VERSION "dbc-export 1 2026.26.6.5"

NS_ :

BS_:

BU_: APP BMS CC CMP CMPD CP DAS DI DIF DIR EPBL EPBR EVSE FC GTW HCML HCMR HVP ICR PCS PCS2 PM PMF PMR PTC SCCM SDCR TAS UMC V2G VC VCBATT VCBATT1 VCBATT2 VCFRONT VCFRONT1 VCLEFT VCRIGHT VCSEC

BO_ 530 BMS_status: 8 BMS
 SG_ BMS_hvacPowerRequest : 0|1@1+ (1,0) [0|1] "" Vector__XXX
 SG_ BMS_notEnoughPowerForDrive : 1|1@1+ (1,0) [0|1] "" Vector__XXX
 SG_ BMS_notEnoughPowerForSupport : 2|1@1+ (1,0) [0|1] "" Vector__XXX
 SG_ BMS_preconditionAllowed : 3|1@1+ (1,0) [0|1] "" Vector__XXX
 SG_ BMS_updateAllowed : 4|1@1+ (1,0) [0|1] "" Vector__XXX
 SG_ BMS_cpMiaOnHvs : 5|1@1+ (1,0) [0|1] "" Vector__XXX
 SG_ BMS_pcsPwmEnabled : 6|1@1+ (1,0) [0|1] "" Vector__XXX
 SG_ BMS_contactorState : 8|3@1+ (1,0) [1|7] "" Vector__XXX
 SG_ BMS_userChargeStatus : 11|3@1+ (1,0) [0|7] "" Vector__XXX
 SG_ BMS_batteryInputPower : 14|16@1+ (0.05,0) [0|3276.7] "kW" Vector__XXX
 SG_ BMS_chargeRequest : 30|1@1+ (1,0) [0|1] "" Vector__XXX
 SG_ BMS_state : 32|4@1+ (1,0) [0|15] "" Vector__XXX
 SG_ BMS_diLimpRequest : 36|1@1+ (1,0) [0|1] "" Vector__XXX
 SG_ BMS_okToShipByAir : 37|1@1+ (1,0) [0|1] "" Vector__XXX
 SG_ BMS_okToShipByLand : 38|1@1+ (1,0) [0|1] "" Vector__XXX
 SG_ BMS_chgPowerAvailable : 39|12@1+ (0.125,0) [0|511.75] "kW" Vector__XXX
 SG_ BMS_acManagerState : 52|4@1+ (1,0) [0|15] "" Vector__XXX
 SG_ BMS_conditioningRequest : 56|1@1+ (1,0) [0|1] "" Vector__XXX
 SG_ BMS_smStateRequest : 57|4@1+ (1,0) [0|15] "" Vector__XXX
 SG_ BMS_hvState : 61|3@1+ (1,0) [0|7] "" Vector__XXX

BO_ 786 BMS_thermalStatus: 8 BMS
 SG_ BMS_thermalStatusMultiplexer M : 0|2@1+ (1,0) [0|3] "" Vector__XXX
 SG_ BMS_inletActiveCoolTargetT m0 : 2|9@1+ (0.25,-25) [-25|100] "DegC" Vector__XXX
 SG_ BMS_inletPassiveTargetT m0 : 11|9@1+ (0.25,-25) [-25|100] "DegC" Vector__XXX
 SG_ BMS_inletActiveHeatTargetT m0 : 20|9@1+ (0.25,-25) [-25|100] "DegC" Vector__XXX
 SG_ BMS_requestDischarge m0 : 29|1@1+ (1,0) [0|1] "" Vector__XXX
 SG_ BMS_activeHeatingWorthwhile m0 : 30|1@1+ (1,0) [0|1] "" Vector__XXX
 SG_ BMS_pcsNoFlowRequest m0 : 31|1@1+ (1,0) [0|1] "" Vector__XXX
 SG_ BMS_minPackTemperature m0 : 32|10@1+ (0.2,-40) [-40|164.6] "DegC" Vector__XXX
 SG_ BMS_noFlowRequest m0 : 42|1@1+ (1,0) [0|1] "" Vector__XXX
 SG_ BMS_maxPackTemperature m0 : 43|11@1+ (0.1,-40) [-40|164.7] "DegC" Vector__XXX
 SG_ BMS_flowRequest m0 : 56|8@1+ (0.25,0) [0|60] "LPM" Vector__XXX
 SG_ BMS_coldStagnationLimit m1 : 2|9@1+ (0.25,-25) [-25|100] "DegC" Vector__XXX
 SG_ BMS_hotStagnationLimit m1 : 11|9@1+ (0.25,-25) [-25|100] "DegC" Vector__XXX
 SG_ BMS_hotCellTempLimit m1 : 20|9@1+ (0.25,-25) [-25|100] "DegC" Vector__XXX
 SG_ BMS_i2tDeratingEnabled m1 : 29|1@1+ (1,0) [0|1] "" Vector__XXX
 SG_ BMS_activeCoolCellReferenceT m1 : 32|9@1+ (0.25,-25) [-25|100] "DegC" Vector__XXX
 SG_ BMS_activeHeatCellTargetT m1 : 41|9@1+ (0.25,-25) [-25|100] "DegC" Vector__XXX
 SG_ BMS_powerDissipation m1 : 50|10@1+ (0.02,0) [0|20] "kW" Vector__XXX

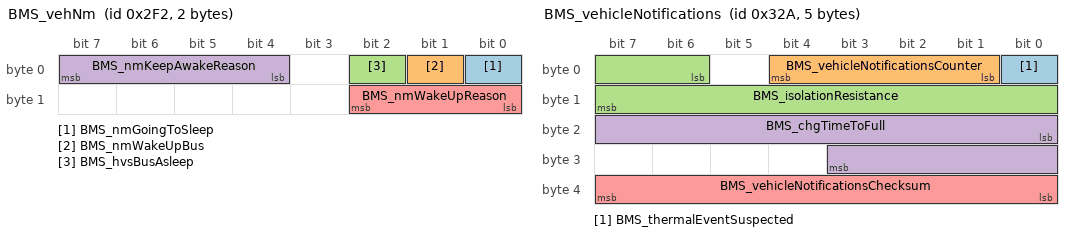
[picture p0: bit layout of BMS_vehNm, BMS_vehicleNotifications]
BO_ 754 BMS_vehNm: 2 BMS
 SG_ BMS_nmGoingToSleep : 0|1@1+ (1,0) [0|1] "" Vector__XXX
 SG_ BMS_nmWakeUpBus : 1|1@1+ (1,0) [0|1] "" Vector__XXX
 SG_ BMS_hvsBusAsleep : 2|1@1+ (1,0) [0|1] "" Vector__XXX
 SG_ BMS_nmKeepAwakeReason : 4|4@1+ (1,0) [1|15] "" Vector__XXX
 SG_ BMS_nmWakeUpReason : 8|3@1+ (1,0) [0|7] "" Vector__XXX

BO_ 810 BMS_vehicleNotifications: 5 BMS
 SG_ BMS_thermalEventSuspected : 0|1@1+ (1,0) [0|1] "" Vector__XXX
 SG_ BMS_vehicleNotificationsCounter : 1|4@1+ (1,0) [0|15] "" Vector__XXX
 SG_ BMS_isolationResistance : 6|10@1+ (10,0) [0|10000] "kOhm" Vector__XXX
 SG_ BMS_chgTimeToFull : 16|12@1+ (0.01666667,0) [0|68.23334698] "Hours" Vector__XXX
 SG_ BMS_vehicleNotificationsChecksum : 32|8@1+ (1,0) [0|255] "" Vector__XXX

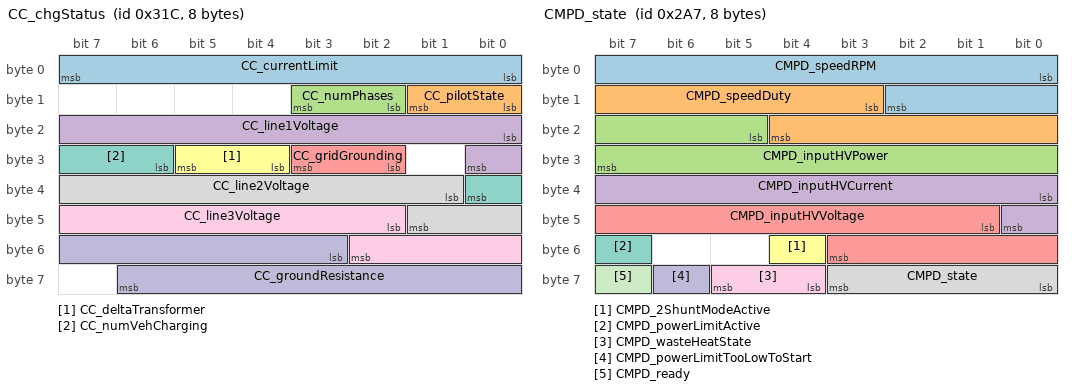
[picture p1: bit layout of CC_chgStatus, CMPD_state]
BO_ 796 CC_chgStatus: 8 CC
 SG_ CC_currentLimit : 0|8@1+ (0.5,0) [0|127] "A" Vector__XXX
 SG_ CC_pilotState : 8|2@1+ (1,0) [0|2] "" Vector__XXX
 SG_ CC_numPhases : 10|2@1+ (1,0) [1|3] "" Vector__XXX
 SG_ CC_line1Voltage : 16|9@1+ (1,0) [0|510] "V" Vector__XXX
 SG_ CC_gridGrounding : 26|2@1+ (1,0) [0|3] "" Vector__XXX
 SG_ CC_deltaTransformer : 28|2@1+ (1,0) [0|3] "" Vector__XXX
 SG_ CC_numVehCharging : 30|3@1+ (1,0) [0|7] "" Vector__XXX
 SG_ CC_line2Voltage : 33|9@1+ (1,0) [0|510] "V" Vector__XXX
 SG_ CC_line3Voltage : 42|9@1+ (1,0) [0|510] "V" Vector__XXX
 SG_ CC_groundResistance : 51|12@1+ (1,0) [0|4094] "kOhm" Vector__XXX

BO_ 797 CC_chgStatus2: 8 CC
 SG_ CC_chgStatus2Index M : 0|8@1+ (1,0) [0|255] "" Vector__XXX
 SG_ CC_buttonState m0 : 8|1@1+ (1,0) [0|1] "" Vector__XXX
 SG_ EVSE_v2xSupport m0 : 9|2@1+ (1,0) [0|3] "" Vector__XXX
 SG_ EVSE_v2xHandshakeStart m0 : 12|1@1+ (1,0) [0|1] "" Vector__XXX
 SG_ EVSE_v2xSessionType m0 : 13|2@1+ (1,0) [1|3] "" Vector__XXX

BO_ 812 CC_logData: 8 CC
 SG_ CC_logIndex M : 0|8@1+ (1,0) [0|255] "" Vector__XXX
 SG_ CC_activeConnectorID m0 : 8|8@1+ (1,0) [0|255] "" Vector__XXX
 SG_ CC_temperature1 m0 : 16|8@1- (1,88) [-40|215] "DegC" Vector__XXX
 SG_ CC_temperature2 m0 : 24|8@1- (1,88) [-40|215] "DegC" Vector__XXX
 SG_ CC_temperature3 m0 : 32|8@1- (1,88) [-40|215] "DegC" Vector__XXX
 SG_ CC_contactor1Closed m0 : 40|2@1+ (1,0) [0|3] "" Vector__XXX
 SG_ CC_contactor2Closed m0 : 42|2@1+ (1,0) [0|3] "" Vector__XXX
 SG_ CC_temperature4 m0 : 44|8@1- (1,88) [-40|215] "DegC" Vector__XXX
 SG_ CC_conn1Current m1 : 8|8@1+ (0.5,0) [0|127] "A" Vector__XXX
 SG_ CC_conn2Current m2 : 8|8@1+ (0.5,0) [0|127] "A" Vector__XXX
 SG_ CC_conn3Current m3 : 8|8@1+ (0.5,0) [0|127] "A" Vector__XXX
 SG_ CC_conn4Current m4 : 8|8@1+ (0.5,0) [0|127] "A" Vector__XXX
 SG_ CC_lifetimei2t m10 : 32|32@1+ (0.1,0) [0|429496729.5] "A2h" Vector__XXX
 SG_ CC_lifetimeCtrCycles m11 : 8|28@1+ (1,0) [0|268435455] "" Vector__XXX
 SG_ CC_lifetimeCtrCyclesLoaded m11 : 36|28@1+ (1,0) [0|268435455] "" Vector__XXX
 SG_ CC_lifetimeAlertCount m12 : 8|28@1+ (1,0) [0|268435455] "" Vector__XXX
 SG_ CC_lifetimeThermalFoldbacks m12 : 36|28@1+ (1,0) [0|268435455] "" Vector__XXX
 SG_ CC_lifetimeAvgStartupTemp m13 : 36|28@1- (0.1,0) [-13421772.8|13421772.7] "degC" Vector__XXX

BO_ 870 CMPD_info: 8 CMPD
 SG_ CMPD_infoIndex M : 0|8@1+ (1,0) [0|255] "" Vector__XXX
 SG_ CMPD_infoBuildType m10 : 8|8@1+ (1,0) [0|255] "" Vector__XXX
 SG_ CMPD_infoBuildConfigId m10 : 16|16@1+ (1,0) [0|65535] "" Vector__XXX
 SG_ CMPD_infoHardwareId m10 : 32|16@1+ (1,0) [0|65535] "" Vector__XXX
 SG_ CMPD_infoComponentId m10 : 48|16@1+ (1,0) [0|65535] "" Vector__XXX
 SG_ CMPD_infoPcbaId m11 : 16|8@1+ (1,0) [0|255] "" Vector__XXX
 SG_ CMPD_infoAssemblyId m11 : 24|8@1+ (1,0) [0|254] "" Vector__XXX
 SG_ CMPD_infoUsageId m11 : 32|16@1+ (1,0) [0|65535] "" Vector__XXX
 SG_ CMPD_infoSubUsageId m11 : 48|16@1+ (1,0) [0|65535] "" Vector__XXX

BO_ 679 CMPD_state: 8 CMPD
 SG_ CMPD_speedRPM : 0|11@1+ (10,0) [0|20000] "RPM" Vector__XXX
 SG_ CMPD_speedDuty : 11|10@1+ (0.1,0) [0|100] "%" Vector__XXX
 SG_ CMPD_inputHVPower : 21|11@1+ (10,0) [0|20000] "W" Vector__XXX
 SG_ CMPD_inputHVCurrent : 32|9@1+ (0.1,0) [0|50] "A" Vector__XXX
 SG_ CMPD_inputHVVoltage : 41|11@1+ (0.5,0) [0|1000] "V" Vector__XXX
 SG_ CMPD_2ShuntModeActive : 52|1@1+ (1,0) [0|1] "" Vector__XXX
 SG_ CMPD_powerLimitActive : 55|1@1+ (1,0) [0|1] "" Vector__XXX
 SG_ CMPD_state : 56|4@1+ (1,0) [0|14] "" Vector__XXX
 SG_ CMPD_wasteHeatState : 60|2@1+ (1,0) [0|3] "" Vector__XXX
 SG_ CMPD_powerLimitTooLowToStart : 62|1@1+ (1,0) [0|1] "" Vector__XXX
 SG_ CMPD_ready : 63|1@1+ (1,0) [0|1] "" Vector__XXX

BO_ 867 CMP_info: 8 CMP
 SG_ CMP_infoIndex M : 0|8@1+ (1,0) [0|255] "" Vector__XXX
 SG_ CMP_infoBuildType m10 : 8|8@1+ (1,0) [0|255] "" Vector__XXX
 SG_ CMP_infoBuildConfigId m10 : 16|16@1+ (1,0) [0|65535] "" Vector__XXX
 SG_ CMP_infoHardwareId m10 : 32|16@1+ (1,0) [0|65535] "" Vector__XXX
 SG_ CMP_infoComponentId m10 : 48|16@1+ (1,0) [0|65535] "" Vector__XXX
 SG_ CMP_infoPcbaId m11 : 16|8@1+ (1,0) [0|255] "" Vector__XXX
 SG_ CMP_infoAssemblyId m11 : 24|8@1+ (1,0) [0|254] "" Vector__XXX
 SG_ CMP_infoUsageId m11 : 32|16@1+ (1,0) [0|65535] "" Vector__XXX
 SG_ CMP_infoSubUsageId m11 : 48|16@1+ (1,0) [0|65535] "" Vector__XXX
 SG_ CMP_infoPlatformType m13 : 8|8@1+ (1,0) [0|255] "" Vector__XXX
 SG_ CMP_infoAppCrc m13 : 32|32@1+ (1,0) [0|4294967295] "" Vector__XXX
 SG_ CMP_infoBootUdsProtoVersion m20 : 8|8@1+ (1,0) [0|255] "" Vector__XXX
 SG_ CMP_infoBootCrc m20 : 32|32@1+ (1,0) [0|4294967295] "" Vector__XXX

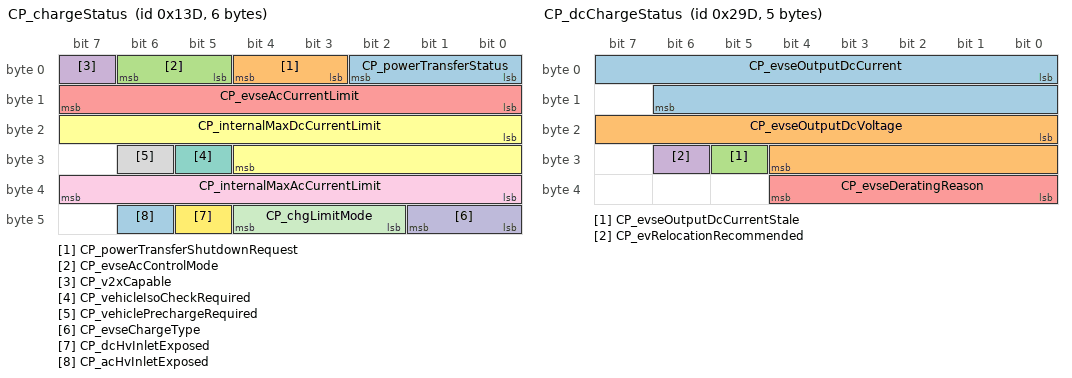
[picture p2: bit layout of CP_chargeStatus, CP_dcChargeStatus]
BO_ 317 CP_chargeStatus: 6 CP
 SG_ CP_powerTransferStatus : 0|3@1+ (1,0) [0|7] "" Vector__XXX
 SG_ CP_powerTransferShutdownRequest : 3|2@1+ (1,0) [0|3] "" Vector__XXX
 SG_ CP_evseAcControlMode : 5|2@1+ (1,0) [0|3] "" Vector__XXX
 SG_ CP_v2xCapable : 7|1@1+ (1,0) [0|1] "" Vector__XXX
 SG_ CP_evseAcCurrentLimit : 8|8@1+ (0.5,0) [0|127.5] "A" Vector__XXX
 SG_ CP_internalMaxDcCurrentLimit : 16|13@1+ (0.25,0) [0|2047.75] "A" Vector__XXX
 SG_ CP_vehicleIsoCheckRequired : 29|1@1+ (1,0) [0|1] "" Vector__XXX
 SG_ CP_vehiclePrechargeRequired : 30|1@1+ (1,0) [0|1] "" Vector__XXX
 SG_ CP_internalMaxAcCurrentLimit : 32|8@1+ (0.5,0) [0|127.5] "A" Vector__XXX
 SG_ CP_evseChargeType : 40|2@1+ (1,0) [0|3] "" Vector__XXX
 SG_ CP_chgLimitMode : 42|3@1+ (1,0) [0|7] "" Vector__XXX
 SG_ CP_dcHvInletExposed : 45|1@1+ (1,0) [0|1] "" Vector__XXX
 SG_ CP_acHvInletExposed : 46|1@1+ (1,0) [0|1] "" Vector__XXX

BO_ 669 CP_dcChargeStatus: 5 CP
 SG_ CP_evseOutputDcCurrent : 0|15@1- (0.125,0) [-2048|2047.875] "A" Vector__XXX
 SG_ CP_evseOutputDcVoltage : 16|13@1+ (0.07324219,0) [0|599.92675822] "V" Vector__XXX
 SG_ CP_evseOutputDcCurrentStale : 29|1@1+ (1,0) [0|1] "" Vector__XXX
 SG_ CP_evRelocationRecommended : 30|1@1+ (1,0) [0|1] "" Vector__XXX
 SG_ CP_evseDeratingReason : 32|5@1+ (1,0) [0|31] "" Vector__XXX

BO_ 541 CP_evseStatus: 8 CP
 SG_ CP_evseAccept : 0|1@1+ (1,0) [0|1] "" Vector__XXX
 SG_ CP_evseRequest : 1|1@1+ (1,0) [0|1] "" Vector__XXX
 SG_ CP_proximity : 2|2@1+ (1,0) [1|3] "" Vector__XXX
 SG_ CP_pilot : 4|3@1+ (1,0) [0|6] "" Vector__XXX
 SG_ CP_digitalCommsEstablished : 7|1@1+ (1,0) [0|1] "" Vector__XXX
 SG_ CP_pilotCurrent : 8|8@1+ (0.5,0) [0|127.5] "A" Vector__XXX
 SG_ CP_cableType : 16|3@1+ (1,0) [0|7] "" Vector__XXX
 SG_ CP_iecPilotState : 19|4@1+ (1,0) [0|15] "" Vector__XXX
 SG_ CP_plcSupported : 23|1@1+ (1,0) [0|1] "" Vector__XXX
 SG_ CP_cableCurrentLimit : 24|7@1+ (1,0) [0|127] "A" Vector__XXX
 SG_ CP_teslaSwcanState : 34|4@1+ (1,0) [0|15] "" Vector__XXX
 SG_ CP_evseChargeType_UI : 38|2@1+ (1,0) [0|3] "" Vector__XXX
 SG_ CP_gbState : 40|4@1+ (1,0) [0|15] "" Vector__XXX
 SG_ CP_gbdcStopChargeReason : 44|4@1+ (1,0) [0|15] "" Vector__XXX
 SG_ CP_gbdcFailureReason : 48|2@1+ (1,0) [0|3] "" Vector__XXX
 SG_ CP_gbdcChargeAttempts : 50|2@1+ (1,0) [0|3] "" Vector__XXX
 SG_ CP_acChargeState : 52|3@1+ (1,0) [0|7] "" Vector__XXX
 SG_ CP_acChargeType : 56|2@1+ (1,0) [0|3] "" Vector__XXX
 SG_ CP_teslaDcState : 58|4@1+ (1,0) [0|15] "" Vector__XXX

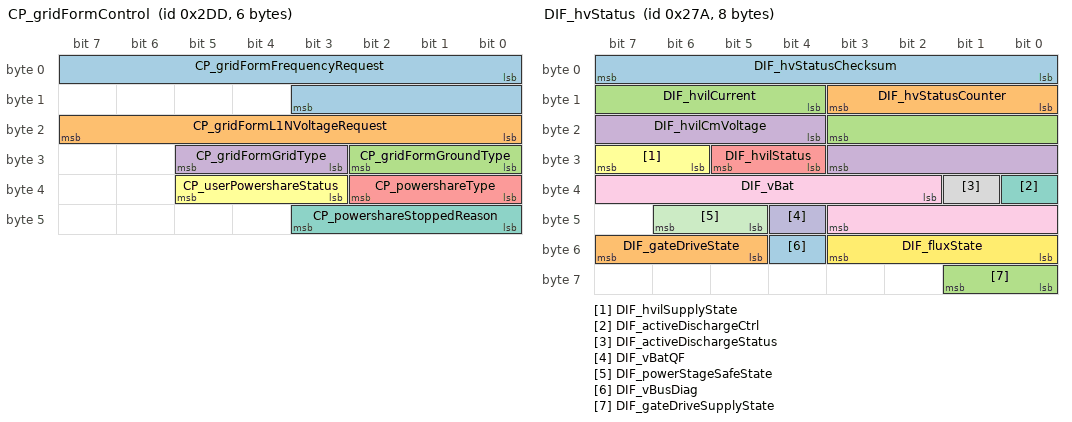
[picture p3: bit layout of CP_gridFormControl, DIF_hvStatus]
BO_ 733 CP_gridFormControl: 6 CP
 SG_ CP_gridFormFrequencyRequest : 0|12@1+ (0.01,40) [40|80.94] "Hz" Vector__XXX
 SG_ CP_gridFormL1NVoltageRequest : 16|8@1+ (1,40) [40|294] "V" Vector__XXX
 SG_ CP_gridFormGroundType : 24|3@1+ (1,0) [1|7] "" Vector__XXX
 SG_ CP_gridFormGridType : 27|3@1+ (1,0) [1|7] "" Vector__XXX
 SG_ CP_powershareType : 32|3@1+ (1,0) [0|7] "" Vector__XXX
 SG_ CP_userPowershareStatus : 35|3@1+ (1,0) [0|7] "" Vector__XXX
 SG_ CP_powershareStoppedReason : 40|4@1+ (1,0) [0|15] "" Vector__XXX

BO_ 1342 CP_info: 8 CP
 SG_ CP_infoIndex M : 0|8@1+ (1,0) [0|255] "" Vector__XXX
 SG_ CP_buildType m10 : 8|3@1+ (1,0) [0|7] "" Vector__XXX
 SG_ CP_buildConfigId m10 : 16|16@1+ (1,0) [0|65535] "" Vector__XXX
 SG_ CP_hardwareId m10 : 32|16@1+ (1,0) [0|65535] "" Vector__XXX
 SG_ CP_componentId m10 : 48|16@1+ (1,0) [0|65535] "" Vector__XXX
 SG_ CP_pcbaId m11 : 16|8@1+ (1,0) [0|255] "" Vector__XXX
 SG_ CP_assemblyId m11 : 24|8@1+ (1,0) [0|255] "" Vector__XXX
 SG_ CP_usageId m11 : 32|16@1+ (1,0) [0|65535] "" Vector__XXX
 SG_ CP_subUsageId m11 : 48|16@1+ (1,0) [0|65535] "" Vector__XXX
 SG_ CP_platformType m13 : 8|8@1+ (1,0) [0|255] "" Vector__XXX
 SG_ CP_appCrc m13 : 32|32@1+ (1,0) [0|4294967295] "" Vector__XXX
 SG_ CP_appGitHash m17 : 8|56@1+ (1,0) [0|7.20575940379e+16] "" Vector__XXX
 SG_ CP_bootGitHash m18 : 8|56@1+ (1,0) [0|7.20575940379e+16] "" Vector__XXX
 SG_ CP_bootUdsProtoVersion m20 : 8|8@1+ (1,0) [0|255] "" Vector__XXX
 SG_ CP_bootCrc m20 : 32|32@1+ (1,0) [0|4294967295] "" Vector__XXX

BO_ 1885 CP_loggingFast: 8 CP
 SG_ CP_loggingFastSelect M : 0|4@1+ (1,0) [0|15] "" Vector__XXX
 SG_ CP_inductiveSensor_raw m0 : 4|28@1+ (1,0) [0|268435455] "" Vector__XXX
 SG_ CP_doorOpenActuationTime m0 : 32|14@1+ (1,0) [0|16383] "ms" Vector__XXX
 SG_ CP_doorCloseActuationTime m0 : 46|14@1+ (1,0) [0|16383] "ms" Vector__XXX
 SG_ CP_chargeCableSecured m0 : 60|1@1+ (1,0) [0|1] "" Vector__XXX
 SG_ CP_chargeCablePresent m0 : 61|1@1+ (1,0) [0|1] "" Vector__XXX
 SG_ CP_latchCheckAvailable m0 : 62|1@1+ (1,0) [0|1] "" Vector__XXX
 SG_ CP_UHF_controlState m2 : 4|4@1+ (1,0) [0|15] "" Vector__XXX
 SG_ CP_proximityV m2 : 8|16@1+ (0.0001,0) [0|6.5535] "V" Vector__XXX
 SG_ CP_proximityV_GBCC1 m2 : 24|14@1+ (0.001,0) [0|13.3] "V" Vector__XXX
 SG_ CP_proximityV_GBCC2 m2 : 38|14@1+ (0.001,0) [0|13.3] "V" Vector__XXX
 SG_ CP_doorPot m2 : 52|12@1+ (0.025,0) [0|100] "%" Vector__XXX
 SG_ CP_doorPresenceSensorV m3 : 4|12@1+ (0.001221,0) [0|4.999995] "V" Vector__XXX
 SG_ CP_doorOpenRequest m3 : 16|4@1+ (1,0) [0|15] "" Vector__XXX
 SG_ CP_doorOpenEndOfDriveReason m3 : 20|3@1+ (1,0) [0|7] "" Vector__XXX
 SG_ CP_coverClosed m3 : 23|1@1+ (1,0) [0|1] "" Vector__XXX
 SG_ CP_doorCloseEndOfDriveReason m3 : 24|3@1+ (1,0) [0|7] "" Vector__XXX
 SG_ CP_doorCloseRequest m3 : 27|5@1+ (1,0) [0|31] "" Vector__XXX
 SG_ CP_latchDisengagingTime m3 : 32|10@1+ (1,0) [0|1023] "ms" Vector__XXX
 SG_ CP_latchEngagingTime m3 : 42|10@1+ (1,0) [0|1023] "ms" Vector__XXX
 SG_ CP_latchDisengagingStopReason m3 : 52|3@1+ (1,0) [0|7] "" Vector__XXX
 SG_ CP_latchEngagingStopReason m3 : 55|3@1+ (1,0) [0|7] "" Vector__XXX
 SG_ CP_pilotUnlatchRequestActive m3 : 58|1@1+ (1,0) [0|1] "" Vector__XXX
 SG_ CP_doorIdDetectionState m3 : 59|2@1+ (1,0) [1|3] "" Vector__XXX
 SG_ CP_doorIdDetectedBin m3 : 61|2@1+ (1,0) [0|3] "" Vector__XXX
 SG_ CP_semiV2LatchNonLinear m3 : 63|1@1+ (1,0) [0|1] "" Vector__XXX

BO_ 989 CP_loggingSlow: 8 CP
 SG_ CP_loggingSlowSelect M : 0|4@1+ (1,0) [0|15] "" Vector__XXX
 SG_ CP_UHF_chipState m3 : 4|3@1+ (1,0) [0|7] "" Vector__XXX
 SG_ CP_UHF_rssi m3 : 8|8@1+ (1,0) [0|255] "" Vector__XXX
 SG_ CP_UHF_rxOverflow m3 : 16|1@1+ (1,0) [0|1] "" Vector__XXX
 SG_ CP_UHF_rxNumBytes m3 : 17|8@1+ (1,0) [0|255] "" Vector__XXX
 SG_ CP_UHF_selfTestRssi m3 : 25|8@1+ (1,0) [0|255] "" Vector__XXX
 SG_ CP_latchI m3 : 33|12@1+ (0.0025,0) [0|10.2375] "A" Vector__XXX
 SG_ CP_inlet1HarnessIdState m3 : 45|2@1+ (1,0) [1|3] "" Vector__XXX
 SG_ CP_inlet1HarnessIdValue m3 : 47|3@1+ (1,0) [0|7] "" Vector__XXX
 SG_ CP_inlet2HarnessIdState m3 : 50|2@1+ (1,0) [1|3] "" Vector__XXX
 SG_ CP_inlet2HarnessIdValue m3 : 52|3@1+ (1,0) [0|7] "" Vector__XXX
 SG_ CP_inletHeaterState m3 : 55|2@1+ (1,0) [0|3] "" Vector__XXX
 SG_ CP_inletHeaterDuty m3 : 57|7@1+ (1,0) [0|100] "%" Vector__XXX
 SG_ CP_5vSwV m4 : 4|8@1+ (0.02745098,0) [0|6.9999999] "V" Vector__XXX
 SG_ CP_boardTemperature m4 : 12|8@1+ (1.29411768913,-50) [-50|280] "C" Vector__XXX
 SG_ CP_refVoltage m4 : 20|8@1+ (0.0070588234812,0) [0|1.79999998771] "V" Vector__XXX
 SG_ CP_doorId_intervalMin10s m4 : 28|8@1+ (0.0196078438312,0) [0|5] "V" Vector__XXX
 SG_ CP_doorId_intervalMax10s m4 : 36|8@1+ (0.0196078438312,0) [0|5] "V" Vector__XXX
 SG_ CP_wakeOnPushCounter m4 : 60|3@1+ (1,0) [0|7] "" Vector__XXX
 SG_ CP_doorPushLockoutActive m4 : 63|1@1+ (1,0) [0|1] "" Vector__XXX
 SG_ CP_nvm_dataValid m5 : 4|1@1+ (1,0) [0|1] "" Vector__XXX
 SG_ CP_nvm_doorOpenCycles m5 : 5|16@1+ (1,0) [0|65535] "" Vector__XXX
 SG_ CP_nvm_doorCloseCycles m5 : 21|16@1+ (1,0) [0|65535] "" Vector__XXX
 SG_ CP_nvm_doorOpen m5 : 37|1@1+ (1,0) [0|1] "" Vector__XXX
 SG_ CP_nvm_doorPresent m5 : 38|1@1+ (1,0) [0|1] "" Vector__XXX
 SG_ CP_nvm_doorPresentValid m5 : 39|1@1+ (1,0) [0|1] "" Vector__XXX
 SG_ CP_nvm_badPilotDiodeDetected m5 : 40|1@1+ (1,0) [0|1] "" Vector__XXX
 SG_ CP_nvm_pilotDiodeFaultCount m5 : 41|3@1+ (1,0) [0|7] "" Vector__XXX
 SG_ CP_doorOpenLimiterMaxCount m5 : 44|4@1+ (1,0) [0|15] "counts" Vector__XXX
 SG_ CP_doorOpenLimiterMaxRequestType m5 : 48|4@1+ (1,0) [0|15] "" Vector__XXX
 SG_ CP_doorCloseLimiterMaxCount m5 : 52|4@1+ (1,0) [0|15] "counts" Vector__XXX
 SG_ CP_doorCloseLimiterMaxRequestTyp m5 : 56|5@1+ (1,0) [0|31] "" Vector__XXX
 SG_ CP_proximityWakeCounter m5 : 61|3@1+ (1,0) [0|7] "" Vector__XXX

BO_ 605 CP_status: 8 CP
 SG_ CP_type : 0|2@1+ (1,0) [0|3] "" Vector__XXX
 SG_ CP_insertEnableLine : 2|1@1+ (1,0) [0|1] "" Vector__XXX
 SG_ CP_latchState : 3|2@1+ (1,0) [1|3] "" Vector__XXX
 SG_ CP_permanentPowerRequest : 5|1@1+ (1,0) [0|1] "" Vector__XXX
 SG_ CP_chargeDoorOpen : 6|1@1+ (1,0) [0|1] "" Vector__XXX
 SG_ CP_doorControlState : 8|3@1+ (1,0) [0|7] "" Vector__XXX
 SG_ CP_doorButtonPressed : 11|1@1+ (1,0) [0|1] "" Vector__XXX
 SG_ CP_swcanRelayClosed : 12|1@1+ (1,0) [0|1] "" Vector__XXX
 SG_ CP_inhibitOta : 13|1@1+ (1,0) [0|1] "" Vector__XXX
 SG_ CP_chargeCableState : 14|2@1+ (1,0) [1|3] "" Vector__XXX
 SG_ CP_latchControlState : 16|3@1+ (1,0) [0|7] "" Vector__XXX
 SG_ CP_ledColor : 19|4@1+ (1,0) [0|15] "" Vector__XXX
 SG_ CP_UHF_handleFound : 23|1@1+ (1,0) [0|1] "" Vector__XXX
 SG_ CP_faultLineSensed : 24|1@1+ (1,0) [0|1] "" Vector__XXX
 SG_ CP_doorPresenceState : 25|3@1+ (1,0) [0|7] "" Vector__XXX
 SG_ CP_inductiveSensorState : 28|3@1+ (1,0) [0|7] "" Vector__XXX
 SG_ CP_chargeDoorOpenUI : 31|1@1+ (1,0) [0|1] "" Vector__XXX
 SG_ CP_vehicleUnlockRequest : 32|1@1+ (1,0) [0|1] "" Vector__XXX
 SG_ CP_coldWeatherMode : 33|1@1+ (1,0) [0|1] "" Vector__XXX
 SG_ CP_latchEngaged : 34|1@1+ (1,0) [0|1] "" Vector__XXX
 SG_ CP_inletHeaterUiState : 37|3@1+ (1,0) [0|7] "" Vector__XXX
 SG_ CP_userEvseModelType : 40|4@1+ (1,0) [0|15] "" Vector__XXX
 SG_ CP_evseGridFormHardwareType : 44|4@1+ (1,0) [0|14] "" Vector__XXX
 SG_ CP_faultLineV : 48|10@1+ (0.00455057667568,0) [0|4.65523993922] "V" Vector__XXX
 SG_ CP_faultLineSetByCP : 58|1@1+ (1,0) [0|1] "" Vector__XXX
 SG_ CP_AuthManagerState : 59|4@1+ (1,0) [0|15] "" Vector__XXX

BO_ 893 CP_thermalStatus: 8 CP
 SG_ CP_thermalStatusSelect M : 0|1@1+ (1,0) [0|1] "" Vector__XXX
 SG_ CP_pinTemperature1 m1 : 8|8@1+ (0.8039216,-55) [-55|149.99] "C" Vector__XXX
 SG_ CP_pinTemperature2 m1 : 16|8@1+ (0.8039216,-55) [-55|149.99] "C" Vector__XXX
 SG_ CP_pinTemperature3 m1 : 24|8@1+ (0.8039216,-55) [-55|149.99] "C" Vector__XXX
 SG_ CP_pinTemperature4 m1 : 32|8@1+ (0.8039216,-55) [-55|149.99] "C" Vector__XXX
 SG_ CP_pinTemp4Velocity m1 : 40|10@1- (0.15748,0) [-80.47228|80.3148] "C/min" Vector__XXX

BO_ 1001 DAS_bodyControls: 8 DAS
 SG_ DAS_headlightRequest : 0|2@1+ (1,0) [0|3] "" Vector__XXX
 SG_ DAS_hazardLightRequest : 2|2@1+ (1,0) [0|2] "" Vector__XXX
 SG_ DAS_wiperSpeed : 4|4@1+ (1,0) [0|15] "" Vector__XXX
 SG_ DAS_turnIndicatorRequest : 8|3@1+ (1,0) [0|7] "" Vector__XXX
 SG_ DAS_highLowBeamDecision : 11|2@1+ (1,0) [0|2] "" Vector__XXX
 SG_ DAS_heaterRequest : 13|2@1+ (1,0) [1|3] "" Vector__XXX
 SG_ DAS_highLowBeamOffReason : 15|3@1+ (1,0) [0|7] "" Vector__XXX
 SG_ DAS_forwardCamHeaterDutyCycle : 18|4@1+ (0.06666667,0) [0|1] "-" Vector__XXX
 SG_ DAS_dynamicBrakeLightRequest : 22|1@1+ (1,0) [0|1] "" Vector__XXX
 SG_ DAS_radarHeaterRequest : 23|1@1+ (1,0) [0|1] "" Vector__XXX
 SG_ DAS_ahlbOverride : 24|1@1+ (1,0) [0|1] "" Vector__XXX
 SG_ DAS_mirrorFoldRequest : 25|2@1+ (1,0) [0|2] "" Vector__XXX
 SG_ DAS_wiperWashRequest : 27|1@1+ (1,0) [0|1] "" Vector__XXX
 SG_ DAS_ulcConfirmationRequestActive : 28|1@1+ (1,0) [0|1] "" Vector__XXX
 SG_ DAS_overrideWiperSetting : 29|1@1+ (1,0) [0|1] "" Vector__XXX
 SG_ DAS_autoWiperState : 30|3@1+ (1,0) [0|7] "" Vector__XXX
 SG_ DAS_turnIndicatorRequestReason : 33|5@1+ (1,0) [0|31] "" Vector__XXX
 SG_ DAS_forwardRadarPowerRequest : 38|1@1+ (1,0) [0|1] "" Vector__XXX
 SG_ DAS_driverDomeLightRequest : 39|1@1+ (1,0) [0|1] "" Vector__XXX
 SG_ DAS_drivePowerStateRequest : 43|1@1+ (1,0) [0|1] "" Vector__XXX
 SG_ DAS_enableIcrDataCollection : 44|1@1+ (1,0) [0|1] "" Vector__XXX
 SG_ DAS_rPillarCamHeaterDutyCycle : 45|4@1+ (0.06666667,0) [0|1] "-" Vector__XXX
 SG_ DAS_adaptiveHighBeamIsFaulted : 49|1@1+ (1,0) [0|1] "" Vector__XXX
 SG_ DAS_restrictDoorReleaseLeft : 50|1@1+ (1,0) [0|1] "" Vector__XXX
 SG_ DAS_restrictDoorReleaseRight : 51|1@1+ (1,0) [0|1] "" Vector__XXX
 SG_ DAS_bodyControlsCounter : 52|4@1+ (1,0) [0|15] "" Vector__XXX
 SG_ DAS_bodyControlsChecksum : 56|8@1+ (1,0) [0|255] "" Vector__XXX

BO_ 634 DIF_hvStatus: 8 DIF
 SG_ DIF_hvStatusChecksum : 0|8@1+ (1,0) [0|255] "" Vector__XXX
 SG_ DIF_hvStatusCounter : 8|4@1+ (1,0) [0|15] "" Vector__XXX
 SG_ DIF_hvilCurrent : 12|8@1+ (0.1,0) [0|25.5] "mA" Vector__XXX
 SG_ DIF_hvilCmVoltage : 20|8@1+ (0.08,0) [0|20.4] "V" Vector__XXX
 SG_ DIF_hvilStatus : 28|2@1+ (1,0) [0|2] "" Vector__XXX
 SG_ DIF_hvilSupplyState : 30|2@1+ (1,0) [0|3] "" Vector__XXX
 SG_ DIF_activeDischargeCtrl : 32|1@1+ (1,0) [0|1] "" Vector__XXX
 SG_ DIF_activeDischargeStatus : 33|1@1+ (1,0) [0|1] "" Vector__XXX
 SG_ DIF_vBat : 34|10@1+ (1,0) [0|1023] "V" Vector__XXX
 SG_ DIF_vBatQF : 44|1@1+ (1,0) [0|1] "" Vector__XXX
 SG_ DIF_powerStageSafeState : 45|2@1+ (1,0) [0|3] "" Vector__XXX
 SG_ DIF_fluxState : 48|4@1+ (1,0) [0|15] "" Vector__XXX
 SG_ DIF_vBusDiag : 52|1@1+ (1,0) [0|1] "" Vector__XXX
 SG_ DIF_gateDriveState : 53|3@1+ (1,0) [0|7] "" Vector__XXX
 SG_ DIF_gateDriveSupplyState : 56|2@1+ (1,0) [0|3] "" Vector__XXX

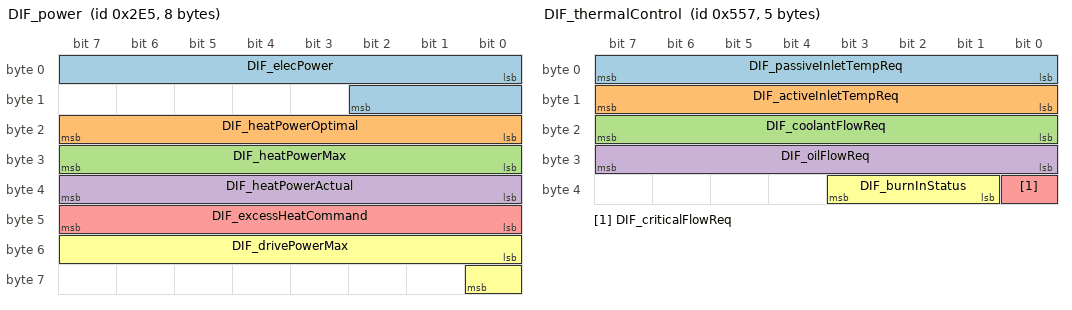
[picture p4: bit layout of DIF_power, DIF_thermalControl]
BO_ 741 DIF_power: 8 DIF
 SG_ DIF_elecPower : 0|11@1- (0.5,0) [-500|500] "kW" Vector__XXX
 SG_ DIF_heatPowerOptimal : 16|8@1+ (0.08,0) [0|20] "kW" Vector__XXX
 SG_ DIF_heatPowerMax : 24|8@1+ (0.08,0) [0|20] "kW" Vector__XXX
 SG_ DIF_heatPowerActual : 32|8@1+ (0.08,0) [0|20] "kW" Vector__XXX
 SG_ DIF_excessHeatCommand : 40|8@1+ (0.08,0) [0|20] "kW" Vector__XXX
 SG_ DIF_drivePowerMax : 48|9@1+ (1,0) [0|400] "kW" Vector__XXX

BO_ 886 DIF_temperature: 8 DIF
 SG_ DIF_tempIndex M : 0|3@1+ (1,0) [0|7] "" Vector__XXX
 SG_ DIF_inverterTQF m0 : 3|2@1+ (1,0) [0|3] "" Vector__XXX
 SG_ DIF_pcbT m0 : 8|8@1+ (1,-40) [-39|215] "DegC" Vector__XXX
 SG_ DIF_inverterT m0 : 16|8@1+ (1,-40) [-40|215] "DegC" Vector__XXX
 SG_ DIF_statorT m0 : 24|8@1+ (1,-40) [-39|215] "DegC" Vector__XXX
 SG_ DIF_dcCapT m0 : 32|8@1+ (1,-40) [-39|215] "DegC" Vector__XXX
 SG_ DIF_heatsinkT m0 : 40|8@1+ (1,-40) [-39|215] "DegC" Vector__XXX
 SG_ DIF_inverterTpct m0 : 48|8@1+ (0.4,0) [0|100] "%" Vector__XXX
 SG_ DIF_statorTpct m0 : 56|8@1+ (0.4,0) [0|100] "%" Vector__XXX
 SG_ DIF_fluidInTemp m2 : 8|8@1+ (1,-40) [-39|215] "DegC" Vector__XXX
 SG_ DIF_normalFetBurnIn m2 : 16|16@1+ (0.00763,0) [0|500] "Hours" Vector__XXX
 SG_ DIF_additionalFetBurnIn m2 : 32|16@1+ (0.00763,0) [0|500] "Hours" Vector__XXX
 SG_ DIF_currentWeibullMiles m3 : 3|16@1+ (8,0) [0|500000] "miles" Vector__XXX
 SG_ DIF_endOfServiceWeibullMiles m3 : 19|16@1+ (8,0) [0|500000] "miles" Vector__XXX
 SG_ DIF_burnInDamageRatio m3 : 35|9@1+ (0.01,0) [0|5] "1" Vector__XXX
 SG_ DIF_inverterSensorEst m3 : 44|8@1+ (1,-40) [-40|120] "C" Vector__XXX
 SG_ DIF_inverterHS1Est m3 : 52|8@1+ (1,-40) [-40|120] "C" Vector__XXX
 SG_ DIF_initialBurnInVehicleOdometer m4 : 8|32@1+ (0.001,0) [0|4294967.294] "km" Vector__XXX
 SG_ DIF_inverterHS2Est m4 : 40|8@1+ (1,-40) [-40|120] "C" Vector__XXX
 SG_ DIF_inverterInletEst m4 : 48|8@1+ (1,-40) [-40|120] "C" Vector__XXX
 SG_ DIF_statorHousingTemp m4 : 56|8@1+ (1,-40) [-39|215] "DegC" Vector__XXX

BO_ 1367 DIF_thermalControl: 5 DIF
 SG_ DIF_passiveInletTempReq : 0|8@1+ (1,-40) [-40|215] "DegC" Vector__XXX
 SG_ DIF_activeInletTempReq : 8|8@1+ (1,-40) [-40|215] "DegC" Vector__XXX
 SG_ DIF_coolantFlowReq : 16|8@1+ (0.2,0) [0|50] "LPM" Vector__XXX
 SG_ DIF_oilFlowReq : 24|8@1+ (0.1,0) [0|25.4] "LPM" Vector__XXX
 SG_ DIF_criticalFlowReq : 32|1@1+ (1,0) [0|1] "" Vector__XXX
 SG_ DIF_burnInStatus : 33|3@1+ (1,0) [0|7] "" Vector__XXX

BO_ 2005 DIR_debug: 8 DIR
 SG_ DIR_debugSelector M : 0|8@1+ (1,0) [0|255] "" Vector__XXX
 SG_ DIR_phaseOutBusbarTemp m70 : 8|8@1+ (1,-40) [-39|215] "DegC" Vector__XXX
 SG_ DIR_phaseOutBusbarWeldTemp m70 : 16|8@1+ (1,-40) [-39|215] "DegC" Vector__XXX
 SG_ DIR_phaseOutLugTemp m70 : 24|8@1+ (1,-40) [-39|215] "DegC" Vector__XXX
 SG_ DIR_dcLinkCapTemp m70 : 32|8@1+ (1,-40) [-39|215] "DegC" Vector__XXX
 SG_ DIR_hvDcCableTemp m70 : 40|8@1+ (1,-40) [-39|215] "DegC" Vector__XXX
 SG_ DIR_negDcBusbarTemp m70 : 48|8@1+ (1,-40) [-39|215] "DegC" Vector__XXX
 SG_ DIR_posDcBusbarTemp m70 : 56|8@1+ (1,-40) [-39|215] "DegC" Vector__XXX
 SG_ DIR_statorEndWindingTemp m72 : 8|8@1+ (1,-40) [-39|215] "DegC" Vector__XXX
 SG_ DIR_rotorMaxMagnetTemp m72 : 16|8@1+ (1,-40) [-39|215] "DegC" Vector__XXX
 SG_ DIR_lightSenseV m72 : 24|6@1+ (0.1,0) [0|3.3] "V" Vector__XXX
 SG_ DIR_pyroSenseV m72 : 30|8@1+ (0.02,0) [0|3.3] "V" Vector__XXX
 SG_ DIR_statorSlotWindingTemp m72 : 46|8@1+ (1,-40) [-39|215] "DegC" Vector__XXX
 SG_ DIR_intervalMaxHvBusV m72 : 54|10@1+ (1,0) [0|1023] "V" Vector__XXX

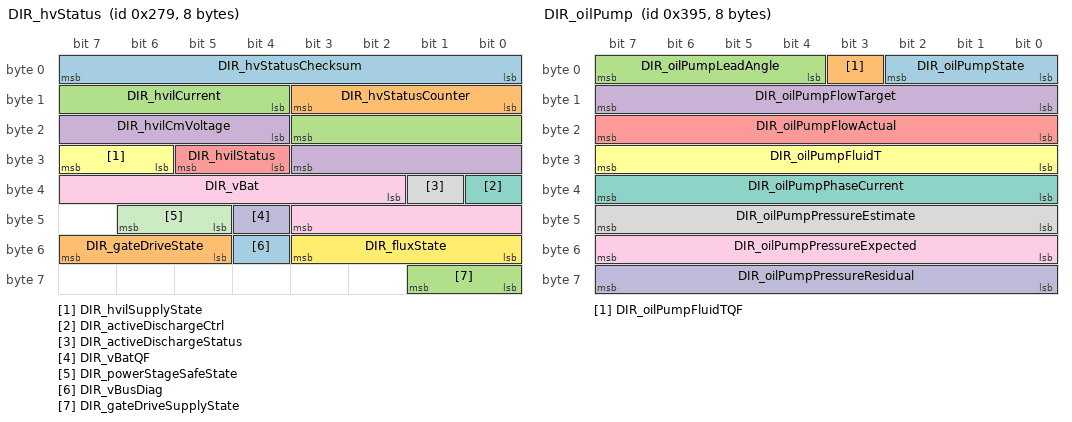
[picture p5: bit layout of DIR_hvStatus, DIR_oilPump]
BO_ 633 DIR_hvStatus: 8 DIR
 SG_ DIR_hvStatusChecksum : 0|8@1+ (1,0) [0|255] "" Vector__XXX
 SG_ DIR_hvStatusCounter : 8|4@1+ (1,0) [0|15] "" Vector__XXX
 SG_ DIR_hvilCurrent : 12|8@1+ (0.1,0) [0|25.5] "mA" Vector__XXX
 SG_ DIR_hvilCmVoltage : 20|8@1+ (0.08,0) [0|20.4] "V" Vector__XXX
 SG_ DIR_hvilStatus : 28|2@1+ (1,0) [0|2] "" Vector__XXX
 SG_ DIR_hvilSupplyState : 30|2@1+ (1,0) [0|3] "" Vector__XXX
 SG_ DIR_activeDischargeCtrl : 32|1@1+ (1,0) [0|1] "" Vector__XXX
 SG_ DIR_activeDischargeStatus : 33|1@1+ (1,0) [0|1] "" Vector__XXX
 SG_ DIR_vBat : 34|10@1+ (1,0) [0|1023] "V" Vector__XXX
 SG_ DIR_vBatQF : 44|1@1+ (1,0) [0|1] "" Vector__XXX
 SG_ DIR_powerStageSafeState : 45|2@1+ (1,0) [0|3] "" Vector__XXX
 SG_ DIR_fluxState : 48|4@1+ (1,0) [0|15] "" Vector__XXX
 SG_ DIR_vBusDiag : 52|1@1+ (1,0) [0|1] "" Vector__XXX
 SG_ DIR_gateDriveState : 53|3@1+ (1,0) [0|7] "" Vector__XXX
 SG_ DIR_gateDriveSupplyState : 56|2@1+ (1,0) [0|3] "" Vector__XXX

BO_ 821 DIR_info: 8 DIR
 SG_ DIR_infoIndex M : 0|8@1+ (1,0) [0|255] "" Vector__XXX
 SG_ DIR_buildType m10 : 8|3@1+ (1,0) [0|7] "" Vector__XXX
 SG_ DIR_buildConfigurationId m10 : 16|16@1+ (1,0) [0|65535] "" Vector__XXX
 SG_ DIR_hardwareId m10 : 32|8@1+ (1,0) [0|252] "" Vector__XXX
 SG_ DIR_componentId m10 : 48|16@1+ (1,0) [0|65535] "" Vector__XXX
 SG_ DIR_pcbaId m11 : 16|8@1+ (1,0) [0|255] "" Vector__XXX
 SG_ DIR_assemblyId m11 : 24|8@1+ (1,0) [0|255] "" Vector__XXX
 SG_ DIR_usageId m11 : 32|16@1+ (1,0) [0|65535] "" Vector__XXX
 SG_ DIR_subUsageId m11 : 48|16@1+ (1,0) [0|65535] "" Vector__XXX
 SG_ DIR_motorType m12 : 8|6@1+ (1,0) [1|63] "" Vector__XXX
 SG_ DIR_siliconType m12 : 16|1@1+ (1,0) [0|1] "" Vector__XXX
 SG_ DIR_mechSafeStateType m12 : 24|2@1+ (1,0) [1|3] "" Vector__XXX
 SG_ DIR_applicationCrc m13 : 32|32@1+ (1,0) [0|4294967295] "" Vector__XXX
 SG_ DIR_oilPumpBuildType m16 : 8|3@1+ (1,0) [0|7] "" Vector__XXX
 SG_ DIR_oilPumpAppCrc m16 : 16|32@1+ (1,0) [0|4294967295] "" Vector__XXX
 SG_ DIR_FPGA_version m16 : 48|8@1+ (1,0) [0|254] "" Vector__XXX
 SG_ DIR_appGitHash m17 : 8|56@1+ (1,0) [0|7.20575940379e+16] "" Vector__XXX
 SG_ DIR_bootGitHash m18 : 8|56@1+ (1,0) [0|7.20575940379e+16] "" Vector__XXX
 SG_ DIR_infoBootLdUdsProtocolVersion m20 : 8|8@1+ (1,0) [0|255] "" Vector__XXX
 SG_ DIR_bootloaderCrc m20 : 32|32@1+ (1,0) [0|4294967295] "" Vector__XXX
 SG_ DIR_oilPumpPcbaId m33 : 8|8@1+ (1,0) [0|255] "" Vector__XXX
 SG_ DIR_oilPumpAssemblyId m33 : 16|8@1+ (1,0) [0|255] "" Vector__XXX
 SG_ DIR_oilPumpUsageId m33 : 24|16@1+ (1,0) [0|65535] "" Vector__XXX
 SG_ DIR_refRotorFlux m35 : 8|16@1+ (0.0001,0) [0|6.5535] "Wb" Vector__XXX
 SG_ DIR_refRotorOffset m35 : 24|12@1- (0.1,0) [-180|180] "deg" Vector__XXX
 SG_ DIR_speedWearTotal m36 : 8|8@1+ (0.4,0) [0|100] "%" Vector__XXX
 SG_ DIR_torqueWearTotal m36 : 24|8@1+ (0.02,0) [0|5.08] "1" Vector__XXX

BO_ 917 DIR_oilPump: 8 DIR
 SG_ DIR_oilPumpState : 0|3@1+ (1,0) [0|6] "" Vector__XXX
 SG_ DIR_oilPumpFluidTQF : 3|1@1+ (1,0) [0|1] "" Vector__XXX
 SG_ DIR_oilPumpLeadAngle : 4|4@1+ (1.875,0) [0|28.125] "degrees" Vector__XXX
 SG_ DIR_oilPumpFlowTarget : 8|8@1+ (0.1,0) [0|25.4] "LPM" Vector__XXX
 SG_ DIR_oilPumpFlowActual : 16|8@1+ (0.1,0) [0|25.4] "LPM" Vector__XXX
 SG_ DIR_oilPumpFluidT : 24|8@1+ (1,-40) [-40|214] "DegC" Vector__XXX
 SG_ DIR_oilPumpPhaseCurrent : 32|8@1+ (0.1,0) [0|25.4] "A" Vector__XXX
 SG_ DIR_oilPumpPressureEstimate : 40|8@1+ (2,0) [0|500] "kPa" Vector__XXX
 SG_ DIR_oilPumpPressureExpected : 48|8@1+ (2,0) [0|500] "kPa" Vector__XXX
 SG_ DIR_oilPumpPressureResidual : 56|8@1+ (4,-500) [-500|500] "kPa" Vector__XXX

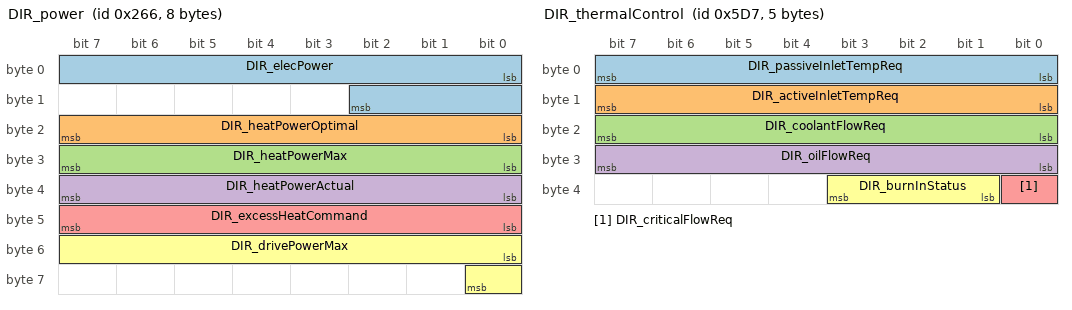
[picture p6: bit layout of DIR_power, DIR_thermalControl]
BO_ 614 DIR_power: 8 DIR
 SG_ DIR_elecPower : 0|11@1- (0.5,0) [-500|500] "kW" Vector__XXX
 SG_ DIR_heatPowerOptimal : 16|8@1+ (0.08,0) [0|20] "kW" Vector__XXX
 SG_ DIR_heatPowerMax : 24|8@1+ (0.08,0) [0|20] "kW" Vector__XXX
 SG_ DIR_heatPowerActual : 32|8@1+ (0.08,0) [0|20] "kW" Vector__XXX
 SG_ DIR_excessHeatCommand : 40|8@1+ (0.08,0) [0|20] "kW" Vector__XXX
 SG_ DIR_drivePowerMax : 48|9@1+ (1,0) [0|400] "kW" Vector__XXX

BO_ 789 DIR_temperature: 8 DIR
 SG_ DIR_tempIndex M : 0|3@1+ (1,0) [0|7] "" Vector__XXX
 SG_ DIR_inverterTQF m0 : 3|2@1+ (1,0) [0|3] "" Vector__XXX
 SG_ DIR_pcbT m0 : 8|8@1+ (1,-40) [-39|215] "DegC" Vector__XXX
 SG_ DIR_inverterT m0 : 16|8@1+ (1,-40) [-40|215] "DegC" Vector__XXX
 SG_ DIR_statorT m0 : 24|8@1+ (1,-40) [-39|215] "DegC" Vector__XXX
 SG_ DIR_dcCapT m0 : 32|8@1+ (1,-40) [-39|215] "DegC" Vector__XXX
 SG_ DIR_heatsinkT m0 : 40|8@1+ (1,-40) [-39|215] "DegC" Vector__XXX
 SG_ DIR_inverterTpct m0 : 48|8@1+ (0.4,0) [0|100] "%" Vector__XXX
 SG_ DIR_statorTpct m0 : 56|8@1+ (0.4,0) [0|100] "%" Vector__XXX
 SG_ DIR_fluidInTemp m2 : 8|8@1+ (1,-40) [-39|215] "DegC" Vector__XXX
 SG_ DIR_normalFetBurnIn m2 : 16|16@1+ (0.00763,0) [0|500] "Hours" Vector__XXX
 SG_ DIR_additionalFetBurnIn m2 : 32|16@1+ (0.00763,0) [0|500] "Hours" Vector__XXX
 SG_ DIR_currentWeibullMiles m3 : 3|16@1+ (8,0) [0|500000] "miles" Vector__XXX
 SG_ DIR_endOfServiceWeibullMiles m3 : 19|16@1+ (8,0) [0|500000] "miles" Vector__XXX
 SG_ DIR_burnInDamageRatio m3 : 35|9@1+ (0.01,0) [0|5] "1" Vector__XXX
 SG_ DIR_inverterSensorEst m3 : 44|8@1+ (1,-40) [-40|120] "C" Vector__XXX
 SG_ DIR_inverterHS1Est m3 : 52|8@1+ (1,-40) [-40|120] "C" Vector__XXX
 SG_ DIR_initialBurnInVehicleOdometer m4 : 8|32@1+ (0.001,0) [0|4294967.294] "km" Vector__XXX
 SG_ DIR_inverterHS2Est m4 : 40|8@1+ (1,-40) [-40|120] "C" Vector__XXX
 SG_ DIR_inverterInletEst m4 : 48|8@1+ (1,-40) [-40|120] "C" Vector__XXX
 SG_ DIR_statorHousingTemp m4 : 56|8@1+ (1,-40) [-39|215] "DegC" Vector__XXX

BO_ 1495 DIR_thermalControl: 5 DIR
 SG_ DIR_passiveInletTempReq : 0|8@1+ (1,-40) [-40|215] "DegC" Vector__XXX
 SG_ DIR_activeInletTempReq : 8|8@1+ (1,-40) [-40|215] "DegC" Vector__XXX
 SG_ DIR_coolantFlowReq : 16|8@1+ (0.2,0) [0|50] "LPM" Vector__XXX
 SG_ DIR_oilFlowReq : 24|8@1+ (0.1,0) [0|25.4] "LPM" Vector__XXX
 SG_ DIR_criticalFlowReq : 32|1@1+ (1,0) [0|1] "" Vector__XXX
 SG_ DIR_burnInStatus : 33|3@1+ (1,0) [0|7] "" Vector__XXX

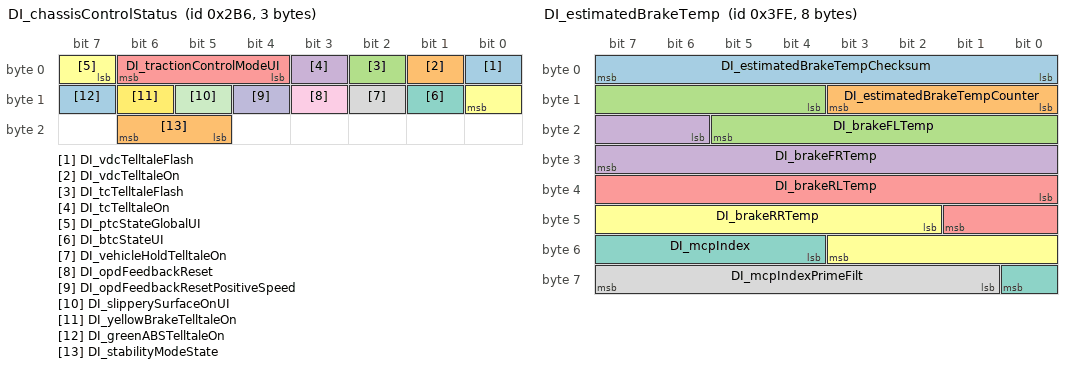
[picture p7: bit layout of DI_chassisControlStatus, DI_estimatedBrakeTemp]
BO_ 694 DI_chassisControlStatus: 3 DI
 SG_ DI_vdcTelltaleFlash : 0|1@1+ (1,0) [0|1] "" Vector__XXX
 SG_ DI_vdcTelltaleOn : 1|1@1+ (1,0) [0|1] "" Vector__XXX
 SG_ DI_tcTelltaleFlash : 2|1@1+ (1,0) [0|1] "" Vector__XXX
 SG_ DI_tcTelltaleOn : 3|1@1+ (1,0) [0|1] "" Vector__XXX
 SG_ DI_tractionControlModeUI : 4|3@1+ (1,0) [0|7] "" Vector__XXX
 SG_ DI_ptcStateGlobalUI : 7|2@1+ (1,0) [0|2] "" Vector__XXX
 SG_ DI_btcStateUI : 9|1@1+ (1,0) [0|1] "" Vector__XXX
 SG_ DI_vehicleHoldTelltaleOn : 10|1@1+ (1,0) [0|1] "" Vector__XXX
 SG_ DI_opdFeedbackReset : 11|1@1+ (1,0) [0|1] "" Vector__XXX
 SG_ DI_opdFeedbackResetPositiveSpeed : 12|1@1+ (1,0) [0|1] "" Vector__XXX
 SG_ DI_slipperySurfaceOnUI : 13|1@1+ (1,0) [0|1] "" Vector__XXX
 SG_ DI_yellowBrakeTelltaleOn : 14|1@1+ (1,0) [0|1] "" Vector__XXX
 SG_ DI_greenABSTelltaleOn : 15|1@1+ (1,0) [0|1] "" Vector__XXX
 SG_ DI_stabilityModeState : 21|2@1+ (1,0) [0|3] "" Vector__XXX

BO_ 2007 DI_debug: 8 DI
 SG_ DI_debugSelector M : 0|8@1+ (1,0) [0|255] "" Vector__XXX
 SG_ DI_regenBackfillCmd m39 : 8|13@1+ (2,0) [0|16382] "Nm" Vector__XXX
 SG_ DI_regenBackfillUnavailableReaso m39 : 21|5@1+ (1,0) [0|31] "" Vector__XXX
 SG_ DI_regenBackfillAbsSatState m39 : 26|2@1+ (1,0) [0|3] "" Vector__XXX
 SG_ DI_sysHeatPowerOptimal m50 : 8|8@1+ (0.08,0) [0|20] "kW" Vector__XXX
 SG_ DI_sysPostPedalMinTorque m53 : 8|15@1+ (0.5,-13000) [-13000|0] "Nm" Vector__XXX
 SG_ DI_sysPostPedalMaxTorque m53 : 24|15@1+ (0.5,0) [0|13000] "Nm" Vector__XXX
 SG_ DI_systemTorqueCommand m53 : 40|16@1- (0.5,0) [-13000|13000] "Nm" Vector__XXX

BO_ 1022 DI_estimatedBrakeTemp: 8 DI
 SG_ DI_estimatedBrakeTempChecksum : 0|8@1+ (1,0) [0|255] "" Vector__XXX
 SG_ DI_estimatedBrakeTempCounter : 8|4@1+ (1,0) [0|15] "" Vector__XXX
 SG_ DI_brakeFLTemp : 12|10@1+ (1,-40) [-40|982] "DegC" Vector__XXX
 SG_ DI_brakeFRTemp : 22|10@1+ (1,-40) [-40|982] "DegC" Vector__XXX
 SG_ DI_brakeRLTemp : 32|10@1+ (1,-40) [-40|982] "DegC" Vector__XXX
 SG_ DI_brakeRRTemp : 42|10@1+ (1,-40) [-40|982] "DegC" Vector__XXX
 SG_ DI_mcpIndex : 52|5@1- (0.05,0.75) [-0.05|1.5] "ratio" Vector__XXX
 SG_ DI_mcpIndexPrimeFilt : 57|7@1- (0.015,0.9) [-0.05|1.84] "ratio" Vector__XXX

BO_ 1623 DI_info: 8 DI
 SG_ DI_infoIndex M : 0|8@1+ (1,0) [0|255] "" Vector__XXX
 SG_ DI_buildType m10 : 8|3@1+ (1,0) [0|7] "" Vector__XXX
 SG_ DI_buildConfigurationId m10 : 16|16@1+ (1,0) [0|65535] "" Vector__XXX
 SG_ DI_hardwareId m10 : 32|8@1+ (1,0) [0|252] "" Vector__XXX
 SG_ DI_componentId m10 : 48|16@1+ (1,0) [0|65535] "" Vector__XXX
 SG_ DI_pcbaId m11 : 16|8@1+ (1,0) [0|255] "" Vector__XXX
 SG_ DI_assemblyId m11 : 24|8@1+ (1,0) [0|255] "" Vector__XXX
 SG_ DI_usageId m11 : 32|16@1+ (1,0) [0|65535] "" Vector__XXX
 SG_ DI_subUsageId m11 : 48|16@1+ (1,0) [0|65535] "" Vector__XXX
 SG_ DI_applicationCrc m13 : 32|32@1+ (1,0) [0|4294967295] "" Vector__XXX
 SG_ DI_appGitHash m17 : 8|56@1+ (1,0) [0|7.20575940379e+16] "" Vector__XXX
 SG_ DI_bootGitHash m18 : 8|56@1+ (1,0) [0|7.20575940379e+16] "" Vector__XXX

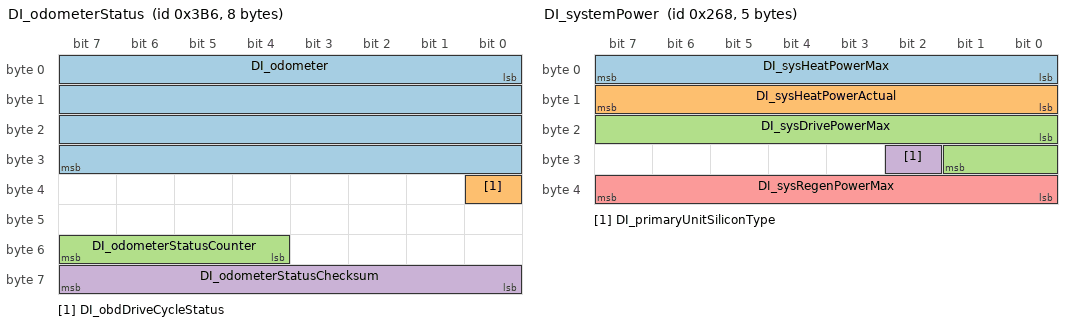
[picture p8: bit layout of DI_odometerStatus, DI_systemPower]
BO_ 950 DI_odometerStatus: 8 DI
 SG_ DI_odometer : 0|32@1+ (0.001,0) [0|4294967.294] "km" Vector__XXX
 SG_ DI_obdDriveCycleStatus : 32|1@1+ (1,0) [0|1] "" Vector__XXX
 SG_ DI_odometerStatusCounter : 52|4@1+ (1,0) [0|15] "" Vector__XXX
 SG_ DI_odometerStatusChecksum : 56|8@1+ (1,0) [0|255] "" Vector__XXX

BO_ 296 DI_systemLimits: 6 DI
 SG_ DI_limitRegenPower : 0|1@1+ (1,0) [0|1] "" Vector__XXX
 SG_ DI_limitIBat : 1|1@1+ (1,0) [0|1] "" Vector__XXX
 SG_ DI_limitVBatLow : 2|1@1+ (1,0) [0|1] "" Vector__XXX
 SG_ DI_limitVBatHigh : 3|1@1+ (1,0) [0|1] "" Vector__XXX
 SG_ DI_limitObstacleDetection : 4|1@1+ (1,0) [0|1] "" Vector__XXX
 SG_ DI_limitSystemLimp : 5|1@1+ (1,0) [0|1] "" Vector__XXX
 SG_ DI_limitSystemGPO : 6|1@1+ (1,0) [0|1] "" Vector__XXX
 SG_ DI_limitShift : 7|1@1+ (1,0) [0|1] "" Vector__XXX
 SG_ DI_limitDriveTorque : 8|1@1+ (1,0) [0|1] "" Vector__XXX
 SG_ DI_limitRegenTorque : 9|1@1+ (1,0) [0|1] "" Vector__XXX
 SG_ DI_limitVehicleSpeed : 10|1@1+ (1,0) [0|1] "" Vector__XXX
 SG_ DI_limitBmsMiaFreeze : 11|1@1+ (1,0) [0|1] "" Vector__XXX
 SG_ DI_limitSystemSpinDownLearning : 12|1@1+ (1,0) [0|1] "" Vector__XXX
 SG_ DI_limitCdp : 13|1@1+ (1,0) [0|1] "" Vector__XXX
 SG_ DI_vehicleSpeedLimitType : 14|2@1+ (1,0) [0|3] "" Vector__XXX
 SG_ DI_vehicleSpeedLimit : 16|9@1+ (1,0) [0|510] "kph" Vector__XXX
 SG_ DI_vehicleSpeedLimitReason : 25|5@1+ (1,0) [0|31] "" Vector__XXX
 SG_ DI_proximity : 30|1@1+ (1,0) [0|1] "" Vector__XXX
 SG_ DI_limitClosureNotClosed : 31|1@1+ (1,0) [0|1] "" Vector__XXX
 SG_ DI_undersideAbuse : 32|1@1+ (1,0) [0|1] "" Vector__XXX
 SG_ DI_immobilizerAuthLevel : 33|2@1+ (1,0) [0|3] "" Vector__XXX
 SG_ DI_manualRecoveryDistanceRemaini : 40|7@1+ (5,0) [0|500] "m" Vector__XXX
 SG_ DI_restrictedDrivingMode : 47|1@1+ (1,0) [0|1] "" Vector__XXX

BO_ 616 DI_systemPower: 5 DI
 SG_ DI_sysHeatPowerMax : 0|8@1+ (0.08,0) [0|20] "kW" Vector__XXX
 SG_ DI_sysHeatPowerActual : 8|8@1+ (0.08,0) [0|20] "kW" Vector__XXX
 SG_ DI_sysDrivePowerMax : 16|10@1+ (1,0) [0|1023] "kW" Vector__XXX
 SG_ DI_primaryUnitSiliconType : 26|1@1+ (1,0) [0|1] "" Vector__XXX
 SG_ DI_sysRegenPowerMax : 32|8@1+ (1,-100) [-100|0] "kW" Vector__XXX

BO_ 280 DI_systemStatus: 8 DI
 SG_ DI_systemStatusChecksum : 0|8@1+ (1,0) [0|255] "" Vector__XXX
 SG_ DI_systemStatusCounter : 8|4@1+ (1,0) [0|15] "" Vector__XXX
 SG_ DI_secondaryGearControlStatus : 12|1@1+ (1,0) [0|1] "" Vector__XXX
 SG_ DI_immobilizerState : 13|3@1+ (1,0) [1|7] "" Vector__XXX
 SG_ DI_systemState : 16|3@1+ (1,0) [0|7] "" Vector__XXX
 SG_ DI_brakePedalState : 19|2@1+ (1,0) [0|3] "" Vector__XXX
 SG_ DI_gear : 21|3@1+ (1,0) [0|6] "" Vector__XXX
 SG_ DI_driveBlocked : 24|3@1+ (1,0) [0|7] "" Vector__XXX
 SG_ DI_hvilSystemStatus : 27|2@1+ (1,0) [0|2] "" Vector__XXX
 SG_ DI_driveModeState : 29|1@1+ (1,0) [0|1] "" Vector__XXX
 SG_ DI_shiftRequestType : 30|2@1+ (1,0) [0|3] "" Vector__XXX
 SG_ DI_accelPedalPos : 32|8@1+ (0.4,0) [0|100] "%" Vector__XXX
 SG_ DI_tractionControlMode : 40|3@1+ (1,0) [0|7] "" Vector__XXX
 SG_ DI_dynoModeAvailable : 43|1@1+ (1,0) [0|1] "" Vector__XXX
 SG_ DI_epbRequest : 44|2@1+ (1,0) [0|3] "" Vector__XXX
 SG_ DI_brakeSource : 46|1@1+ (1,0) [0|1] "" Vector__XXX
 SG_ DI_keepDrivePowerStateRequest : 47|1@1+ (1,0) [0|1] "" Vector__XXX
 SG_ DI_trackModeState : 48|2@1+ (1,0) [0|3] "" Vector__XXX
 SG_ DI_autonomyControlActive : 50|1@1+ (1,0) [0|1] "" Vector__XXX
 SG_ DI_regenLight : 51|1@1+ (1,0) [0|1] "" Vector__XXX
 SG_ DI_vehicleAcceleration : 52|12@1- (0.01,0) [-20.47|20.47] "m/s^2" Vector__XXX

BO_ 1992 EPBL_info: 8 EPBL
 SG_ EPBL_infoIndex M : 0|8@1+ (1,0) [0|255] "" Vector__XXX
 SG_ EPBL_infoBuildType m10 : 8|3@1+ (1,0) [0|7] "" Vector__XXX
 SG_ EPBL_infoBuildConfigId m10 : 16|16@1+ (1,0) [0|65535] "" Vector__XXX
 SG_ EPBL_infoHardwareId m10 : 32|16@1+ (1,0) [0|65535] "" Vector__XXX
 SG_ EPBL_infoComponentId m10 : 48|16@1+ (1,0) [0|65535] "" Vector__XXX
 SG_ EPBL_infoPcbaId m11 : 8|8@1+ (1,0) [0|255] "" Vector__XXX
 SG_ EPBL_infoAssemblyId m11 : 16|8@1+ (1,0) [0|254] "" Vector__XXX
 SG_ EPBL_infoUsageId m11 : 24|16@1+ (1,0) [0|65535] "" Vector__XXX
 SG_ EPBL_infoSubUsageId m11 : 40|16@1+ (1,0) [0|65535] "" Vector__XXX
 SG_ EPBL_infoAppCrc m13 : 8|32@1+ (1,0) [0|4294967295] "" Vector__XXX
 SG_ EPBL_infoAppGitHash m17 : 8|56@1+ (1,0) [0|7.20575940379e+16] "" Vector__XXX
 SG_ EPBL_infoBootGitHash m18 : 8|56@1+ (1,0) [0|7.20575940379e+16] "" Vector__XXX
 SG_ EPBL_infoPlatformType m19 : 8|8@1+ (1,0) [0|255] "" Vector__XXX
 SG_ EPBL_infoBootUdsProtoVersion m20 : 8|16@1+ (1,0) [0|65535] "" Vector__XXX
 SG_ EPBL_infoBootCrc m20 : 24|32@1+ (1,0) [0|4294967295] "" Vector__XXX

BO_ 648 EPBL_internalStatus: 8 EPBL
 SG_ EPBL_unitStatus : 0|5@1+ (1,0) [0|31] "" Vector__XXX
 SG_ EPBL_unitFaultStatus : 5|2@1+ (1,0) [0|3] "" Vector__XXX
 SG_ EPBL_summonState : 8|3@1+ (1,0) [0|7] "" Vector__XXX
 SG_ EPBL_disconnected : 11|1@1+ (1,0) [0|1] "" Vector__XXX
 SG_ EPBL_pistonTouchingRotor : 12|1@1+ (1,0) [0|1] "" Vector__XXX
 SG_ EPBL_csmFaultReason : 13|5@1+ (1,0) [0|31] "" Vector__XXX
 SG_ EPBL_esmOperationTrigger : 18|6@1+ (1,0) [0|63] "" Vector__XXX
 SG_ EPBL_summonFaultReason : 24|5@1+ (1,0) [0|31] "" Vector__XXX
 SG_ EPBL_localServiceModeActive : 29|1@1+ (1,0) [0|1] "" Vector__XXX
 SG_ EPBL_localCdpState : 30|2@1+ (1,0) [0|3] "" Vector__XXX
 SG_ EPBL_chimeRequestLocal : 33|3@1+ (1,0) [0|7] "" Vector__XXX
 SG_ EPBL_telltaleLocal : 39|3@1+ (1,0) [0|6] "" Vector__XXX
 SG_ EPBL_driverIsLeavingLocal : 42|1@1+ (1,0) [0|1] "" Vector__XXX
 SG_ EPBL_driverIsLeavingAnySpeedLoca : 43|1@1+ (1,0) [0|1] "" Vector__XXX
 SG_ EPBL_internalCDPRequest : 44|1@1+ (1,0) [0|1] "" Vector__XXX
 SG_ EPBL_esmSpeedClass : 45|3@1+ (1,0) [0|7] "" Vector__XXX
 SG_ EPBL_learnedEpbConfig : 48|4@1+ (1,0) [0|15] "" Vector__XXX
 SG_ EPBL_internalStatusCounter : 52|4@1+ (1,0) [0|15] "" Vector__XXX
 SG_ EPBL_internalStatusChecksum : 56|8@1+ (1,0) [0|255] "" Vector__XXX

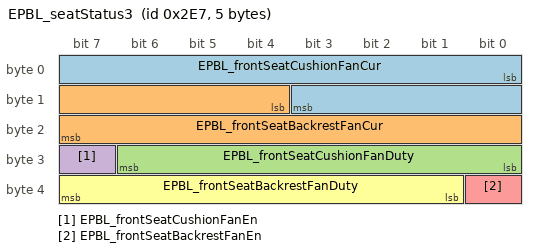
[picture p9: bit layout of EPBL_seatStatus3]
BO_ 743 EPBL_seatStatus3: 5 EPBL
 SG_ EPBL_frontSeatCushionFanCur : 0|12@1+ (0.01,0) [0|40.95] "A" Vector__XXX
 SG_ EPBL_frontSeatBackrestFanCur : 12|12@1+ (0.01,0) [0|40.95] "A" Vector__XXX
 SG_ EPBL_frontSeatCushionFanDuty : 24|7@1+ (1,0) [0|100] "%" Vector__XXX
 SG_ EPBL_frontSeatCushionFanEn : 31|1@1+ (1,0) [0|1] "" Vector__XXX
 SG_ EPBL_frontSeatBackrestFanEn : 32|1@1+ (1,0) [0|1] "" Vector__XXX
 SG_ EPBL_frontSeatBackrestFanDuty : 33|7@1+ (1,0) [0|100] "%" Vector__XXX

BO_TX_BU_ 530 : BMS;
BO_TX_BU_ 786 : BMS;
BO_TX_BU_ 754 : BMS;
BO_TX_BU_ 810 : BMS;
BO_TX_BU_ 796 : CC;
BO_TX_BU_ 797 : CC;
BO_TX_BU_ 812 : CC;
BO_TX_BU_ 870 : CMPD;
BO_TX_BU_ 679 : CMPD;
BO_TX_BU_ 867 : CMP;
BO_TX_BU_ 317 : CP;
BO_TX_BU_ 669 : CP;
BO_TX_BU_ 541 : CP;
BO_TX_BU_ 733 : CP;
BO_TX_BU_ 1342 : CP;
BO_TX_BU_ 1885 : CP;
BO_TX_BU_ 989 : CP;
BO_TX_BU_ 605 : CP;
BO_TX_BU_ 893 : CP;
BO_TX_BU_ 1001 : DAS;
BO_TX_BU_ 634 : DIF;
BO_TX_BU_ 741 : DIF;
BO_TX_BU_ 886 : DIF;
BO_TX_BU_ 1367 : DIF;
BO_TX_BU_ 2005 : DIR;
BO_TX_BU_ 633 : DIR;
BO_TX_BU_ 821 : DIR;
BO_TX_BU_ 917 : DIR;
BO_TX_BU_ 614 : DIR;
BO_TX_BU_ 789 : DIR;
BO_TX_BU_ 1495 : DIR;
BO_TX_BU_ 694 : DI;
BO_TX_BU_ 2007 : DI;
BO_TX_BU_ 1022 : DI;
BO_TX_BU_ 1623 : DI;
BO_TX_BU_ 950 : DI;
BO_TX_BU_ 296 : DI;
BO_TX_BU_ 616 : DI;
BO_TX_BU_ 280 : DI;
BO_TX_BU_ 1992 : EPBL;
BO_TX_BU_ 648 : EPBL;
BO_TX_BU_ 743 : EPBL;
CM_ BO_ 530 "High-voltage battery management system message: status";
CM_ SG_ 530 BMS_hvacPowerRequest "High-voltage battery management system: hvac power request";
CM_ SG_ 530 BMS_notEnoughPowerForDrive "Flag indicating the min pack power is lower than specified threshold to support drive";
CM_ SG_ 530 BMS_notEnoughPowerForSupport "Flag indicating if the system can support a new request for 12V battery support";
CM_ SG_ 530 BMS_preconditionAllowed "High-voltage battery management system: precondition allowed";
CM_ SG_ 530 BMS_updateAllowed "High-voltage battery management system: update allowed";
CM_ SG_ 530 BMS_cpMiaOnHvs "Flag indicating that BMS is no longer receiving comms from CP on HVS bus";
CM_ SG_ 530 BMS_pcsPwmEnabled "Reports the state of the PCS_PWM_ENABLE input on the HVBMS, which is derived from the P1-12-DCDC-ENABLE input, which comes from VCFRONT";
CM_ SG_ 530 BMS_contactorState "BMS Contactor Status; raw 0 = signal not available (SNA)";
CM_ SG_ 530 BMS_userChargeStatus "BMS charge status for UI display. Renamed from BMS_uiChargeStatus";
CM_ SG_ 530 BMS_batteryInputPower "High-voltage battery management system: battery input power; raw 65535 = signal not available (SNA)";
CM_ SG_ 530 BMS_chargeRequest "Indicates charge is available and charge is desired";
CM_ SG_ 530 BMS_state "BMS operating state.; raw 9 = signal not available (SNA)";
CM_ SG_ 530 BMS_diLimpRequest "BMS request to DI to enter limp mode";
CM_ SG_ 530 BMS_okToShipByAir "High-voltage battery management system: ok to ship by air";
CM_ SG_ 530 BMS_okToShipByLand "High-voltage battery management system: ok to ship by land";
CM_ SG_ 530 BMS_chgPowerAvailable "BMS available charge power; raw 4095 = signal not available (SNA)";
CM_ SG_ 530 BMS_acManagerState "High-voltage battery management system: ac manager state";
CM_ SG_ 530 BMS_conditioningRequest "BMS request to enable conditioning so it can attempt FEIM recovery";
CM_ SG_ 530 BMS_smStateRequest "BMS high level state request; raw 9 = signal not available (SNA)";
CM_ SG_ 530 BMS_hvState "BMS high voltage state";
CM_ BO_ 786 "High-voltage battery management system message: thermal status";
CM_ SG_ 786 BMS_thermalStatusMultiplexer "High-voltage battery management system: thermal status multiplexer";
CM_ SG_ 786 BMS_inletActiveCoolTargetT "Calculated active cooling temperature target at the inlet";
CM_ SG_ 786 BMS_inletPassiveTargetT "Calculated passive temperature target at the inlet";
CM_ SG_ 786 BMS_inletActiveHeatTargetT "Calculated active heating temperature target at the inlet";
CM_ SG_ 786 BMS_requestDischarge "Flag identifying when the Battery Management System (BMS) is requesting the battery pack to be discharged";
CM_ SG_ 786 BMS_activeHeatingWorthwhile "Determination by the Battery Management System (BMS) if active heating is worthwhile";
CM_ SG_ 786 BMS_pcsNoFlowRequest "High-voltage battery management system: pcs no flow request";
CM_ SG_ 786 BMS_minPackTemperature "Minimum pack temperature for consumption by external entities";
CM_ SG_ 786 BMS_noFlowRequest "High-voltage battery management system: no flow request";
CM_ SG_ 786 BMS_maxPackTemperature "Maximum pack temperature for consumption by external entities";
CM_ SG_ 786 BMS_flowRequest "Requested coolant flow rate in liters per minute (LPM) from the Battery Management System (BMS) to the thermal module";
CM_ SG_ 786 BMS_coldStagnationLimit "Minimum temperature at which the pack is allowed to be used as a heat-energy source";
CM_ SG_ 786 BMS_hotStagnationLimit "Maximum temperature at which we allow the pack to be used for heat-energy storage";
CM_ SG_ 786 BMS_hotCellTempLimit "Maximum temperature at which the pack will allow limp mode levels of current";
CM_ SG_ 786 BMS_i2tDeratingEnabled "High-voltage battery management system: i2t derating enabled";
CM_ SG_ 786 BMS_activeCoolCellReferenceT "Desired cell temperature reference which composes the temperature trajectory portion of the active cooling target temperature controls";
CM_ SG_ 786 BMS_activeHeatCellTargetT "Desired cell temperature which feeds as an input to the active heating target temperature, before any additional controls calculations";
CM_ SG_ 786 BMS_powerDissipation "High-voltage battery management system: power dissipation";
CM_ BO_ 754 "High-voltage battery management system message: veh nm";
CM_ SG_ 754 BMS_nmGoingToSleep "High-voltage battery management system: nm going to sleep";
CM_ SG_ 754 BMS_nmWakeUpBus "High-voltage battery management system: nm wake up bus";
CM_ SG_ 754 BMS_hvsBusAsleep "HVS bus reported as off";
CM_ SG_ 754 BMS_nmKeepAwakeReason "BMS' determined reason to keep CAN awake; raw 0 = signal not available (SNA)";
CM_ SG_ 754 BMS_nmWakeUpReason "BMS' determined reason to wake up CAN";
CM_ BO_ 810 "High-voltage battery management system message: vehicle notifications";
CM_ SG_ 810 BMS_thermalEventSuspected "Indicates the Battery Management System (BMS) has detected conditions that reflect a possible battery thermal event";
CM_ SG_ 810 BMS_vehicleNotificationsCounter "High-voltage battery management system: vehicle notifications counter";
CM_ SG_ 810 BMS_isolationResistance "Resistance between HV bus and chassis.; raw 1023 = signal not available (SNA)";
CM_ SG_ 810 BMS_chgTimeToFull "Estimated time remaining until charge termination percent will be reached; raw 4095 = signal not available (SNA)";
CM_ SG_ 810 BMS_vehicleNotificationsChecksum "High-voltage battery management system: vehicle notifications checksum";
CM_ BO_ 796 "Charge cable controller message: chg status";
CM_ SG_ 796 CC_currentLimit "Maximum allowable AC current the wall connector is willing to provide; raw 255 = signal not available (SNA)";
CM_ SG_ 796 CC_pilotState "State of pilot signal reported by the wall connector; raw 3 = signal not available (SNA)";
CM_ SG_ 796 CC_numPhases "Number of AC phases expected by wall connector; raw 0 = signal not available (SNA)";
CM_ SG_ 796 CC_line1Voltage "RMS voltage on L1 terminal of wall connector; raw 511 = signal not available (SNA)";
CM_ SG_ 796 CC_gridGrounding "Grouding scheme expected by the wall connector; raw 2 = signal not available (SNA)";
CM_ SG_ 796 CC_deltaTransformer "Grid configuration expected by the wall connector";
CM_ SG_ 796 CC_numVehCharging "Number of vehicles charging in wall connector load sharing group";
CM_ SG_ 796 CC_line2Voltage "RMS voltage on L2 terminal of wall connector; raw 511 = signal not available (SNA)";
CM_ SG_ 796 CC_line3Voltage "RMS voltage on L3 terminal of wall connector; raw 511 = signal not available (SNA)";
CM_ SG_ 796 CC_groundResistance "Charge cable controller: ground resistance; raw 4095 = signal not available (SNA)";
CM_ BO_ 797 "Charge cable controller message: chg status2";
CM_ SG_ 797 CC_chgStatus2Index "Charge cable controller: chg status2 index";
CM_ SG_ 797 CC_buttonState "Charge cable controller: button state";
CM_ SG_ 797 EVSE_v2xSupport "Charge cable controller: v2x support";
CM_ SG_ 797 EVSE_v2xHandshakeStart "Charge cable controller: v2x handshake start";
CM_ SG_ 797 EVSE_v2xSessionType "Charge cable controller: v2x session type; raw 0 = signal not available (SNA)";
CM_ BO_ 812 "Charge cable controller message: log data";
CM_ SG_ 812 CC_logIndex "Charge cable controller: log index";
CM_ SG_ 812 CC_activeConnectorID "Site identifier of active charge connector";
CM_ SG_ 812 CC_temperature1 "Charge cable vehicle connector temperature";
CM_ SG_ 812 CC_temperature2 "Charge cable vehicle connector temperature";
CM_ SG_ 812 CC_temperature3 "Charge cable vehicle connector temperature";
CM_ SG_ 812 CC_contactor1Closed "State of contactor 1 in wall connector";
CM_ SG_ 812 CC_contactor2Closed "State of contactor 1 in wall connector";
CM_ SG_ 812 CC_temperature4 "Charge cable vehicle connector temperature";
CM_ SG_ 812 CC_conn1Current "AC current on connector 1 in wall charger load sharing group; raw 255 = signal not available (SNA)";
CM_ SG_ 812 CC_conn2Current "AC current on connector 2 in wall charger load sharing group; raw 255 = signal not available (SNA)";
CM_ SG_ 812 CC_conn3Current "AC current on connector 3 in wall charger load sharing group; raw 255 = signal not available (SNA)";
CM_ SG_ 812 CC_conn4Current "AC current on connector 4 in wall charger load sharing group; raw 255 = signal not available (SNA)";
CM_ SG_ 812 CC_lifetimei2t "Charge cable controller: lifetimei2t";
CM_ SG_ 812 CC_lifetimeCtrCycles "Charge cable controller: lifetime ctr cycles";
CM_ SG_ 812 CC_lifetimeCtrCyclesLoaded "Charge cable controller: lifetime ctr cycles loaded";
CM_ SG_ 812 CC_lifetimeAlertCount "Charge cable controller: lifetime alert count";
CM_ SG_ 812 CC_lifetimeThermalFoldbacks "Charge cable controller: lifetime thermal foldbacks";
CM_ SG_ 812 CC_lifetimeAvgStartupTemp "Charge cable controller: lifetime avg startup temp";
CM_ BO_ 870 "CMPD ECU message: info";
CM_ SG_ 870 CMPD_infoIndex "CMPD ECU: info index";
CM_ SG_ 870 CMPD_infoBuildType "CMPD ECU: info build type";
CM_ SG_ 870 CMPD_infoBuildConfigId "CMPD ECU: info build config id";
CM_ SG_ 870 CMPD_infoHardwareId "CMPD ECU: info hardware id";
CM_ SG_ 870 CMPD_infoComponentId "CMPD ECU: info component id";
CM_ SG_ 870 CMPD_infoPcbaId "CMPD ECU: info pcba id";
CM_ SG_ 870 CMPD_infoAssemblyId "CMPD ECU: info assembly id; raw 255 = signal not available (SNA)";
CM_ SG_ 870 CMPD_infoUsageId "CMPD ECU: info usage id";
CM_ SG_ 870 CMPD_infoSubUsageId "CMPD ECU: info sub usage id";
CM_ BO_ 679 "CMPD ECU message: state";
CM_ SG_ 679 CMPD_speedRPM "Reports compressor speed.";
CM_ SG_ 679 CMPD_speedDuty "Reports compressor speed duty cycle percentage.";
CM_ SG_ 679 CMPD_inputHVPower "Measures compressor input high voltage (HV) power consumption.";
CM_ SG_ 679 CMPD_inputHVCurrent "Measures compressor input high voltage (HV) current draw.";
CM_ SG_ 679 CMPD_inputHVVoltage "Measures compressor input high voltage (HV) level.";
CM_ SG_ 679 CMPD_2ShuntModeActive "Indicates the compressor motor control is running using only two current shunt resistors instead of three.";
CM_ SG_ 679 CMPD_powerLimitActive "Indicates the compressor power limit is active.";
CM_ SG_ 679 CMPD_state "Reports compressor operational state.; raw 15 = signal not available (SNA)";
CM_ SG_ 679 CMPD_wasteHeatState "Reports compressor waste heat recovery state.";
CM_ SG_ 679 CMPD_powerLimitTooLowToStart "Indicates the compressor power limit is too low to start the compressor.";
CM_ SG_ 679 CMPD_ready "Indicates the compressor is ready to start.";
CM_ BO_ 867 "A/C compressor message: info";
CM_ SG_ 867 CMP_infoIndex "A/C compressor: info index";
CM_ SG_ 867 CMP_infoBuildType "A/C compressor: info build type";
CM_ SG_ 867 CMP_infoBuildConfigId "A/C compressor: info build config id";
CM_ SG_ 867 CMP_infoHardwareId "A/C compressor: info hardware id";
CM_ SG_ 867 CMP_infoComponentId "A/C compressor: info component id";
CM_ SG_ 867 CMP_infoPcbaId "A/C compressor: info pcba id";
CM_ SG_ 867 CMP_infoAssemblyId "A/C compressor: info assembly id; raw 255 = signal not available (SNA)";
CM_ SG_ 867 CMP_infoUsageId "A/C compressor: info usage id";
CM_ SG_ 867 CMP_infoSubUsageId "A/C compressor: info sub usage id";
CM_ SG_ 867 CMP_infoPlatformType "A/C compressor: info platform type";
CM_ SG_ 867 CMP_infoAppCrc "A/C compressor: info app crc";
CM_ SG_ 867 CMP_infoBootUdsProtoVersion "A/C compressor: info boot uds proto version";
CM_ SG_ 867 CMP_infoBootCrc "A/C compressor: info boot crc";
CM_ BO_ 317 "Charge port controller message: charge status";
CM_ SG_ 317 CP_powerTransferStatus "Indicates the state of the charge port power transfer interface.";
CM_ SG_ 317 CP_powerTransferShutdownRequest "Reports the request from the charge port to end a charge session.";
CM_ SG_ 317 CP_evseAcControlMode "Charge port controller: evse ac control mode";
CM_ SG_ 317 CP_v2xCapable "Indicates whether the charge port ECU supports Powershare (V2X) features.";
CM_ SG_ 317 CP_evseAcCurrentLimit "Measures the maximum current the AC EVSE can allow per conductor.";
CM_ SG_ 317 CP_internalMaxDcCurrentLimit "Measures the maximum current the charge port can allow while DC charging.";
CM_ SG_ 317 CP_vehicleIsoCheckRequired "Indicates whether the vehicle is expected to perform isolation monitoring while charging is active.";
CM_ SG_ 317 CP_vehiclePrechargeRequired "Indicates whether the vehicle is expected to perform precharge for the DC charge session.";
CM_ SG_ 317 CP_internalMaxAcCurrentLimit "Measures the maximum current the charge port can allow while AC charging.";
CM_ SG_ 317 CP_evseChargeType "Reports the type of EVSE connected.";
CM_ SG_ 317 CP_chgLimitMode "Reports the reason the charge port is attempting to limit the charge current.";
CM_ SG_ 317 CP_dcHvInletExposed "Indicates whether the direct current (DC) charge port inlet pins are exposed to human touch.";
CM_ SG_ 317 CP_acHvInletExposed "Indicates whether the alternating current (AC) charge port inlet pins are exposed to human touch.";
CM_ BO_ 669 "Charge port controller message: dc charge status";
CM_ SG_ 669 CP_evseOutputDcCurrent "The DC EVSE's measured output current";
CM_ SG_ 669 CP_evseOutputDcVoltage "The DC EVSE's measured output voltage";
CM_ SG_ 669 CP_evseOutputDcCurrentStale "Indicates whether the data in CP_evseOutputDcCurrent has not been updated with new info from the DC EVSE recently";
CM_ SG_ 669 CP_evRelocationRecommended "Indicates whether the supercharger EVSE recommends relocating the vehicle";
CM_ SG_ 669 CP_evseDeratingReason "Reports the derating reason from Supercharger EVSE";
CM_ BO_ 541 "Charge port controller message: evse status";
CM_ SG_ 541 CP_evseAccept "State of pilot EVSE accept state";
CM_ SG_ 541 CP_evseRequest "Request to close AC EVSE relays, used when digital communications have been established";
CM_ SG_ 541 CP_proximity "Sensed state of proximity for all inlets; raw 0 = signal not available (SNA)";
CM_ SG_ 541 CP_pilot "State of EVSE pilot signal sensed by the charge port; raw 7 = signal not available (SNA)";
CM_ SG_ 541 CP_digitalCommsEstablished "Indicates whether digital communications have been established with an EVSE";
CM_ SG_ 541 CP_pilotCurrent "Line current limit detected from pilot signal";
CM_ SG_ 541 CP_cableType "Type of charge cable detected; raw 5 = signal not available (SNA)";
CM_ SG_ 541 CP_iecPilotState "State of the control pilot as defined in IEC-61851-1; raw 9 = signal not available (SNA)";
CM_ SG_ 541 CP_plcSupported "Indicates whether PLC hardware is populated for CCS charging support";
CM_ SG_ 541 CP_cableCurrentLimit "Charge port controller: cable current limit";
CM_ SG_ 541 CP_teslaSwcanState "Charge port controller: tesla swcan state";
CM_ SG_ 541 CP_evseChargeType_UI "Reports the type of Electric Vehicle Supply Equipment (EVSE) connected.";
CM_ SG_ 541 CP_gbState "State of GB DC charging";
CM_ SG_ 541 CP_gbdcStopChargeReason "Reason for stopping GB DC charging";
CM_ SG_ 541 CP_gbdcFailureReason "Reason for failure of GB DC charging";
CM_ SG_ 541 CP_gbdcChargeAttempts "Number of GB DC charging retries used";
CM_ SG_ 541 CP_acChargeState "Charge port controller: ac charge state";
CM_ SG_ 541 CP_acChargeType "Charge port controller: ac charge type";
CM_ SG_ 541 CP_teslaDcState "Reports the state of the Tesla direct current (DC) state machine.";
CM_ BO_ 733 "Charge port controller message: grid form control";
CM_ SG_ 733 CP_gridFormFrequencyRequest "Charge port controller: grid form frequency request; raw 4095 = signal not available (SNA)";
CM_ SG_ 733 CP_gridFormL1NVoltageRequest "Charge port controller: grid form L1 n voltage request; raw 255 = signal not available (SNA)";
CM_ SG_ 733 CP_gridFormGroundType "Charge port controller: grid form ground type; raw 0 = signal not available (SNA)";
CM_ SG_ 733 CP_gridFormGridType "Charge port controller: grid form grid type; raw 0 = signal not available (SNA)";
CM_ SG_ 733 CP_powershareType "Charge port controller: powershare type";
CM_ SG_ 733 CP_userPowershareStatus "Charge port controller: user powershare status";
CM_ SG_ 733 CP_powershareStoppedReason "Charge port controller: powershare stopped reason";
CM_ BO_ 1342 "Charge port controller message: info";
CM_ SG_ 1342 CP_infoIndex "Charge port controller: info index";
CM_ SG_ 1342 CP_buildType "Charge port controller: build type";
CM_ SG_ 1342 CP_buildConfigId "Charge port controller: build config id";
CM_ SG_ 1342 CP_hardwareId "Charge port controller: hardware id";
CM_ SG_ 1342 CP_componentId "Charge port controller: component id";
CM_ SG_ 1342 CP_pcbaId "Charge port controller: pcba id";
CM_ SG_ 1342 CP_assemblyId "Charge port controller: assembly id";
CM_ SG_ 1342 CP_usageId "Charge port controller: usage id";
CM_ SG_ 1342 CP_subUsageId "Charge port controller: sub usage id";
CM_ SG_ 1342 CP_platformType "Charge port controller: platform type";
CM_ SG_ 1342 CP_appCrc "Charge port controller: app crc";
CM_ SG_ 1342 CP_appGitHash "Charge port controller: app git hash";
CM_ SG_ 1342 CP_bootGitHash "Charge port controller: boot git hash";
CM_ SG_ 1342 CP_bootUdsProtoVersion "Charge port controller: boot uds proto version";
CM_ SG_ 1342 CP_bootCrc "Charge port controller: boot crc";
CM_ BO_ 1885 "Charge port controller message: logging fast";
CM_ SG_ 1885 CP_loggingFastSelect "Charge port controller: logging fast select";
CM_ SG_ 1885 CP_inductiveSensor_raw "Charge port controller: inductive sensor raw";
CM_ SG_ 1885 CP_doorOpenActuationTime "Charge port controller: door open actuation time";
CM_ SG_ 1885 CP_doorCloseActuationTime "Charge port controller: door close actuation time";
CM_ SG_ 1885 CP_chargeCableSecured "Indicates whether a charge cable is secured in any inlet";
CM_ SG_ 1885 CP_chargeCablePresent "Indicates whether a charge cable is present in any inlet";
CM_ SG_ 1885 CP_latchCheckAvailable "Charge port controller: latch check available";
CM_ SG_ 1885 CP_UHF_controlState "Control state of UHF receiver";
CM_ SG_ 1885 CP_proximityV "Charge port controller: proximity v";
CM_ SG_ 1885 CP_proximityV_GBCC1 "Sensed voltage of GB DC inlet CC1 connection";
CM_ SG_ 1885 CP_proximityV_GBCC2 "Sensed voltage of GB DC inlet CC2 connection";
CM_ SG_ 1885 CP_doorPot "Position of the charge port door potentiometer";
CM_ SG_ 1885 CP_doorPresenceSensorV "Reports voltage value read by the charge port door's presence sensor.";
CM_ SG_ 1885 CP_doorOpenRequest "Door open request trigger";
CM_ SG_ 1885 CP_doorOpenEndOfDriveReason "Reason why the door stopped moving in the open direction";
CM_ SG_ 1885 CP_coverClosed "Charge port controller: cover closed";
CM_ SG_ 1885 CP_doorCloseEndOfDriveReason "Reason why the door stopped moving in the closing direction";
CM_ SG_ 1885 CP_doorCloseRequest "Door close request trigger";
CM_ SG_ 1885 CP_latchDisengagingTime "Charge port controller: latch disengaging time";
CM_ SG_ 1885 CP_latchEngagingTime "Charge port controller: latch engaging time";
CM_ SG_ 1885 CP_latchDisengagingStopReason "Reason why the latch stopped moving in the engaged direction";
CM_ SG_ 1885 CP_latchEngagingStopReason "Reason why the latch stopped moving in the engaged direction";
CM_ SG_ 1885 CP_pilotUnlatchRequestActive "Reports whether the Charge Port (CP) pilot unlatch request is active.";
CM_ SG_ 1885 CP_doorIdDetectionState "Charge port controller: door id detection state; raw 0 = signal not available (SNA)";
CM_ SG_ 1885 CP_doorIdDetectedBin "Charge port controller: door id detected bin";
CM_ SG_ 1885 CP_semiV2LatchNonLinear "Reports whether the Charge Port (CP) SemiV2 latch potentiometer reading is non-linear.";
CM_ BO_ 989 "Charge port controller message: logging slow";
CM_ SG_ 989 CP_loggingSlowSelect "Charge port controller: logging slow select";
CM_ SG_ 989 CP_UHF_chipState "Charge port controller: UHF chip state";
CM_ SG_ 989 CP_UHF_rssi "Signal strength of received UHF signal";
CM_ SG_ 989 CP_UHF_rxOverflow "Charge port controller: UHF rx overflow";
CM_ SG_ 989 CP_UHF_rxNumBytes "Charge port controller: UHF rx num bytes";
CM_ SG_ 989 CP_UHF_selfTestRssi "Signal strength of received self-test UHF signal";
CM_ SG_ 989 CP_latchI "Charge port controller: latch i";
CM_ SG_ 989 CP_inlet1HarnessIdState "State of the CP's inlet 1 harness pedigree; raw 0 = signal not available (SNA)";
CM_ SG_ 989 CP_inlet1HarnessIdValue "Pedigree of the CP's inlet 1 harness";
CM_ SG_ 989 CP_inlet2HarnessIdState "State of the CP's inlet 2 harness pedigree; raw 0 = signal not available (SNA)";
CM_ SG_ 989 CP_inlet2HarnessIdValue "Pedigree of the CP's inlet 2 harness";
CM_ SG_ 989 CP_inletHeaterState "Reports the present state of the inlet heater.";
CM_ SG_ 989 CP_inletHeaterDuty "Inlet heater PWM duty cycle";
CM_ SG_ 989 CP_5vSwV "Charge port controller: 5v sw v";
CM_ SG_ 989 CP_boardTemperature "Charge port controller: board temperature";
CM_ SG_ 989 CP_refVoltage "Charge port controller: ref voltage";
CM_ SG_ 989 CP_doorId_intervalMin10s "Charge port controller: door id interval min10s";
CM_ SG_ 989 CP_doorId_intervalMax10s "Charge port controller: door id interval max10s";
CM_ SG_ 989 CP_wakeOnPushCounter "Charge port controller: wake on push counter";
CM_ SG_ 989 CP_doorPushLockoutActive "Reports whether the Charge Port (CP) wake on press has been disabled due to rate-limiting.";
CM_ SG_ 989 CP_nvm_dataValid "Charge port controller: nvm data valid";
CM_ SG_ 989 CP_nvm_doorOpenCycles "Charge port controller: nvm door open cycles";
CM_ SG_ 989 CP_nvm_doorCloseCycles "Charge port controller: nvm door close cycles";
CM_ SG_ 989 CP_nvm_doorOpen "Charge port controller: nvm door open";
CM_ SG_ 989 CP_nvm_doorPresent "Charge port controller: nvm door present";
CM_ SG_ 989 CP_nvm_doorPresentValid "Charge port controller: nvm door present valid";
CM_ SG_ 989 CP_nvm_badPilotDiodeDetected "Charge port controller: nvm bad pilot diode detected";
CM_ SG_ 989 CP_nvm_pilotDiodeFaultCount "Charge port controller: nvm pilot diode fault count";
CM_ SG_ 989 CP_doorOpenLimiterMaxCount "Charge port controller: door open limiter max count";
CM_ SG_ 989 CP_doorOpenLimiterMaxRequestType "Charge port controller: door open limiter max request type";
CM_ SG_ 989 CP_doorCloseLimiterMaxCount "Charge port controller: door close limiter max count";
CM_ SG_ 989 CP_doorCloseLimiterMaxRequestTyp "Charge port controller: door close limiter max request type";
CM_ SG_ 989 CP_proximityWakeCounter "Charge port controller: proximity wake counter";
CM_ BO_ 605 "Charge port controller message: status";
CM_ SG_ 605 CP_type "Charge port controller: type";
CM_ SG_ 605 CP_insertEnableLine "Sensed state of the charge port latch drive enable hardline";
CM_ SG_ 605 CP_latchState "Sensed state of the charge port latch; raw 0 = signal not available (SNA)";
CM_ SG_ 605 CP_permanentPowerRequest "Charge port controller: permanent power request";
CM_ SG_ 605 CP_chargeDoorOpen "Indicates whether the charge port door is open based on all door sensors";
CM_ SG_ 605 CP_doorControlState "State of the charge port door controller";
CM_ SG_ 605 CP_doorButtonPressed "Indicates whether the charge door button has been pressed";
CM_ SG_ 605 CP_swcanRelayClosed "Indicates whether the single wire CAN relay is closed";
CM_ SG_ 605 CP_inhibitOta "Reports the charge port's request to prevent scheduled Over-The-Air (OTA) updates during critical charging operations.";
CM_ SG_ 605 CP_chargeCableState "Charge cable connection state; raw 0 = signal not available (SNA)";
CM_ SG_ 605 CP_latchControlState "Control state of the charge port latch";
CM_ SG_ 605 CP_ledColor "Color of the charge port LED";
CM_ SG_ 605 CP_UHF_handleFound "Indicates whether a charge handle has been found with UHF";
CM_ SG_ 605 CP_faultLineSensed "A signal indicating the set / cleared state of the CP-HVP bi-directional fault line, as sensed by the CP";
CM_ SG_ 605 CP_doorPresenceState "State of door as detected by the presence sensor";
CM_ SG_ 605 CP_inductiveSensorState "State of inductive door sensor";
CM_ SG_ 605 CP_chargeDoorOpenUI "Indicates whether the charge port door is open based only on the door poteniometer";
CM_ SG_ 605 CP_vehicleUnlockRequest "Request to unlock the vehicle";
CM_ SG_ 605 CP_coldWeatherMode "Indicates whether the charge port is in cold weather mode";
CM_ SG_ 605 CP_latchEngaged "Charge port controller: latch engaged";
CM_ SG_ 605 CP_inletHeaterUiState "Reports to the User Interface (UI) the state of the inlet heater.";
CM_ SG_ 605 CP_userEvseModelType "Reports the type of Electric Vehicle Supply Equipment (EVSE) model to display to the user.";
CM_ SG_ 605 CP_evseGridFormHardwareType "Reports Electric Vehicle Supply Equipment (EVSE) grid form hardware type for grid forming.; raw 15 = signal not available (SNA)";
CM_ SG_ 605 CP_faultLineV "Charge port controller: fault line v";
CM_ SG_ 605 CP_faultLineSetByCP "Reports that the Charge Port (CP) triggered the hardware fault line.";
CM_ SG_ 605 CP_AuthManagerState "Charge port controller: auth manager state";
CM_ BO_ 893 "Charge port controller message: thermal status";
CM_ SG_ 893 CP_thermalStatusSelect "Charge port controller: thermal status select";
CM_ SG_ 893 CP_pinTemperature1 "Sensed temperature of the charge port inlet pins";
CM_ SG_ 893 CP_pinTemperature2 "Sensed temperature of the charge port inlet pins";
CM_ SG_ 893 CP_pinTemperature3 "Sensed temperature of the charge port inlet pins";
CM_ SG_ 893 CP_pinTemperature4 "Sensed temperature of the charge port inlet pins";
CM_ SG_ 893 CP_pinTemp4Velocity "Instantaneous temperature velocity (over 1 minute) of Charge Port's temperature 4; raw 511 = signal not available (SNA)";
CM_ BO_ 1001 "Driver assistance computer message: body controls";
CM_ SG_ 1001 DAS_headlightRequest "The DAS request to the body controls ecu to turn on headlights.";
CM_ SG_ 1001 DAS_hazardLightRequest "The command from DAS to body controls to turn on the hazard lights.; raw 3 = signal not available (SNA)";
CM_ SG_ 1001 DAS_wiperSpeed "The auto wiper algorithm speed request to the body controller.";
CM_ SG_ 1001 DAS_turnIndicatorRequest "Reports Driver Assistance System (DAS) request to body controls to turn on/off the left or right turn indicator.";
CM_ SG_ 1001 DAS_highLowBeamDecision "The output of the automatic high beam algorithm, to turn the highbeams on or off.; raw 3 = signal not available (SNA)";
CM_ SG_ 1001 DAS_heaterRequest "The DAS request to the body controller to turn on the front glass heater in front of the triple camera.; raw 0 = signal not available (SNA)";
CM_ SG_ 1001 DAS_highLowBeamOffReason "The reason why automatic high beams are surpressed.; raw 5 = signal not available (SNA)";
CM_ SG_ 1001 DAS_forwardCamHeaterDutyCycle "Supplies the requested duty cycle of the front windshield camera heater";
CM_ SG_ 1001 DAS_dynamicBrakeLightRequest "Indicates if the dynamic brake light alogirthm is requesting pulsing brake lights.";
CM_ SG_ 1001 DAS_radarHeaterRequest "Reports the request from Driver Assistance System (DAS) to body controls to turn on heater to clear out fascia in front of the radar.";
CM_ SG_ 1001 DAS_ahlbOverride "Indicates if body controller should override UI switch and stalk state to allow auto high beam functionality";
CM_ SG_ 1001 DAS_mirrorFoldRequest "DAS request to fold or present mirrors.; raw 3 = signal not available (SNA)";
CM_ SG_ 1001 DAS_wiperWashRequest "Autowiper requests that the windshield be washed";
CM_ SG_ 1001 DAS_ulcConfirmationRequestActive "Driver assistance computer: ulc confirmation request active";
CM_ SG_ 1001 DAS_overrideWiperSetting "Autopilot wants to override the user's wiper setting to enable auto-wiper";
CM_ SG_ 1001 DAS_autoWiperState "DAS auto wiper internal state; raw 5 = signal not available (SNA)";
CM_ SG_ 1001 DAS_turnIndicatorRequestReason "Reports the reason that Driver Assistance System (DAS) is requesting a change to the turn indicator state from body controls.";
CM_ SG_ 1001 DAS_forwardRadarPowerRequest "Driver assistance computer: forward radar power request";
CM_ SG_ 1001 DAS_driverDomeLightRequest "DAS requests that driver side dome light be illuminated";
CM_ SG_ 1001 DAS_drivePowerStateRequest "Reports DAS request for vehicle power state Drive.";
CM_ SG_ 1001 DAS_enableIcrDataCollection "Driver assistance computer: enable icr data collection";
CM_ SG_ 1001 DAS_rPillarCamHeaterDutyCycle "Supplies the requested duty cycle of the right pillar camera heater";
CM_ SG_ 1001 DAS_adaptiveHighBeamIsFaulted "Indicates malfunctioning or unavailable input to the Adaptive High Beam system.";
CM_ SG_ 1001 DAS_restrictDoorReleaseLeft "Reports requests to inhibit left doors from being released.";
CM_ SG_ 1001 DAS_restrictDoorReleaseRight "Reports requests to inhibit right doors from being released.";
CM_ SG_ 1001 DAS_bodyControlsCounter "Driver assistance computer: body controls counter";
CM_ SG_ 1001 DAS_bodyControlsChecksum "Driver assistance computer: body controls checksum";
CM_ BO_ 634 "Front drive inverter message: hv status";
CM_ SG_ 634 DIF_hvStatusChecksum "Front drive inverter: hv status checksum";
CM_ SG_ 634 DIF_hvStatusCounter "Front drive inverter: hv status counter";
CM_ SG_ 634 DIF_hvilCurrent "HVIL Current";
CM_ SG_ 634 DIF_hvilCmVoltage "HVIL Common Mode Voltage";
CM_ SG_ 634 DIF_hvilStatus "Aggregated hardware and measured HVIL unit status; raw 3 = signal not available (SNA)";
CM_ SG_ 634 DIF_hvilSupplyState "Front drive inverter: hvil supply state";
CM_ SG_ 634 DIF_activeDischargeCtrl "Front drive inverter: active discharge ctrl";
CM_ SG_ 634 DIF_activeDischargeStatus "Active discharge status from HVIL_FAULT signal.";
CM_ SG_ 634 DIF_vBat "Reports the battery voltage measured by the Drive Inverter's local Analog to Digital Converter (ADC).";
CM_ SG_ 634 DIF_vBatQF "Front drive inverter: v bat QF";
CM_ SG_ 634 DIF_powerStageSafeState "Front drive inverter: power stage safe state";
CM_ SG_ 634 DIF_fluxState "Front drive inverter: flux state";
CM_ SG_ 634 DIF_vBusDiag "Front drive inverter: v bus diag";
CM_ SG_ 634 DIF_gateDriveState "Front drive inverter: gate drive state";
CM_ SG_ 634 DIF_gateDriveSupplyState "Front drive inverter: gate drive supply state";
CM_ BO_ 741 "Front drive inverter message: power";
CM_ SG_ 741 DIF_elecPower "Front drive inverter: elec power; raw 1024 = signal not available (SNA)";
CM_ SG_ 741 DIF_heatPowerOptimal "Front drive inverter: heat power optimal";
CM_ SG_ 741 DIF_heatPowerMax "Drive Inverter maximum heat power capability";
CM_ SG_ 741 DIF_heatPowerActual "Drive Inverter heat power";
CM_ SG_ 741 DIF_excessHeatCommand "Drive Inverter excess heat command";
CM_ SG_ 741 DIF_drivePowerMax "Front drive inverter: drive power max; raw 511 = signal not available (SNA)";
CM_ BO_ 886 "Front drive inverter message: temperature";
CM_ SG_ 886 DIF_tempIndex "Front drive inverter: temp index";
CM_ SG_ 886 DIF_inverterTQF "Detects the Drive Inverter (DI) outlet temperature qualifier.";
CM_ SG_ 886 DIF_pcbT "Front drive inverter: pcb t; raw 0 = signal not available (SNA)";
CM_ SG_ 886 DIF_inverterT "Drive Inverter measured outlet temperature";
CM_ SG_ 886 DIF_statorT "Drive Inverter measured stator temperature.; raw 0 = signal not available (SNA)";
CM_ SG_ 886 DIF_dcCapT "Front drive inverter: dc cap t; raw 0 = signal not available (SNA)";
CM_ SG_ 886 DIF_heatsinkT "Drive Inverter measured heatsink temperature; raw 0 = signal not available (SNA)";
CM_ SG_ 886 DIF_inverterTpct "Front drive inverter: inverter tpct";
CM_ SG_ 886 DIF_statorTpct "Front drive inverter: stator tpct";
CM_ SG_ 886 DIF_fluidInTemp "Inlet fluid temperature; raw 0 = signal not available (SNA)";
CM_ SG_ 886 DIF_normalFetBurnIn "Front drive inverter: normal fet burn in; raw 65535 = signal not available (SNA)";
CM_ SG_ 886 DIF_additionalFetBurnIn "Front drive inverter: additional fet burn in; raw 65535 = signal not available (SNA)";
CM_ SG_ 886 DIF_currentWeibullMiles "Front drive inverter: current weibull miles; raw 32767 = signal not available (SNA)";
CM_ SG_ 886 DIF_endOfServiceWeibullMiles "Front drive inverter: end of service weibull miles; raw 32767 = signal not available (SNA)";
CM_ SG_ 886 DIF_burnInDamageRatio "Front drive inverter: burn in damage ratio; raw 511 = signal not available (SNA)";
CM_ SG_ 886 DIF_inverterSensorEst "Front drive inverter: inverter sensor est";
CM_ SG_ 886 DIF_inverterHS1Est "Front drive inverter: inverter HS1 est";
CM_ SG_ 886 DIF_initialBurnInVehicleOdometer "Front drive inverter: initial burn in vehicle odometer; raw 4294967295 = signal not available (SNA)";
CM_ SG_ 886 DIF_inverterHS2Est "Front drive inverter: inverter HS2 est";
CM_ SG_ 886 DIF_inverterInletEst "Front drive inverter: inverter inlet est";
CM_ SG_ 886 DIF_statorHousingTemp "Front drive inverter: stator housing temp; raw 0 = signal not available (SNA)";
CM_ BO_ 1367 "Front drive inverter message: thermal control";
CM_ SG_ 1367 DIF_passiveInletTempReq "Front drive inverter: passive inlet temp req";
CM_ SG_ 1367 DIF_activeInletTempReq "Front drive inverter: active inlet temp req";
CM_ SG_ 1367 DIF_coolantFlowReq "Coolant flow requested";
CM_ SG_ 1367 DIF_oilFlowReq "Front drive inverter: oil flow req; raw 255 = signal not available (SNA)";
CM_ SG_ 1367 DIF_criticalFlowReq "Front drive inverter: critical flow req";
CM_ SG_ 1367 DIF_burnInStatus "Front drive inverter: burn in status";
CM_ BO_ 2005 "Rear drive inverter message: debug";
CM_ SG_ 2005 DIR_debugSelector "Rear drive inverter: debug selector";
CM_ SG_ 2005 DIR_phaseOutBusbarTemp "Rear drive inverter: phase out busbar temp; raw 0 = signal not available (SNA)";
CM_ SG_ 2005 DIR_phaseOutBusbarWeldTemp "Rear drive inverter: phase out busbar weld temp; raw 0 = signal not available (SNA)";
CM_ SG_ 2005 DIR_phaseOutLugTemp "Rear drive inverter: phase out lug temp; raw 0 = signal not available (SNA)";
CM_ SG_ 2005 DIR_dcLinkCapTemp "Rear drive inverter: dc link cap temp; raw 0 = signal not available (SNA)";
CM_ SG_ 2005 DIR_hvDcCableTemp "Rear drive inverter: hv dc cable temp; raw 0 = signal not available (SNA)";
CM_ SG_ 2005 DIR_negDcBusbarTemp "Rear drive inverter: neg dc busbar temp; raw 0 = signal not available (SNA)";
CM_ SG_ 2005 DIR_posDcBusbarTemp "Rear drive inverter: pos dc busbar temp; raw 0 = signal not available (SNA)";
CM_ SG_ 2005 DIR_statorEndWindingTemp "Rear drive inverter: stator end winding temp; raw 0 = signal not available (SNA)";
CM_ SG_ 2005 DIR_rotorMaxMagnetTemp "Reports the maximum temperature of the rotor magnet.; raw 0 = signal not available (SNA)";
CM_ SG_ 2005 DIR_lightSenseV "Rear drive inverter: light sense v";
CM_ SG_ 2005 DIR_pyroSenseV "Rear drive inverter: pyro sense v";
CM_ SG_ 2005 DIR_statorSlotWindingTemp "Rear drive inverter: stator slot winding temp; raw 0 = signal not available (SNA)";
CM_ SG_ 2005 DIR_intervalMaxHvBusV "Rear drive inverter: interval max hv bus v";
CM_ BO_ 633 "Rear drive inverter message: hv status";
CM_ SG_ 633 DIR_hvStatusChecksum "Rear drive inverter: hv status checksum";
CM_ SG_ 633 DIR_hvStatusCounter "Rear drive inverter: hv status counter";
CM_ SG_ 633 DIR_hvilCurrent "HVIL Current";
CM_ SG_ 633 DIR_hvilCmVoltage "HVIL Common Mode Voltage";
CM_ SG_ 633 DIR_hvilStatus "Aggregated hardware and measured HVIL unit status; raw 3 = signal not available (SNA)";
CM_ SG_ 633 DIR_hvilSupplyState "Rear drive inverter: hvil supply state";
CM_ SG_ 633 DIR_activeDischargeCtrl "Rear drive inverter: active discharge ctrl";
CM_ SG_ 633 DIR_activeDischargeStatus "Active discharge status from HVIL_FAULT signal.";
CM_ SG_ 633 DIR_vBat "Reports the battery voltage measured by the Drive Inverter's local Analog to Digital Converter (ADC).";
CM_ SG_ 633 DIR_vBatQF "Rear drive inverter: v bat QF";
CM_ SG_ 633 DIR_powerStageSafeState "Rear drive inverter: power stage safe state";
CM_ SG_ 633 DIR_fluxState "Rear drive inverter: flux state";
CM_ SG_ 633 DIR_vBusDiag "Rear drive inverter: v bus diag";
CM_ SG_ 633 DIR_gateDriveState "Rear drive inverter: gate drive state";
CM_ SG_ 633 DIR_gateDriveSupplyState "Rear drive inverter: gate drive supply state";
CM_ BO_ 821 "Rear drive inverter message: info";
CM_ SG_ 821 DIR_infoIndex "Rear drive inverter: info index";
CM_ SG_ 821 DIR_buildType "Rear drive inverter: build type";
CM_ SG_ 821 DIR_buildConfigurationId "Rear drive inverter: build configuration id";
CM_ SG_ 821 DIR_hardwareId "Rear drive inverter: hardware id";
CM_ SG_ 821 DIR_componentId "Rear drive inverter: component id";
CM_ SG_ 821 DIR_pcbaId "Rear drive inverter: pcba id";
CM_ SG_ 821 DIR_assemblyId "Rear drive inverter: assembly id";
CM_ SG_ 821 DIR_usageId "Rear drive inverter: usage id";
CM_ SG_ 821 DIR_subUsageId "Rear drive inverter: sub usage id";
CM_ SG_ 821 DIR_motorType "Rear drive inverter: motor type; raw 0 = signal not available (SNA)";
CM_ SG_ 821 DIR_siliconType "Rear drive inverter: silicon type";
CM_ SG_ 821 DIR_mechSafeStateType "Rear drive inverter: mech safe state type; raw 0 = signal not available (SNA)";
CM_ SG_ 821 DIR_applicationCrc "Rear drive inverter: application crc";
CM_ SG_ 821 DIR_oilPumpBuildType "Rear drive inverter: oil pump build type";
CM_ SG_ 821 DIR_oilPumpAppCrc "Rear drive inverter: oil pump app crc";
CM_ SG_ 821 DIR_FPGA_version "Rear drive inverter: FPGA version; raw 255 = signal not available (SNA)";
CM_ SG_ 821 DIR_appGitHash "Rear drive inverter: app git hash";
CM_ SG_ 821 DIR_bootGitHash "Rear drive inverter: boot git hash";
CM_ SG_ 821 DIR_infoBootLdUdsProtocolVersion "Rear drive inverter: info boot ld uds protocol version";
CM_ SG_ 821 DIR_bootloaderCrc "Rear drive inverter: bootloader crc";
CM_ SG_ 821 DIR_oilPumpPcbaId "Rear drive inverter: oil pump pcba id";
CM_ SG_ 821 DIR_oilPumpAssemblyId "Rear drive inverter: oil pump assembly id";
CM_ SG_ 821 DIR_oilPumpUsageId "Rear drive inverter: oil pump usage id";
CM_ SG_ 821 DIR_refRotorFlux "Rear drive inverter: ref rotor flux";
CM_ SG_ 821 DIR_refRotorOffset "Rear drive inverter: ref rotor offset; raw 2048 = signal not available (SNA)";
CM_ SG_ 821 DIR_speedWearTotal "Rear drive inverter: speed wear total; raw 255 = signal not available (SNA)";
CM_ SG_ 821 DIR_torqueWearTotal "Rear drive inverter: torque wear total; raw 255 = signal not available (SNA)";
CM_ BO_ 917 "Rear drive inverter message: oil pump";
CM_ SG_ 917 DIR_oilPumpState "Reports the state of the oil pump.; raw 7 = signal not available (SNA)";
CM_ SG_ 917 DIR_oilPumpFluidTQF "Rear drive inverter: oil pump fluid TQF";
CM_ SG_ 917 DIR_oilPumpLeadAngle "Rear drive inverter: oil pump lead angle";
CM_ SG_ 917 DIR_oilPumpFlowTarget "Detects oil pump flow target.; raw 255 = signal not available (SNA)";
CM_ SG_ 917 DIR_oilPumpFlowActual "Detects oil pump flow.; raw 255 = signal not available (SNA)";
CM_ SG_ 917 DIR_oilPumpFluidT "Detects oil pump fluid tester.; raw 255 = signal not available (SNA)";
CM_ SG_ 917 DIR_oilPumpPhaseCurrent "Rear drive inverter: oil pump phase current; raw 255 = signal not available (SNA)";
CM_ SG_ 917 DIR_oilPumpPressureEstimate "Oil pump pressure estimate.; raw 255 = signal not available (SNA)";
CM_ SG_ 917 DIR_oilPumpPressureExpected "Oil pump pressure expected.; raw 255 = signal not available (SNA)";
CM_ SG_ 917 DIR_oilPumpPressureResidual "Oil pressure error outside of allowed tolerance; raw 255 = signal not available (SNA)";
CM_ BO_ 614 "Rear drive inverter message: power";
CM_ SG_ 614 DIR_elecPower "Rear drive inverter: elec power; raw 1024 = signal not available (SNA)";
CM_ SG_ 614 DIR_heatPowerOptimal "Rear drive inverter: heat power optimal";
CM_ SG_ 614 DIR_heatPowerMax "Drive Inverter maximum heat power capability";
CM_ SG_ 614 DIR_heatPowerActual "Drive Inverter heat power";
CM_ SG_ 614 DIR_excessHeatCommand "Drive Inverter excess heat command";
CM_ SG_ 614 DIR_drivePowerMax "Rear drive inverter: drive power max; raw 511 = signal not available (SNA)";
CM_ BO_ 789 "Rear drive inverter message: temperature";
CM_ SG_ 789 DIR_tempIndex "Rear drive inverter: temp index";
CM_ SG_ 789 DIR_inverterTQF "Detects the Drive Inverter (DI) outlet temperature qualifier.";
CM_ SG_ 789 DIR_pcbT "Rear drive inverter: pcb t; raw 0 = signal not available (SNA)";
CM_ SG_ 789 DIR_inverterT "Drive Inverter measured outlet temperature";
CM_ SG_ 789 DIR_statorT "Drive Inverter measured stator temperature.; raw 0 = signal not available (SNA)";
CM_ SG_ 789 DIR_dcCapT "Rear drive inverter: dc cap t; raw 0 = signal not available (SNA)";
CM_ SG_ 789 DIR_heatsinkT "Drive Inverter measured heatsink temperature; raw 0 = signal not available (SNA)";
CM_ SG_ 789 DIR_inverterTpct "Rear drive inverter: inverter tpct";
CM_ SG_ 789 DIR_statorTpct "Rear drive inverter: stator tpct";
CM_ SG_ 789 DIR_fluidInTemp "Inlet fluid temperature; raw 0 = signal not available (SNA)";
CM_ SG_ 789 DIR_normalFetBurnIn "Rear drive inverter: normal fet burn in; raw 65535 = signal not available (SNA)";
CM_ SG_ 789 DIR_additionalFetBurnIn "Rear drive inverter: additional fet burn in; raw 65535 = signal not available (SNA)";
CM_ SG_ 789 DIR_currentWeibullMiles "Rear drive inverter: current weibull miles; raw 32767 = signal not available (SNA)";
CM_ SG_ 789 DIR_endOfServiceWeibullMiles "Rear drive inverter: end of service weibull miles; raw 32767 = signal not available (SNA)";
CM_ SG_ 789 DIR_burnInDamageRatio "Rear drive inverter: burn in damage ratio; raw 511 = signal not available (SNA)";
CM_ SG_ 789 DIR_inverterSensorEst "Rear drive inverter: inverter sensor est";
CM_ SG_ 789 DIR_inverterHS1Est "Rear drive inverter: inverter HS1 est";
CM_ SG_ 789 DIR_initialBurnInVehicleOdometer "Rear drive inverter: initial burn in vehicle odometer; raw 4294967295 = signal not available (SNA)";
CM_ SG_ 789 DIR_inverterHS2Est "Rear drive inverter: inverter HS2 est";
CM_ SG_ 789 DIR_inverterInletEst "Rear drive inverter: inverter inlet est";
CM_ SG_ 789 DIR_statorHousingTemp "Rear drive inverter: stator housing temp; raw 0 = signal not available (SNA)";
CM_ BO_ 1495 "Rear drive inverter message: thermal control";
CM_ SG_ 1495 DIR_passiveInletTempReq "Rear drive inverter: passive inlet temp req";
CM_ SG_ 1495 DIR_activeInletTempReq "Rear drive inverter: active inlet temp req";
CM_ SG_ 1495 DIR_coolantFlowReq "Coolant flow requested";
CM_ SG_ 1495 DIR_oilFlowReq "Rear drive inverter: oil flow req; raw 255 = signal not available (SNA)";
CM_ SG_ 1495 DIR_criticalFlowReq "Rear drive inverter: critical flow req";
CM_ SG_ 1495 DIR_burnInStatus "Rear drive inverter: burn in status";
CM_ BO_ 694 "Drive inverter message: chassis control status";
CM_ SG_ 694 DI_vdcTelltaleFlash "Request to flash telltale in UI when VDC is active";
CM_ SG_ 694 DI_vdcTelltaleOn "Request to turn telltale ON in UI when VDC is faulted";
CM_ SG_ 694 DI_tcTelltaleFlash "Request to flash telltale in UI when TC is active";
CM_ SG_ 694 DI_tcTelltaleOn "Request to turn telltale ON in UI when TC is faulted";
CM_ SG_ 694 DI_tractionControlModeUI "Drive inverter: traction control mode UI";
CM_ SG_ 694 DI_ptcStateGlobalUI "Drive inverter: ptc state global UI; raw 3 = signal not available (SNA)";
CM_ SG_ 694 DI_btcStateUI "Drive inverter: btc state UI";
CM_ SG_ 694 DI_vehicleHoldTelltaleOn "Drive inverter: vehicle hold telltale on";
CM_ SG_ 694 DI_opdFeedbackReset "Drive inverter: opd feedback reset";
CM_ SG_ 694 DI_opdFeedbackResetPositiveSpeed "Drive inverter: opd feedback reset positive speeds";
CM_ SG_ 694 DI_slipperySurfaceOnUI "Drive inverter: slippery surface on UI";
CM_ SG_ 694 DI_yellowBrakeTelltaleOn "Request to turn yellow BRAKE telltale ON in UI";
CM_ SG_ 694 DI_greenABSTelltaleOn "Drive inverter: green ABS telltale on";
CM_ SG_ 694 DI_stabilityModeState "Current stability mode setting being honored by the DI";
CM_ BO_ 2007 "Drive inverter message: debug";
CM_ SG_ 2007 DI_debugSelector "Drive inverter: debug selector";
CM_ SG_ 2007 DI_regenBackfillCmd "Drive inverter: regen backfill cmd";
CM_ SG_ 2007 DI_regenBackfillUnavailableReaso "Drive inverter: regen backfill unavailable reason";
CM_ SG_ 2007 DI_regenBackfillAbsSatState "Drive inverter: regen backfill abs sat state";
CM_ SG_ 2007 DI_sysHeatPowerOptimal "Drive inverter: sys heat power optimal";
CM_ SG_ 2007 DI_sysPostPedalMinTorque "Drive inverter: sys post pedal min torque";
CM_ SG_ 2007 DI_sysPostPedalMaxTorque "Drive inverter: sys post pedal max torque";
CM_ SG_ 2007 DI_systemTorqueCommand "Drive inverter: system torque command";
CM_ BO_ 1022 "Drive inverter message: estimated brake temp";
CM_ SG_ 1022 DI_estimatedBrakeTempChecksum "Drive inverter: estimated brake temp checksum";
CM_ SG_ 1022 DI_estimatedBrakeTempCounter "Drive inverter: estimated brake temp counter";
CM_ SG_ 1022 DI_brakeFLTemp "Drive inverter: brake FL temp; raw 1023 = signal not available (SNA)";
CM_ SG_ 1022 DI_brakeFRTemp "Drive inverter: brake FR temp; raw 1023 = signal not available (SNA)";
CM_ SG_ 1022 DI_brakeRLTemp "Drive inverter: brake RL temp; raw 1023 = signal not available (SNA)";
CM_ SG_ 1022 DI_brakeRRTemp "Drive inverter: brake RR temp; raw 1023 = signal not available (SNA)";
CM_ SG_ 1022 DI_mcpIndex "Brake master cylinder pressure index";
CM_ SG_ 1022 DI_mcpIndexPrimeFilt "Filtered brake master cylinder pressure index prime";
CM_ BO_ 1623 "Drive inverter message: info";
CM_ SG_ 1623 DI_infoIndex "Drive inverter: info index";
CM_ SG_ 1623 DI_buildType "Drive inverter: build type";
CM_ SG_ 1623 DI_buildConfigurationId "Drive inverter: build configuration id";
CM_ SG_ 1623 DI_hardwareId "Drive inverter: hardware id";
CM_ SG_ 1623 DI_componentId "Drive inverter: component id";
CM_ SG_ 1623 DI_pcbaId "Drive inverter: pcba id";
CM_ SG_ 1623 DI_assemblyId "Drive inverter: assembly id";
CM_ SG_ 1623 DI_usageId "Drive inverter: usage id";
CM_ SG_ 1623 DI_subUsageId "Drive inverter: sub usage id";
CM_ SG_ 1623 DI_applicationCrc "Drive inverter: application crc";
CM_ SG_ 1623 DI_appGitHash "Drive inverter: app git hash";
CM_ SG_ 1623 DI_bootGitHash "Drive inverter: boot git hash";
CM_ BO_ 950 "Drive inverter message: odometer status";
CM_ SG_ 950 DI_odometer "Total traveled distance; raw 4294967295 = signal not available (SNA)";
CM_ SG_ 950 DI_obdDriveCycleStatus "OBD qualified drive cycle status";
CM_ SG_ 950 DI_odometerStatusCounter "Drive inverter: odometer status counter";
CM_ SG_ 950 DI_odometerStatusChecksum "Drive inverter: odometer status checksum";
CM_ BO_ 296 "Drive inverter message: system limits";
CM_ SG_ 296 DI_limitRegenPower "TRUE when torque is limited due to regen power limit.";
CM_ SG_ 296 DI_limitIBat "TRUE when torque is limited due to battery current.";
CM_ SG_ 296 DI_limitVBatLow "Drive inverter: limit v bat low";
CM_ SG_ 296 DI_limitVBatHigh "Drive inverter: limit v bat high";
CM_ SG_ 296 DI_limitObstacleDetection "TRUE when torque is limited due to obstacle detected in vehicle path.";
CM_ SG_ 296 DI_limitSystemLimp "Drive inverter: limit system limp";
CM_ SG_ 296 DI_limitSystemGPO "Drive inverter: limit system GPO";
CM_ SG_ 296 DI_limitShift "Drive inverter: limit shift";
CM_ SG_ 296 DI_limitDriveTorque "TRUE when drive torque is limited due to driver torque limit command";
CM_ SG_ 296 DI_limitRegenTorque "TRUE when regen torque is limited due to driver torque limit command";
CM_ SG_ 296 DI_limitVehicleSpeed "Drive inverter: limit vehicle speed";
CM_ SG_ 296 DI_limitBmsMiaFreeze "Drive inverter: limit bms mia freeze";
CM_ SG_ 296 DI_limitSystemSpinDownLearning "Drive inverter: limit system spin down learning";
CM_ SG_ 296 DI_limitCdp "Drive inverter: limit cdp";
CM_ SG_ 296 DI_vehicleSpeedLimitType "Speed limit source/type of DI_vehicleSpeedLimit.";
CM_ SG_ 296 DI_vehicleSpeedLimit "Vehicle speed limit (including powertrain limits) being enforced by the DI and published to the UI.; raw 511 = signal not available (SNA)";
CM_ SG_ 296 DI_vehicleSpeedLimitReason "Speed limit reason of DI_vehicleSpeedLimit.";
CM_ SG_ 296 DI_proximity "TRUE if the proximity hardware input signal is active.";
CM_ SG_ 296 DI_limitClosureNotClosed "Drive inverter: limit closure not closed";
CM_ SG_ 296 DI_undersideAbuse "Drive inverter: underside abuse";
CM_ SG_ 296 DI_immobilizerAuthLevel "Immobilizer Authentication Level";
CM_ SG_ 296 DI_manualRecoveryDistanceRemaini "Drive inverter: manual recovery distance remaining; raw 127 = signal not available (SNA)";
CM_ SG_ 296 DI_restrictedDrivingMode "Drive inverter: restricted driving mode";
CM_ BO_ 616 "Drive inverter message: system power";
CM_ SG_ 616 DI_sysHeatPowerMax "Drive inverter: sys heat power max";
CM_ SG_ 616 DI_sysHeatPowerActual "Drive Inverter system heat power";
CM_ SG_ 616 DI_sysDrivePowerMax "Maximum drive power output total for all motors.; raw 511 = signal not available (SNA)";
CM_ SG_ 616 DI_primaryUnitSiliconType "Drive inverter: primary unit silicon type";
CM_ SG_ 616 DI_sysRegenPowerMax "Maximum regen power output total for all motors.; raw 255 = signal not available (SNA)";
CM_ BO_ 280 "Drive inverter message: system status";
CM_ SG_ 280 DI_systemStatusChecksum "Drive inverter: system status checksum";
CM_ SG_ 280 DI_systemStatusCounter "Drive inverter: system status counter";
CM_ SG_ 280 DI_secondaryGearControlStatus "Indicates if gear control through PRND is being honored";
CM_ SG_ 280 DI_immobilizerState "Detects state of the Drive Inverter (DI) immobilizer.; raw 0 = signal not available (SNA)";
CM_ SG_ 280 DI_systemState "DI system state machine state.";
CM_ SG_ 280 DI_brakePedalState "Brake pedal switch signal sensed at the drive inverter.";
CM_ SG_ 280 DI_gear "Detects the current operating gear reported by the drive inverter.; raw 7 = signal not available (SNA)";
CM_ SG_ 280 DI_driveBlocked "Reason drive unit is blocked from entering enable";
CM_ SG_ 280 DI_hvilSystemStatus "Aggregated HVIL system status; raw 3 = signal not available (SNA)";
CM_ SG_ 280 DI_driveModeState "System drive mode state";
CM_ SG_ 280 DI_shiftRequestType "Type of most recent shift request";
CM_ SG_ 280 DI_accelPedalPos "Drive Inverter measured accelerator pedal position.; raw 255 = signal not available (SNA)";
CM_ SG_ 280 DI_tractionControlMode "Active traction control mode as requested by the driver.";
CM_ SG_ 280 DI_dynoModeAvailable "Reports to the vehicle if the Drive Inverter (DI) will accept a request to enter dyno mode.";
CM_ SG_ 280 DI_epbRequest "Reports Electronic Parking Brake (EPB) requests.";
CM_ SG_ 280 DI_brakeSource "Drive inverter: brake source";
CM_ SG_ 280 DI_keepDrivePowerStateRequest "Reports that the Drive Inverter (DI) expects vehicle power state to remain in drive.";
CM_ SG_ 280 DI_trackModeState "Indicates state of Track mode";
CM_ SG_ 280 DI_autonomyControlActive "Drive inverter: autonomy control active";
CM_ SG_ 280 DI_regenLight "Drive inverter: regen light";
CM_ SG_ 280 DI_vehicleAcceleration "Drive inverter: vehicle acceleration; raw 2048 = signal not available (SNA)";
CM_ BO_ 1992 "Left electric parking brake message: info";
CM_ SG_ 1992 EPBL_infoIndex "Left electric parking brake: info index";
CM_ SG_ 1992 EPBL_infoBuildType "Left electric parking brake: info build type";
CM_ SG_ 1992 EPBL_infoBuildConfigId "Left electric parking brake: info build config id";
CM_ SG_ 1992 EPBL_infoHardwareId "Left electric parking brake: info hardware id";
CM_ SG_ 1992 EPBL_infoComponentId "Left electric parking brake: info component id";
CM_ SG_ 1992 EPBL_infoPcbaId "Left electric parking brake: info pcba id";
CM_ SG_ 1992 EPBL_infoAssemblyId "Left electric parking brake: info assembly id; raw 255 = signal not available (SNA)";
CM_ SG_ 1992 EPBL_infoUsageId "Left electric parking brake: info usage id";
CM_ SG_ 1992 EPBL_infoSubUsageId "Left electric parking brake: info sub usage id";
CM_ SG_ 1992 EPBL_infoAppCrc "Left electric parking brake: info app crc";
CM_ SG_ 1992 EPBL_infoAppGitHash "Left electric parking brake: info app git hash";
CM_ SG_ 1992 EPBL_infoBootGitHash "Left electric parking brake: info boot git hash";
CM_ SG_ 1992 EPBL_infoPlatformType "Left electric parking brake: info platform type";
CM_ SG_ 1992 EPBL_infoBootUdsProtoVersion "Left electric parking brake: info boot uds proto version";
CM_ SG_ 1992 EPBL_infoBootCrc "Left electric parking brake: info boot crc";
CM_ BO_ 648 "Left electric parking brake message: internal status";
CM_ SG_ 648 EPBL_unitStatus "Electronic Parking Brake's unit state.";
CM_ SG_ 648 EPBL_unitFaultStatus "Left electric parking brake: unit fault status";
CM_ SG_ 648 EPBL_summonState "Left electric parking brake: summon state";
CM_ SG_ 648 EPBL_disconnected "Left electric parking brake: disconnected";
CM_ SG_ 648 EPBL_pistonTouchingRotor "Left electric parking brake: piston touching rotor";
CM_ SG_ 648 EPBL_csmFaultReason "Left electric parking brake: csm fault reason";
CM_ SG_ 648 EPBL_esmOperationTrigger "Left electric parking brake: esm operation trigger";
CM_ SG_ 648 EPBL_summonFaultReason "Error code associated with previous summon failure.";
CM_ SG_ 648 EPBL_localServiceModeActive "Signal reported by Left electric parking brake";
CM_ SG_ 648 EPBL_localCdpState "Left electric parking brake: local cdp state";
CM_ SG_ 648 EPBL_chimeRequestLocal "Left electric parking brake: chime request local";
CM_ SG_ 648 EPBL_telltaleLocal "Left electric parking brake: telltale local; raw 7 = signal not available (SNA)";
CM_ SG_ 648 EPBL_driverIsLeavingLocal "Left electric parking brake: driver is leaving local";
CM_ SG_ 648 EPBL_driverIsLeavingAnySpeedLoca "Left electric parking brake: driver is leaving any speed local";
CM_ SG_ 648 EPBL_internalCDPRequest "Left electric parking brake: internal CDP request";
CM_ SG_ 648 EPBL_esmSpeedClass "Left electric parking brake: esm speed class";
CM_ SG_ 648 EPBL_learnedEpbConfig "Left electric parking brake: learned epb config";
CM_ SG_ 648 EPBL_internalStatusCounter "Left electric parking brake: internal status counter";
CM_ SG_ 648 EPBL_internalStatusChecksum "Left electric parking brake: internal status checksum";
CM_ BO_ 743 "Left electric parking brake message: seat status3";
CM_ SG_ 743 EPBL_frontSeatCushionFanCur "Left electric parking brake: front seat cushion fan cur";
CM_ SG_ 743 EPBL_frontSeatBackrestFanCur "Left electric parking brake: front seat backrest fan cur";
CM_ SG_ 743 EPBL_frontSeatCushionFanDuty "Left electric parking brake: front seat cushion fan duty";
CM_ SG_ 743 EPBL_frontSeatCushionFanEn "Left electric parking brake: front seat cushion fan en";
CM_ SG_ 743 EPBL_frontSeatBackrestFanEn "Left electric parking brake: front seat backrest fan en";
CM_ SG_ 743 EPBL_frontSeatBackrestFanDuty "Left electric parking brake: front seat backrest fan duty";
BA_DEF_ BO_ "GenMsgCycleTime" INT 0 3600000;
BA_DEF_ BO_ "GenMsgSendType" ENUM "Cyclic","NotUsed","NotUsed","NotUsed","NotUsed","NotUsed","NotUsed","IfActive","NoMsgSendType","NotUsed";
BA_DEF_ BO_ "VFrameFormat" ENUM "StandardCAN","ExtendedCAN","reserved","J1939PG","reserved","reserved","reserved","reserved","reserved","reserved","reserved","reserved","reserved","reserved","StandardCAN_FD","ExtendedCAN_FD";
BA_DEF_ BO_ "CANFD_BRS" ENUM "0","1";
BA_DEF_ SG_ "GenSigSNA" STRING;
BA_DEF_ SG_ "SystemSignalLongSymbol" STRING;
BA_DEF_ SG_ "Confidence" ENUM "validated","plausible","layout-only","contradicted";
BA_DEF_DEF_ "GenMsgCycleTime" 0;
BA_DEF_DEF_ "GenMsgSendType" "NoMsgSendType";
BA_DEF_DEF_ "VFrameFormat" "StandardCAN";
BA_DEF_DEF_ "CANFD_BRS" "1";
BA_DEF_DEF_ "GenSigSNA" "";
BA_DEF_DEF_ "SystemSignalLongSymbol" "";
BA_DEF_DEF_ "Confidence" "layout-only";
BA_ "GenMsgCycleTime" BO_ 530 100;
BA_ "GenMsgSendType" BO_ 530 0;
BA_ "GenMsgCycleTime" BO_ 786 1000;
BA_ "GenMsgSendType" BO_ 786 0;
BA_ "GenMsgCycleTime" BO_ 754 100;
BA_ "GenMsgSendType" BO_ 754 0;
BA_ "GenMsgCycleTime" BO_ 810 5000;
BA_ "GenMsgSendType" BO_ 810 0;
BA_ "GenMsgCycleTime" BO_ 796 100;
BA_ "GenMsgSendType" BO_ 796 0;
BA_ "GenMsgCycleTime" BO_ 797 100;
BA_ "GenMsgSendType" BO_ 797 0;
BA_ "GenMsgCycleTime" BO_ 812 1000;
BA_ "GenMsgSendType" BO_ 812 0;
BA_ "GenMsgCycleTime" BO_ 870 1000;
BA_ "GenMsgSendType" BO_ 870 0;
BA_ "GenMsgCycleTime" BO_ 679 100;
BA_ "GenMsgSendType" BO_ 679 0;
BA_ "GenMsgCycleTime" BO_ 867 1000;
BA_ "GenMsgSendType" BO_ 867 0;
BA_ "GenMsgCycleTime" BO_ 317 100;
BA_ "GenMsgSendType" BO_ 317 0;
BA_ "GenMsgCycleTime" BO_ 669 100;
BA_ "GenMsgSendType" BO_ 669 0;
BA_ "GenMsgCycleTime" BO_ 541 100;
BA_ "GenMsgSendType" BO_ 541 0;
BA_ "GenMsgCycleTime" BO_ 733 1000;
BA_ "GenMsgSendType" BO_ 733 0;
BA_ "GenMsgCycleTime" BO_ 1342 1000;
BA_ "GenMsgSendType" BO_ 1342 0;
BA_ "GenMsgCycleTime" BO_ 1885 200;
BA_ "GenMsgSendType" BO_ 1885 0;
BA_ "GenMsgCycleTime" BO_ 989 1000;
BA_ "GenMsgSendType" BO_ 989 0;
BA_ "GenMsgCycleTime" BO_ 605 100;
BA_ "GenMsgSendType" BO_ 605 0;
BA_ "GenMsgCycleTime" BO_ 893 1000;
BA_ "GenMsgSendType" BO_ 893 0;
BA_ "GenMsgCycleTime" BO_ 1001 500;
BA_ "GenMsgSendType" BO_ 1001 0;
BA_ "GenMsgCycleTime" BO_ 634 100;
BA_ "GenMsgSendType" BO_ 634 0;
BA_ "GenMsgCycleTime" BO_ 741 1000;
BA_ "GenMsgSendType" BO_ 741 0;
BA_ "GenMsgCycleTime" BO_ 886 1000;
BA_ "GenMsgSendType" BO_ 886 0;
BA_ "GenMsgCycleTime" BO_ 1367 1000;
BA_ "GenMsgSendType" BO_ 1367 0;
BA_ "GenMsgCycleTime" BO_ 2005 100;
BA_ "GenMsgSendType" BO_ 2005 0;
BA_ "GenMsgCycleTime" BO_ 633 100;
BA_ "GenMsgSendType" BO_ 633 0;
BA_ "GenMsgCycleTime" BO_ 821 1000;
BA_ "GenMsgSendType" BO_ 821 0;
BA_ "GenMsgCycleTime" BO_ 917 100;
BA_ "GenMsgSendType" BO_ 917 0;
BA_ "GenMsgCycleTime" BO_ 614 1000;
BA_ "GenMsgSendType" BO_ 614 0;
BA_ "GenMsgCycleTime" BO_ 789 1000;
BA_ "GenMsgSendType" BO_ 789 0;
BA_ "GenMsgCycleTime" BO_ 1495 1000;
BA_ "GenMsgSendType" BO_ 1495 0;
BA_ "GenMsgCycleTime" BO_ 694 100;
BA_ "GenMsgSendType" BO_ 694 0;
BA_ "GenMsgCycleTime" BO_ 2007 100;
BA_ "GenMsgSendType" BO_ 2007 0;
BA_ "GenMsgCycleTime" BO_ 1022 1000;
BA_ "GenMsgSendType" BO_ 1022 0;
BA_ "GenMsgCycleTime" BO_ 1623 1000;
BA_ "GenMsgSendType" BO_ 1623 0;
BA_ "GenMsgCycleTime" BO_ 950 1000;
BA_ "GenMsgSendType" BO_ 950 0;
BA_ "GenMsgCycleTime" BO_ 296 100;
BA_ "GenMsgSendType" BO_ 296 0;
BA_ "GenMsgCycleTime" BO_ 616 100;
BA_ "GenMsgSendType" BO_ 616 0;
BA_ "GenMsgCycleTime" BO_ 280 10;
BA_ "GenMsgSendType" BO_ 280 0;
BA_ "GenMsgCycleTime" BO_ 1992 1000;
BA_ "GenMsgSendType" BO_ 1992 0;
BA_ "GenMsgCycleTime" BO_ 648 100;
BA_ "GenMsgSendType" BO_ 648 0;
BA_ "GenMsgCycleTime" BO_ 743 1000;
BA_ "GenMsgSendType" BO_ 743 0;
BA_ "Confidence" SG_ 530 BMS_hvacPowerRequest 0;
BA_ "Confidence" SG_ 530 BMS_notEnoughPowerForDrive 0;
BA_ "Confidence" SG_ 530 BMS_notEnoughPowerForSupport 0;
BA_ "Confidence" SG_ 530 BMS_preconditionAllowed 0;
BA_ "Confidence" SG_ 530 BMS_updateAllowed 0;
BA_ "Confidence" SG_ 530 BMS_cpMiaOnHvs 0;
BA_ "Confidence" SG_ 530 BMS_pcsPwmEnabled 0;
BA_ "Confidence" SG_ 530 BMS_contactorState 0;
BA_ "GenSigSNA" SG_ 530 BMS_contactorState "0";
BA_ "Confidence" SG_ 530 BMS_userChargeStatus 0;
BA_ "Confidence" SG_ 530 BMS_batteryInputPower 0;
BA_ "GenSigSNA" SG_ 530 BMS_batteryInputPower "65535";
BA_ "Confidence" SG_ 530 BMS_chargeRequest 0;
BA_ "Confidence" SG_ 530 BMS_state 0;
BA_ "GenSigSNA" SG_ 530 BMS_state "9";
BA_ "Confidence" SG_ 530 BMS_diLimpRequest 0;
BA_ "Confidence" SG_ 530 BMS_okToShipByAir 0;
BA_ "Confidence" SG_ 530 BMS_okToShipByLand 0;
BA_ "Confidence" SG_ 530 BMS_chgPowerAvailable 0;
BA_ "GenSigSNA" SG_ 530 BMS_chgPowerAvailable "4095";
BA_ "Confidence" SG_ 530 BMS_acManagerState 0;
BA_ "Confidence" SG_ 530 BMS_conditioningRequest 0;
BA_ "Confidence" SG_ 530 BMS_smStateRequest 0;
BA_ "GenSigSNA" SG_ 530 BMS_smStateRequest "9";
BA_ "Confidence" SG_ 530 BMS_hvState 0;
BA_ "Confidence" SG_ 786 BMS_thermalStatusMultiplexer 1;
BA_ "Confidence" SG_ 786 BMS_inletActiveCoolTargetT 0;
BA_ "Confidence" SG_ 786 BMS_inletPassiveTargetT 0;
BA_ "Confidence" SG_ 786 BMS_inletActiveHeatTargetT 0;
BA_ "Confidence" SG_ 786 BMS_requestDischarge 0;
BA_ "Confidence" SG_ 786 BMS_activeHeatingWorthwhile 0;
BA_ "Confidence" SG_ 786 BMS_pcsNoFlowRequest 0;
BA_ "Confidence" SG_ 786 BMS_minPackTemperature 0;
BA_ "Confidence" SG_ 786 BMS_noFlowRequest 0;
BA_ "Confidence" SG_ 786 BMS_maxPackTemperature 0;
BA_ "Confidence" SG_ 786 BMS_flowRequest 0;
BA_ "Confidence" SG_ 786 BMS_coldStagnationLimit 0;
BA_ "Confidence" SG_ 786 BMS_hotStagnationLimit 0;
BA_ "Confidence" SG_ 786 BMS_hotCellTempLimit 0;
BA_ "Confidence" SG_ 786 BMS_i2tDeratingEnabled 0;
BA_ "Confidence" SG_ 786 BMS_activeCoolCellReferenceT 0;
BA_ "Confidence" SG_ 786 BMS_activeHeatCellTargetT 0;
BA_ "Confidence" SG_ 786 BMS_powerDissipation 0;
BA_ "Confidence" SG_ 754 BMS_nmGoingToSleep 0;
BA_ "Confidence" SG_ 754 BMS_nmWakeUpBus 0;
BA_ "Confidence" SG_ 754 BMS_hvsBusAsleep 0;
BA_ "Confidence" SG_ 754 BMS_nmKeepAwakeReason 0;
BA_ "GenSigSNA" SG_ 754 BMS_nmKeepAwakeReason "0";
BA_ "Confidence" SG_ 754 BMS_nmWakeUpReason 0;
BA_ "Confidence" SG_ 810 BMS_thermalEventSuspected 0;
BA_ "Confidence" SG_ 810 BMS_vehicleNotificationsCounter 0;
BA_ "Confidence" SG_ 810 BMS_isolationResistance 0;
BA_ "GenSigSNA" SG_ 810 BMS_isolationResistance "1023";
BA_ "Confidence" SG_ 810 BMS_chgTimeToFull 0;
BA_ "GenSigSNA" SG_ 810 BMS_chgTimeToFull "4095";
BA_ "Confidence" SG_ 810 BMS_vehicleNotificationsChecksum 0;
BA_ "Confidence" SG_ 796 CC_currentLimit 0;
BA_ "GenSigSNA" SG_ 796 CC_currentLimit "255";
BA_ "Confidence" SG_ 796 CC_pilotState 0;
BA_ "GenSigSNA" SG_ 796 CC_pilotState "3";
BA_ "Confidence" SG_ 796 CC_numPhases 0;
BA_ "GenSigSNA" SG_ 796 CC_numPhases "0";
BA_ "Confidence" SG_ 796 CC_line1Voltage 0;
BA_ "GenSigSNA" SG_ 796 CC_line1Voltage "511";
BA_ "Confidence" SG_ 796 CC_gridGrounding 0;
BA_ "GenSigSNA" SG_ 796 CC_gridGrounding "2";
BA_ "Confidence" SG_ 796 CC_deltaTransformer 0;
BA_ "Confidence" SG_ 796 CC_numVehCharging 0;
BA_ "Confidence" SG_ 796 CC_line2Voltage 0;
BA_ "GenSigSNA" SG_ 796 CC_line2Voltage "511";
BA_ "Confidence" SG_ 796 CC_line3Voltage 0;
BA_ "GenSigSNA" SG_ 796 CC_line3Voltage "511";
BA_ "Confidence" SG_ 796 CC_groundResistance 0;
BA_ "GenSigSNA" SG_ 796 CC_groundResistance "4095";
BA_ "Confidence" SG_ 797 CC_chgStatus2Index 1;
BA_ "Confidence" SG_ 797 CC_buttonState 0;
BA_ "Confidence" SG_ 797 EVSE_v2xSupport 0;
BA_ "Confidence" SG_ 797 EVSE_v2xHandshakeStart 0;
BA_ "Confidence" SG_ 797 EVSE_v2xSessionType 0;
BA_ "GenSigSNA" SG_ 797 EVSE_v2xSessionType "0";
BA_ "Confidence" SG_ 812 CC_logIndex 1;
BA_ "Confidence" SG_ 812 CC_activeConnectorID 0;
BA_ "Confidence" SG_ 812 CC_temperature1 0;
BA_ "Confidence" SG_ 812 CC_temperature2 0;
BA_ "Confidence" SG_ 812 CC_temperature3 0;
BA_ "Confidence" SG_ 812 CC_contactor1Closed 0;
BA_ "Confidence" SG_ 812 CC_contactor2Closed 0;
BA_ "Confidence" SG_ 812 CC_temperature4 0;
BA_ "Confidence" SG_ 812 CC_conn1Current 0;
BA_ "GenSigSNA" SG_ 812 CC_conn1Current "255";
BA_ "Confidence" SG_ 812 CC_conn2Current 0;
BA_ "GenSigSNA" SG_ 812 CC_conn2Current "255";
BA_ "Confidence" SG_ 812 CC_conn3Current 0;
BA_ "GenSigSNA" SG_ 812 CC_conn3Current "255";
BA_ "Confidence" SG_ 812 CC_conn4Current 0;
BA_ "GenSigSNA" SG_ 812 CC_conn4Current "255";
BA_ "Confidence" SG_ 812 CC_lifetimei2t 0;
BA_ "Confidence" SG_ 812 CC_lifetimeCtrCycles 0;
BA_ "Confidence" SG_ 812 CC_lifetimeCtrCyclesLoaded 0;
BA_ "Confidence" SG_ 812 CC_lifetimeAlertCount 0;
BA_ "Confidence" SG_ 812 CC_lifetimeThermalFoldbacks 0;
BA_ "Confidence" SG_ 812 CC_lifetimeAvgStartupTemp 0;
BA_ "Confidence" SG_ 870 CMPD_infoIndex 1;
BA_ "Confidence" SG_ 870 CMPD_infoBuildType 0;
BA_ "Confidence" SG_ 870 CMPD_infoBuildConfigId 0;
BA_ "Confidence" SG_ 870 CMPD_infoHardwareId 0;
BA_ "Confidence" SG_ 870 CMPD_infoComponentId 0;
BA_ "Confidence" SG_ 870 CMPD_infoPcbaId 0;
BA_ "Confidence" SG_ 870 CMPD_infoAssemblyId 0;
BA_ "GenSigSNA" SG_ 870 CMPD_infoAssemblyId "255";
BA_ "Confidence" SG_ 870 CMPD_infoUsageId 0;
BA_ "Confidence" SG_ 870 CMPD_infoSubUsageId 0;
BA_ "Confidence" SG_ 679 CMPD_speedRPM 0;
BA_ "Confidence" SG_ 679 CMPD_speedDuty 0;
BA_ "Confidence" SG_ 679 CMPD_inputHVPower 0;
BA_ "Confidence" SG_ 679 CMPD_inputHVCurrent 0;
BA_ "Confidence" SG_ 679 CMPD_inputHVVoltage 0;
BA_ "Confidence" SG_ 679 CMPD_2ShuntModeActive 0;
BA_ "Confidence" SG_ 679 CMPD_powerLimitActive 0;
BA_ "Confidence" SG_ 679 CMPD_state 0;
BA_ "GenSigSNA" SG_ 679 CMPD_state "15";
BA_ "Confidence" SG_ 679 CMPD_wasteHeatState 0;
BA_ "Confidence" SG_ 679 CMPD_powerLimitTooLowToStart 0;
BA_ "Confidence" SG_ 679 CMPD_ready 0;
BA_ "Confidence" SG_ 867 CMP_infoIndex 1;
BA_ "Confidence" SG_ 867 CMP_infoBuildType 0;
BA_ "Confidence" SG_ 867 CMP_infoBuildConfigId 0;
BA_ "Confidence" SG_ 867 CMP_infoHardwareId 0;
BA_ "Confidence" SG_ 867 CMP_infoComponentId 0;
BA_ "Confidence" SG_ 867 CMP_infoPcbaId 0;
BA_ "Confidence" SG_ 867 CMP_infoAssemblyId 0;
BA_ "GenSigSNA" SG_ 867 CMP_infoAssemblyId "255";
BA_ "Confidence" SG_ 867 CMP_infoUsageId 0;
BA_ "Confidence" SG_ 867 CMP_infoSubUsageId 0;
BA_ "Confidence" SG_ 867 CMP_infoPlatformType 0;
BA_ "Confidence" SG_ 867 CMP_infoAppCrc 0;
BA_ "Confidence" SG_ 867 CMP_infoBootUdsProtoVersion 0;
BA_ "Confidence" SG_ 867 CMP_infoBootCrc 0;
BA_ "Confidence" SG_ 317 CP_powerTransferStatus 0;
BA_ "Confidence" SG_ 317 CP_powerTransferShutdownRequest 0;
BA_ "Confidence" SG_ 317 CP_evseAcControlMode 0;
BA_ "Confidence" SG_ 317 CP_v2xCapable 0;
BA_ "Confidence" SG_ 317 CP_evseAcCurrentLimit 0;
BA_ "Confidence" SG_ 317 CP_internalMaxDcCurrentLimit 0;
BA_ "Confidence" SG_ 317 CP_vehicleIsoCheckRequired 0;
BA_ "Confidence" SG_ 317 CP_vehiclePrechargeRequired 0;
BA_ "Confidence" SG_ 317 CP_internalMaxAcCurrentLimit 0;
BA_ "Confidence" SG_ 317 CP_evseChargeType 0;
BA_ "Confidence" SG_ 317 CP_chgLimitMode 0;
BA_ "Confidence" SG_ 317 CP_dcHvInletExposed 0;
BA_ "Confidence" SG_ 317 CP_acHvInletExposed 0;
BA_ "Confidence" SG_ 669 CP_evseOutputDcCurrent 0;
BA_ "Confidence" SG_ 669 CP_evseOutputDcVoltage 0;
BA_ "Confidence" SG_ 669 CP_evseOutputDcCurrentStale 0;
BA_ "Confidence" SG_ 669 CP_evRelocationRecommended 0;
BA_ "Confidence" SG_ 669 CP_evseDeratingReason 0;
BA_ "Confidence" SG_ 541 CP_evseAccept 0;
BA_ "Confidence" SG_ 541 CP_evseRequest 0;
BA_ "Confidence" SG_ 541 CP_proximity 0;
BA_ "GenSigSNA" SG_ 541 CP_proximity "0";
BA_ "Confidence" SG_ 541 CP_pilot 0;
BA_ "GenSigSNA" SG_ 541 CP_pilot "7";
BA_ "Confidence" SG_ 541 CP_digitalCommsEstablished 0;
BA_ "Confidence" SG_ 541 CP_pilotCurrent 0;
BA_ "Confidence" SG_ 541 CP_cableType 0;
BA_ "GenSigSNA" SG_ 541 CP_cableType "5";
BA_ "Confidence" SG_ 541 CP_iecPilotState 0;
BA_ "GenSigSNA" SG_ 541 CP_iecPilotState "9";
BA_ "Confidence" SG_ 541 CP_plcSupported 0;
BA_ "Confidence" SG_ 541 CP_cableCurrentLimit 0;
BA_ "Confidence" SG_ 541 CP_teslaSwcanState 0;
BA_ "Confidence" SG_ 541 CP_evseChargeType_UI 0;
BA_ "Confidence" SG_ 541 CP_gbState 0;
BA_ "Confidence" SG_ 541 CP_gbdcStopChargeReason 0;
BA_ "Confidence" SG_ 541 CP_gbdcFailureReason 0;
BA_ "Confidence" SG_ 541 CP_gbdcChargeAttempts 0;
BA_ "Confidence" SG_ 541 CP_acChargeState 0;
BA_ "Confidence" SG_ 541 CP_acChargeType 0;
BA_ "Confidence" SG_ 541 CP_teslaDcState 0;
BA_ "Confidence" SG_ 733 CP_gridFormFrequencyRequest 0;
BA_ "GenSigSNA" SG_ 733 CP_gridFormFrequencyRequest "4095";
BA_ "Confidence" SG_ 733 CP_gridFormL1NVoltageRequest 0;
BA_ "GenSigSNA" SG_ 733 CP_gridFormL1NVoltageRequest "255";
BA_ "Confidence" SG_ 733 CP_gridFormGroundType 0;
BA_ "GenSigSNA" SG_ 733 CP_gridFormGroundType "0";
BA_ "Confidence" SG_ 733 CP_gridFormGridType 0;
BA_ "GenSigSNA" SG_ 733 CP_gridFormGridType "0";
BA_ "Confidence" SG_ 733 CP_powershareType 0;
BA_ "Confidence" SG_ 733 CP_userPowershareStatus 0;
BA_ "Confidence" SG_ 733 CP_powershareStoppedReason 0;
BA_ "Confidence" SG_ 1342 CP_infoIndex 1;
BA_ "Confidence" SG_ 1342 CP_buildType 0;
BA_ "Confidence" SG_ 1342 CP_buildConfigId 0;
BA_ "Confidence" SG_ 1342 CP_hardwareId 0;
BA_ "Confidence" SG_ 1342 CP_componentId 0;
BA_ "Confidence" SG_ 1342 CP_pcbaId 0;
BA_ "Confidence" SG_ 1342 CP_assemblyId 0;
BA_ "Confidence" SG_ 1342 CP_usageId 0;
BA_ "Confidence" SG_ 1342 CP_subUsageId 0;
BA_ "Confidence" SG_ 1342 CP_platformType 0;
BA_ "Confidence" SG_ 1342 CP_appCrc 0;
BA_ "Confidence" SG_ 1342 CP_appGitHash 0;
BA_ "Confidence" SG_ 1342 CP_bootGitHash 0;
BA_ "Confidence" SG_ 1342 CP_bootUdsProtoVersion 0;
BA_ "Confidence" SG_ 1342 CP_bootCrc 0;
BA_ "Confidence" SG_ 1885 CP_loggingFastSelect 1;
BA_ "Confidence" SG_ 1885 CP_inductiveSensor_raw 0;
BA_ "Confidence" SG_ 1885 CP_doorOpenActuationTime 0;
BA_ "Confidence" SG_ 1885 CP_doorCloseActuationTime 0;
BA_ "Confidence" SG_ 1885 CP_chargeCableSecured 0;
BA_ "Confidence" SG_ 1885 CP_chargeCablePresent 0;
BA_ "Confidence" SG_ 1885 CP_latchCheckAvailable 0;
BA_ "Confidence" SG_ 1885 CP_UHF_controlState 0;
BA_ "Confidence" SG_ 1885 CP_proximityV 0;
BA_ "Confidence" SG_ 1885 CP_proximityV_GBCC1 0;
BA_ "Confidence" SG_ 1885 CP_proximityV_GBCC2 0;
BA_ "Confidence" SG_ 1885 CP_doorPot 0;
BA_ "Confidence" SG_ 1885 CP_doorPresenceSensorV 0;
BA_ "Confidence" SG_ 1885 CP_doorOpenRequest 0;
BA_ "Confidence" SG_ 1885 CP_doorOpenEndOfDriveReason 0;
BA_ "Confidence" SG_ 1885 CP_coverClosed 0;
BA_ "Confidence" SG_ 1885 CP_doorCloseEndOfDriveReason 0;
BA_ "Confidence" SG_ 1885 CP_doorCloseRequest 0;
BA_ "Confidence" SG_ 1885 CP_latchDisengagingTime 0;
BA_ "Confidence" SG_ 1885 CP_latchEngagingTime 0;
BA_ "Confidence" SG_ 1885 CP_latchDisengagingStopReason 0;
BA_ "Confidence" SG_ 1885 CP_latchEngagingStopReason 0;
BA_ "Confidence" SG_ 1885 CP_pilotUnlatchRequestActive 0;
BA_ "Confidence" SG_ 1885 CP_doorIdDetectionState 0;
BA_ "GenSigSNA" SG_ 1885 CP_doorIdDetectionState "0";
BA_ "Confidence" SG_ 1885 CP_doorIdDetectedBin 0;
BA_ "Confidence" SG_ 1885 CP_semiV2LatchNonLinear 0;
BA_ "Confidence" SG_ 989 CP_loggingSlowSelect 1;
BA_ "Confidence" SG_ 989 CP_UHF_chipState 0;
BA_ "Confidence" SG_ 989 CP_UHF_rssi 0;
BA_ "Confidence" SG_ 989 CP_UHF_rxOverflow 0;
BA_ "Confidence" SG_ 989 CP_UHF_rxNumBytes 0;
BA_ "Confidence" SG_ 989 CP_UHF_selfTestRssi 0;
BA_ "Confidence" SG_ 989 CP_latchI 0;
BA_ "Confidence" SG_ 989 CP_inlet1HarnessIdState 0;
BA_ "GenSigSNA" SG_ 989 CP_inlet1HarnessIdState "0";
BA_ "Confidence" SG_ 989 CP_inlet1HarnessIdValue 0;
BA_ "Confidence" SG_ 989 CP_inlet2HarnessIdState 0;
BA_ "GenSigSNA" SG_ 989 CP_inlet2HarnessIdState "0";
BA_ "Confidence" SG_ 989 CP_inlet2HarnessIdValue 0;
BA_ "Confidence" SG_ 989 CP_inletHeaterState 0;
BA_ "Confidence" SG_ 989 CP_inletHeaterDuty 0;
BA_ "Confidence" SG_ 989 CP_5vSwV 0;
BA_ "Confidence" SG_ 989 CP_boardTemperature 0;
BA_ "Confidence" SG_ 989 CP_refVoltage 0;
BA_ "Confidence" SG_ 989 CP_doorId_intervalMin10s 0;
BA_ "Confidence" SG_ 989 CP_doorId_intervalMax10s 0;
BA_ "Confidence" SG_ 989 CP_wakeOnPushCounter 0;
BA_ "Confidence" SG_ 989 CP_doorPushLockoutActive 0;
BA_ "Confidence" SG_ 989 CP_nvm_dataValid 0;
BA_ "Confidence" SG_ 989 CP_nvm_doorOpenCycles 0;
BA_ "Confidence" SG_ 989 CP_nvm_doorCloseCycles 0;
BA_ "Confidence" SG_ 989 CP_nvm_doorOpen 0;
BA_ "Confidence" SG_ 989 CP_nvm_doorPresent 0;
BA_ "Confidence" SG_ 989 CP_nvm_doorPresentValid 0;
BA_ "Confidence" SG_ 989 CP_nvm_badPilotDiodeDetected 0;
BA_ "Confidence" SG_ 989 CP_nvm_pilotDiodeFaultCount 0;
BA_ "Confidence" SG_ 989 CP_doorOpenLimiterMaxCount 0;
BA_ "Confidence" SG_ 989 CP_doorOpenLimiterMaxRequestType 0;
BA_ "Confidence" SG_ 989 CP_doorCloseLimiterMaxCount 0;
BA_ "Confidence" SG_ 989 CP_doorCloseLimiterMaxRequestTyp 0;
BA_ "SystemSignalLongSymbol" SG_ 989 CP_doorCloseLimiterMaxRequestTyp "CP_doorCloseLimiterMaxRequestType";
BA_ "Confidence" SG_ 989 CP_proximityWakeCounter 0;
BA_ "Confidence" SG_ 605 CP_type 0;
BA_ "Confidence" SG_ 605 CP_insertEnableLine 0;
BA_ "Confidence" SG_ 605 CP_latchState 0;
BA_ "GenSigSNA" SG_ 605 CP_latchState "0";
BA_ "Confidence" SG_ 605 CP_permanentPowerRequest 0;
BA_ "Confidence" SG_ 605 CP_chargeDoorOpen 0;
BA_ "Confidence" SG_ 605 CP_doorControlState 0;
BA_ "Confidence" SG_ 605 CP_doorButtonPressed 0;
BA_ "Confidence" SG_ 605 CP_swcanRelayClosed 0;
BA_ "Confidence" SG_ 605 CP_inhibitOta 0;
BA_ "Confidence" SG_ 605 CP_chargeCableState 0;
BA_ "GenSigSNA" SG_ 605 CP_chargeCableState "0";
BA_ "Confidence" SG_ 605 CP_latchControlState 0;
BA_ "Confidence" SG_ 605 CP_ledColor 0;
BA_ "Confidence" SG_ 605 CP_UHF_handleFound 0;
BA_ "Confidence" SG_ 605 CP_faultLineSensed 0;
BA_ "Confidence" SG_ 605 CP_doorPresenceState 0;
BA_ "Confidence" SG_ 605 CP_inductiveSensorState 0;
BA_ "Confidence" SG_ 605 CP_chargeDoorOpenUI 0;
BA_ "Confidence" SG_ 605 CP_vehicleUnlockRequest 0;
BA_ "Confidence" SG_ 605 CP_coldWeatherMode 0;
BA_ "Confidence" SG_ 605 CP_latchEngaged 0;
BA_ "Confidence" SG_ 605 CP_inletHeaterUiState 0;
BA_ "Confidence" SG_ 605 CP_userEvseModelType 0;
BA_ "Confidence" SG_ 605 CP_evseGridFormHardwareType 0;
BA_ "GenSigSNA" SG_ 605 CP_evseGridFormHardwareType "15";
BA_ "Confidence" SG_ 605 CP_faultLineV 0;
BA_ "Confidence" SG_ 605 CP_faultLineSetByCP 0;
BA_ "Confidence" SG_ 605 CP_AuthManagerState 0;
BA_ "Confidence" SG_ 893 CP_thermalStatusSelect 1;
BA_ "Confidence" SG_ 893 CP_pinTemperature1 0;
BA_ "Confidence" SG_ 893 CP_pinTemperature2 0;
BA_ "Confidence" SG_ 893 CP_pinTemperature3 0;
BA_ "Confidence" SG_ 893 CP_pinTemperature4 0;
BA_ "Confidence" SG_ 893 CP_pinTemp4Velocity 0;
BA_ "GenSigSNA" SG_ 893 CP_pinTemp4Velocity "511";
BA_ "Confidence" SG_ 1001 DAS_headlightRequest 0;
BA_ "Confidence" SG_ 1001 DAS_hazardLightRequest 0;
BA_ "GenSigSNA" SG_ 1001 DAS_hazardLightRequest "3";
BA_ "Confidence" SG_ 1001 DAS_wiperSpeed 0;
BA_ "Confidence" SG_ 1001 DAS_turnIndicatorRequest 0;
BA_ "Confidence" SG_ 1001 DAS_highLowBeamDecision 0;
BA_ "GenSigSNA" SG_ 1001 DAS_highLowBeamDecision "3";
BA_ "Confidence" SG_ 1001 DAS_heaterRequest 0;
BA_ "GenSigSNA" SG_ 1001 DAS_heaterRequest "0";
BA_ "Confidence" SG_ 1001 DAS_highLowBeamOffReason 0;
BA_ "GenSigSNA" SG_ 1001 DAS_highLowBeamOffReason "5";
BA_ "Confidence" SG_ 1001 DAS_forwardCamHeaterDutyCycle 0;
BA_ "Confidence" SG_ 1001 DAS_dynamicBrakeLightRequest 0;
BA_ "Confidence" SG_ 1001 DAS_radarHeaterRequest 0;
BA_ "Confidence" SG_ 1001 DAS_ahlbOverride 0;
BA_ "Confidence" SG_ 1001 DAS_mirrorFoldRequest 0;
BA_ "GenSigSNA" SG_ 1001 DAS_mirrorFoldRequest "3";
BA_ "Confidence" SG_ 1001 DAS_wiperWashRequest 0;
BA_ "Confidence" SG_ 1001 DAS_ulcConfirmationRequestActive 0;
BA_ "Confidence" SG_ 1001 DAS_overrideWiperSetting 0;
BA_ "Confidence" SG_ 1001 DAS_autoWiperState 0;
BA_ "GenSigSNA" SG_ 1001 DAS_autoWiperState "5";
BA_ "Confidence" SG_ 1001 DAS_turnIndicatorRequestReason 0;
BA_ "Confidence" SG_ 1001 DAS_forwardRadarPowerRequest 0;
BA_ "Confidence" SG_ 1001 DAS_driverDomeLightRequest 0;
BA_ "Confidence" SG_ 1001 DAS_drivePowerStateRequest 0;
BA_ "Confidence" SG_ 1001 DAS_enableIcrDataCollection 0;
BA_ "Confidence" SG_ 1001 DAS_rPillarCamHeaterDutyCycle 0;
BA_ "Confidence" SG_ 1001 DAS_adaptiveHighBeamIsFaulted 0;
BA_ "Confidence" SG_ 1001 DAS_restrictDoorReleaseLeft 0;
BA_ "Confidence" SG_ 1001 DAS_restrictDoorReleaseRight 0;
BA_ "Confidence" SG_ 1001 DAS_bodyControlsCounter 0;
BA_ "Confidence" SG_ 1001 DAS_bodyControlsChecksum 0;
BA_ "Confidence" SG_ 634 DIF_hvStatusChecksum 0;
BA_ "Confidence" SG_ 634 DIF_hvStatusCounter 0;
BA_ "Confidence" SG_ 634 DIF_hvilCurrent 0;
BA_ "Confidence" SG_ 634 DIF_hvilCmVoltage 0;
BA_ "Confidence" SG_ 634 DIF_hvilStatus 0;
BA_ "GenSigSNA" SG_ 634 DIF_hvilStatus "3";
BA_ "Confidence" SG_ 634 DIF_hvilSupplyState 0;
BA_ "Confidence" SG_ 634 DIF_activeDischargeCtrl 0;
BA_ "Confidence" SG_ 634 DIF_activeDischargeStatus 0;
BA_ "Confidence" SG_ 634 DIF_vBat 0;
BA_ "Confidence" SG_ 634 DIF_vBatQF 0;
BA_ "Confidence" SG_ 634 DIF_powerStageSafeState 0;
BA_ "Confidence" SG_ 634 DIF_fluxState 0;
BA_ "Confidence" SG_ 634 DIF_vBusDiag 0;
BA_ "Confidence" SG_ 634 DIF_gateDriveState 0;
BA_ "Confidence" SG_ 634 DIF_gateDriveSupplyState 0;
BA_ "Confidence" SG_ 741 DIF_elecPower 0;
BA_ "GenSigSNA" SG_ 741 DIF_elecPower "1024";
BA_ "Confidence" SG_ 741 DIF_heatPowerOptimal 0;
BA_ "Confidence" SG_ 741 DIF_heatPowerMax 0;
BA_ "Confidence" SG_ 741 DIF_heatPowerActual 0;
BA_ "Confidence" SG_ 741 DIF_excessHeatCommand 0;
BA_ "Confidence" SG_ 741 DIF_drivePowerMax 0;
BA_ "GenSigSNA" SG_ 741 DIF_drivePowerMax "511";
BA_ "Confidence" SG_ 886 DIF_tempIndex 1;
BA_ "Confidence" SG_ 886 DIF_inverterTQF 0;
BA_ "Confidence" SG_ 886 DIF_pcbT 0;
BA_ "GenSigSNA" SG_ 886 DIF_pcbT "0";
BA_ "Confidence" SG_ 886 DIF_inverterT 0;
BA_ "Confidence" SG_ 886 DIF_statorT 0;
BA_ "GenSigSNA" SG_ 886 DIF_statorT "0";
BA_ "Confidence" SG_ 886 DIF_dcCapT 0;
BA_ "GenSigSNA" SG_ 886 DIF_dcCapT "0";
BA_ "Confidence" SG_ 886 DIF_heatsinkT 0;
BA_ "GenSigSNA" SG_ 886 DIF_heatsinkT "0";
BA_ "Confidence" SG_ 886 DIF_inverterTpct 0;
BA_ "Confidence" SG_ 886 DIF_statorTpct 0;
BA_ "Confidence" SG_ 886 DIF_fluidInTemp 0;
BA_ "GenSigSNA" SG_ 886 DIF_fluidInTemp "0";
BA_ "Confidence" SG_ 886 DIF_normalFetBurnIn 0;
BA_ "GenSigSNA" SG_ 886 DIF_normalFetBurnIn "65535";
BA_ "Confidence" SG_ 886 DIF_additionalFetBurnIn 0;
BA_ "GenSigSNA" SG_ 886 DIF_additionalFetBurnIn "65535";
BA_ "Confidence" SG_ 886 DIF_currentWeibullMiles 0;
BA_ "GenSigSNA" SG_ 886 DIF_currentWeibullMiles "32767";
BA_ "Confidence" SG_ 886 DIF_endOfServiceWeibullMiles 0;
BA_ "GenSigSNA" SG_ 886 DIF_endOfServiceWeibullMiles "32767";
BA_ "Confidence" SG_ 886 DIF_burnInDamageRatio 0;
BA_ "GenSigSNA" SG_ 886 DIF_burnInDamageRatio "511";
BA_ "Confidence" SG_ 886 DIF_inverterSensorEst 0;
BA_ "Confidence" SG_ 886 DIF_inverterHS1Est 0;
BA_ "Confidence" SG_ 886 DIF_initialBurnInVehicleOdometer 0;
BA_ "GenSigSNA" SG_ 886 DIF_initialBurnInVehicleOdometer "4294967295";
BA_ "Confidence" SG_ 886 DIF_inverterHS2Est 0;
BA_ "Confidence" SG_ 886 DIF_inverterInletEst 0;
BA_ "Confidence" SG_ 886 DIF_statorHousingTemp 0;
BA_ "GenSigSNA" SG_ 886 DIF_statorHousingTemp "0";
BA_ "Confidence" SG_ 1367 DIF_passiveInletTempReq 0;
BA_ "Confidence" SG_ 1367 DIF_activeInletTempReq 0;
BA_ "Confidence" SG_ 1367 DIF_coolantFlowReq 0;
BA_ "Confidence" SG_ 1367 DIF_oilFlowReq 0;
BA_ "GenSigSNA" SG_ 1367 DIF_oilFlowReq "255";
BA_ "Confidence" SG_ 1367 DIF_criticalFlowReq 0;
BA_ "Confidence" SG_ 1367 DIF_burnInStatus 0;
BA_ "Confidence" SG_ 2005 DIR_debugSelector 1;
BA_ "Confidence" SG_ 2005 DIR_phaseOutBusbarTemp 0;
BA_ "GenSigSNA" SG_ 2005 DIR_phaseOutBusbarTemp "0";
BA_ "Confidence" SG_ 2005 DIR_phaseOutBusbarWeldTemp 0;
BA_ "GenSigSNA" SG_ 2005 DIR_phaseOutBusbarWeldTemp "0";
BA_ "Confidence" SG_ 2005 DIR_phaseOutLugTemp 0;
BA_ "GenSigSNA" SG_ 2005 DIR_phaseOutLugTemp "0";
BA_ "Confidence" SG_ 2005 DIR_dcLinkCapTemp 0;
BA_ "GenSigSNA" SG_ 2005 DIR_dcLinkCapTemp "0";
BA_ "Confidence" SG_ 2005 DIR_hvDcCableTemp 0;
BA_ "GenSigSNA" SG_ 2005 DIR_hvDcCableTemp "0";
BA_ "Confidence" SG_ 2005 DIR_negDcBusbarTemp 0;
BA_ "GenSigSNA" SG_ 2005 DIR_negDcBusbarTemp "0";
BA_ "Confidence" SG_ 2005 DIR_posDcBusbarTemp 0;
BA_ "GenSigSNA" SG_ 2005 DIR_posDcBusbarTemp "0";
BA_ "Confidence" SG_ 2005 DIR_statorEndWindingTemp 0;
BA_ "GenSigSNA" SG_ 2005 DIR_statorEndWindingTemp "0";
BA_ "Confidence" SG_ 2005 DIR_rotorMaxMagnetTemp 0;
BA_ "GenSigSNA" SG_ 2005 DIR_rotorMaxMagnetTemp "0";
BA_ "Confidence" SG_ 2005 DIR_lightSenseV 0;
BA_ "Confidence" SG_ 2005 DIR_pyroSenseV 0;
BA_ "Confidence" SG_ 2005 DIR_statorSlotWindingTemp 0;
BA_ "GenSigSNA" SG_ 2005 DIR_statorSlotWindingTemp "0";
BA_ "Confidence" SG_ 2005 DIR_intervalMaxHvBusV 0;
BA_ "Confidence" SG_ 633 DIR_hvStatusChecksum 0;
BA_ "Confidence" SG_ 633 DIR_hvStatusCounter 0;
BA_ "Confidence" SG_ 633 DIR_hvilCurrent 0;
BA_ "Confidence" SG_ 633 DIR_hvilCmVoltage 0;
BA_ "Confidence" SG_ 633 DIR_hvilStatus 0;
BA_ "GenSigSNA" SG_ 633 DIR_hvilStatus "3";
BA_ "Confidence" SG_ 633 DIR_hvilSupplyState 0;
BA_ "Confidence" SG_ 633 DIR_activeDischargeCtrl 0;
BA_ "Confidence" SG_ 633 DIR_activeDischargeStatus 0;
BA_ "Confidence" SG_ 633 DIR_vBat 0;
BA_ "Confidence" SG_ 633 DIR_vBatQF 0;
BA_ "Confidence" SG_ 633 DIR_powerStageSafeState 0;
BA_ "Confidence" SG_ 633 DIR_fluxState 0;
BA_ "Confidence" SG_ 633 DIR_vBusDiag 0;
BA_ "Confidence" SG_ 633 DIR_gateDriveState 0;
BA_ "Confidence" SG_ 633 DIR_gateDriveSupplyState 0;
BA_ "Confidence" SG_ 821 DIR_infoIndex 1;
BA_ "Confidence" SG_ 821 DIR_buildType 0;
BA_ "Confidence" SG_ 821 DIR_buildConfigurationId 0;
BA_ "Confidence" SG_ 821 DIR_hardwareId 0;
BA_ "Confidence" SG_ 821 DIR_componentId 0;
BA_ "Confidence" SG_ 821 DIR_pcbaId 0;
BA_ "Confidence" SG_ 821 DIR_assemblyId 0;
BA_ "Confidence" SG_ 821 DIR_usageId 0;
BA_ "Confidence" SG_ 821 DIR_subUsageId 0;
BA_ "Confidence" SG_ 821 DIR_motorType 0;
BA_ "GenSigSNA" SG_ 821 DIR_motorType "0";
BA_ "Confidence" SG_ 821 DIR_siliconType 0;
BA_ "Confidence" SG_ 821 DIR_mechSafeStateType 0;
BA_ "GenSigSNA" SG_ 821 DIR_mechSafeStateType "0";
BA_ "Confidence" SG_ 821 DIR_applicationCrc 0;
BA_ "Confidence" SG_ 821 DIR_oilPumpBuildType 0;
BA_ "Confidence" SG_ 821 DIR_oilPumpAppCrc 0;
BA_ "Confidence" SG_ 821 DIR_FPGA_version 0;
BA_ "GenSigSNA" SG_ 821 DIR_FPGA_version "255";
BA_ "Confidence" SG_ 821 DIR_appGitHash 0;
BA_ "Confidence" SG_ 821 DIR_bootGitHash 0;
BA_ "Confidence" SG_ 821 DIR_infoBootLdUdsProtocolVersion 0;
BA_ "Confidence" SG_ 821 DIR_bootloaderCrc 0;
BA_ "Confidence" SG_ 821 DIR_oilPumpPcbaId 0;
BA_ "Confidence" SG_ 821 DIR_oilPumpAssemblyId 0;
BA_ "Confidence" SG_ 821 DIR_oilPumpUsageId 0;
BA_ "Confidence" SG_ 821 DIR_refRotorFlux 0;
BA_ "Confidence" SG_ 821 DIR_refRotorOffset 0;
BA_ "GenSigSNA" SG_ 821 DIR_refRotorOffset "2048";
BA_ "Confidence" SG_ 821 DIR_speedWearTotal 0;
BA_ "GenSigSNA" SG_ 821 DIR_speedWearTotal "255";
BA_ "Confidence" SG_ 821 DIR_torqueWearTotal 0;
BA_ "GenSigSNA" SG_ 821 DIR_torqueWearTotal "255";
BA_ "Confidence" SG_ 917 DIR_oilPumpState 0;
BA_ "GenSigSNA" SG_ 917 DIR_oilPumpState "7";
BA_ "Confidence" SG_ 917 DIR_oilPumpFluidTQF 0;
BA_ "Confidence" SG_ 917 DIR_oilPumpLeadAngle 0;
BA_ "Confidence" SG_ 917 DIR_oilPumpFlowTarget 0;
BA_ "GenSigSNA" SG_ 917 DIR_oilPumpFlowTarget "255";
BA_ "Confidence" SG_ 917 DIR_oilPumpFlowActual 0;
BA_ "GenSigSNA" SG_ 917 DIR_oilPumpFlowActual "255";
BA_ "Confidence" SG_ 917 DIR_oilPumpFluidT 0;
BA_ "GenSigSNA" SG_ 917 DIR_oilPumpFluidT "255";
BA_ "Confidence" SG_ 917 DIR_oilPumpPhaseCurrent 0;
BA_ "GenSigSNA" SG_ 917 DIR_oilPumpPhaseCurrent "255";
BA_ "Confidence" SG_ 917 DIR_oilPumpPressureEstimate 0;
BA_ "GenSigSNA" SG_ 917 DIR_oilPumpPressureEstimate "255";
BA_ "Confidence" SG_ 917 DIR_oilPumpPressureExpected 0;
BA_ "GenSigSNA" SG_ 917 DIR_oilPumpPressureExpected "255";
BA_ "Confidence" SG_ 917 DIR_oilPumpPressureResidual 0;
BA_ "GenSigSNA" SG_ 917 DIR_oilPumpPressureResidual "255";
BA_ "Confidence" SG_ 614 DIR_elecPower 0;
BA_ "GenSigSNA" SG_ 614 DIR_elecPower "1024";
BA_ "Confidence" SG_ 614 DIR_heatPowerOptimal 0;
BA_ "Confidence" SG_ 614 DIR_heatPowerMax 0;
BA_ "Confidence" SG_ 614 DIR_heatPowerActual 0;
BA_ "Confidence" SG_ 614 DIR_excessHeatCommand 0;
BA_ "Confidence" SG_ 614 DIR_drivePowerMax 0;
BA_ "GenSigSNA" SG_ 614 DIR_drivePowerMax "511";
BA_ "Confidence" SG_ 789 DIR_tempIndex 1;
BA_ "Confidence" SG_ 789 DIR_inverterTQF 0;
BA_ "Confidence" SG_ 789 DIR_pcbT 0;
BA_ "GenSigSNA" SG_ 789 DIR_pcbT "0";
BA_ "Confidence" SG_ 789 DIR_inverterT 0;
BA_ "Confidence" SG_ 789 DIR_statorT 0;
BA_ "GenSigSNA" SG_ 789 DIR_statorT "0";
BA_ "Confidence" SG_ 789 DIR_dcCapT 0;
BA_ "GenSigSNA" SG_ 789 DIR_dcCapT "0";
BA_ "Confidence" SG_ 789 DIR_heatsinkT 0;
BA_ "GenSigSNA" SG_ 789 DIR_heatsinkT "0";
BA_ "Confidence" SG_ 789 DIR_inverterTpct 0;
BA_ "Confidence" SG_ 789 DIR_statorTpct 0;
BA_ "Confidence" SG_ 789 DIR_fluidInTemp 0;
BA_ "GenSigSNA" SG_ 789 DIR_fluidInTemp "0";
BA_ "Confidence" SG_ 789 DIR_normalFetBurnIn 0;
BA_ "GenSigSNA" SG_ 789 DIR_normalFetBurnIn "65535";
BA_ "Confidence" SG_ 789 DIR_additionalFetBurnIn 0;
BA_ "GenSigSNA" SG_ 789 DIR_additionalFetBurnIn "65535";
BA_ "Confidence" SG_ 789 DIR_currentWeibullMiles 0;
BA_ "GenSigSNA" SG_ 789 DIR_currentWeibullMiles "32767";
BA_ "Confidence" SG_ 789 DIR_endOfServiceWeibullMiles 0;
BA_ "GenSigSNA" SG_ 789 DIR_endOfServiceWeibullMiles "32767";
BA_ "Confidence" SG_ 789 DIR_burnInDamageRatio 0;
BA_ "GenSigSNA" SG_ 789 DIR_burnInDamageRatio "511";
BA_ "Confidence" SG_ 789 DIR_inverterSensorEst 0;
BA_ "Confidence" SG_ 789 DIR_inverterHS1Est 0;
BA_ "Confidence" SG_ 789 DIR_initialBurnInVehicleOdometer 0;
BA_ "GenSigSNA" SG_ 789 DIR_initialBurnInVehicleOdometer "4294967295";
BA_ "Confidence" SG_ 789 DIR_inverterHS2Est 0;
BA_ "Confidence" SG_ 789 DIR_inverterInletEst 0;
BA_ "Confidence" SG_ 789 DIR_statorHousingTemp 0;
BA_ "GenSigSNA" SG_ 789 DIR_statorHousingTemp "0";
BA_ "Confidence" SG_ 1495 DIR_passiveInletTempReq 0;
BA_ "Confidence" SG_ 1495 DIR_activeInletTempReq 0;
BA_ "Confidence" SG_ 1495 DIR_coolantFlowReq 0;
BA_ "Confidence" SG_ 1495 DIR_oilFlowReq 0;
BA_ "GenSigSNA" SG_ 1495 DIR_oilFlowReq "255";
BA_ "Confidence" SG_ 1495 DIR_criticalFlowReq 0;
BA_ "Confidence" SG_ 1495 DIR_burnInStatus 0;
BA_ "Confidence" SG_ 694 DI_vdcTelltaleFlash 0;
BA_ "Confidence" SG_ 694 DI_vdcTelltaleOn 0;
BA_ "Confidence" SG_ 694 DI_tcTelltaleFlash 0;
BA_ "Confidence" SG_ 694 DI_tcTelltaleOn 0;
BA_ "Confidence" SG_ 694 DI_tractionControlModeUI 0;
BA_ "Confidence" SG_ 694 DI_ptcStateGlobalUI 0;
BA_ "GenSigSNA" SG_ 694 DI_ptcStateGlobalUI "3";
BA_ "Confidence" SG_ 694 DI_btcStateUI 0;
BA_ "Confidence" SG_ 694 DI_vehicleHoldTelltaleOn 0;
BA_ "Confidence" SG_ 694 DI_opdFeedbackReset 0;
BA_ "Confidence" SG_ 694 DI_opdFeedbackResetPositiveSpeed 0;
BA_ "SystemSignalLongSymbol" SG_ 694 DI_opdFeedbackResetPositiveSpeed "DI_opdFeedbackResetPositiveSpeeds";
BA_ "Confidence" SG_ 694 DI_slipperySurfaceOnUI 0;
BA_ "Confidence" SG_ 694 DI_yellowBrakeTelltaleOn 0;
BA_ "Confidence" SG_ 694 DI_greenABSTelltaleOn 0;
BA_ "Confidence" SG_ 694 DI_stabilityModeState 0;
BA_ "Confidence" SG_ 2007 DI_debugSelector 1;
BA_ "Confidence" SG_ 2007 DI_regenBackfillCmd 0;
BA_ "Confidence" SG_ 2007 DI_regenBackfillUnavailableReaso 0;
BA_ "SystemSignalLongSymbol" SG_ 2007 DI_regenBackfillUnavailableReaso "DI_regenBackfillUnavailableReason";
BA_ "Confidence" SG_ 2007 DI_regenBackfillAbsSatState 0;
BA_ "Confidence" SG_ 2007 DI_sysHeatPowerOptimal 0;
BA_ "Confidence" SG_ 2007 DI_sysPostPedalMinTorque 0;
BA_ "Confidence" SG_ 2007 DI_sysPostPedalMaxTorque 0;
BA_ "Confidence" SG_ 2007 DI_systemTorqueCommand 0;
BA_ "Confidence" SG_ 1022 DI_estimatedBrakeTempChecksum 0;
BA_ "Confidence" SG_ 1022 DI_estimatedBrakeTempCounter 0;
BA_ "Confidence" SG_ 1022 DI_brakeFLTemp 0;
BA_ "GenSigSNA" SG_ 1022 DI_brakeFLTemp "1023";
BA_ "Confidence" SG_ 1022 DI_brakeFRTemp 0;
BA_ "GenSigSNA" SG_ 1022 DI_brakeFRTemp "1023";
BA_ "Confidence" SG_ 1022 DI_brakeRLTemp 0;
BA_ "GenSigSNA" SG_ 1022 DI_brakeRLTemp "1023";
BA_ "Confidence" SG_ 1022 DI_brakeRRTemp 0;
BA_ "GenSigSNA" SG_ 1022 DI_brakeRRTemp "1023";
BA_ "Confidence" SG_ 1022 DI_mcpIndex 0;
BA_ "Confidence" SG_ 1022 DI_mcpIndexPrimeFilt 0;
BA_ "Confidence" SG_ 1623 DI_infoIndex 1;
BA_ "Confidence" SG_ 1623 DI_buildType 0;
BA_ "Confidence" SG_ 1623 DI_buildConfigurationId 0;
BA_ "Confidence" SG_ 1623 DI_hardwareId 0;
BA_ "Confidence" SG_ 1623 DI_componentId 0;
BA_ "Confidence" SG_ 1623 DI_pcbaId 0;
BA_ "Confidence" SG_ 1623 DI_assemblyId 0;
BA_ "Confidence" SG_ 1623 DI_usageId 0;
BA_ "Confidence" SG_ 1623 DI_subUsageId 0;
BA_ "Confidence" SG_ 1623 DI_applicationCrc 0;
BA_ "Confidence" SG_ 1623 DI_appGitHash 0;
BA_ "Confidence" SG_ 1623 DI_bootGitHash 0;
BA_ "Confidence" SG_ 950 DI_odometer 0;
BA_ "GenSigSNA" SG_ 950 DI_odometer "4294967295";
BA_ "Confidence" SG_ 950 DI_obdDriveCycleStatus 0;
BA_ "Confidence" SG_ 950 DI_odometerStatusCounter 0;
BA_ "Confidence" SG_ 950 DI_odometerStatusChecksum 0;
BA_ "Confidence" SG_ 296 DI_limitRegenPower 0;
BA_ "Confidence" SG_ 296 DI_limitIBat 0;
BA_ "Confidence" SG_ 296 DI_limitVBatLow 0;
BA_ "Confidence" SG_ 296 DI_limitVBatHigh 0;
BA_ "Confidence" SG_ 296 DI_limitObstacleDetection 0;
BA_ "Confidence" SG_ 296 DI_limitSystemLimp 0;
BA_ "Confidence" SG_ 296 DI_limitSystemGPO 0;
BA_ "Confidence" SG_ 296 DI_limitShift 0;
BA_ "Confidence" SG_ 296 DI_limitDriveTorque 0;
BA_ "Confidence" SG_ 296 DI_limitRegenTorque 0;
BA_ "Confidence" SG_ 296 DI_limitVehicleSpeed 0;
BA_ "Confidence" SG_ 296 DI_limitBmsMiaFreeze 0;
BA_ "Confidence" SG_ 296 DI_limitSystemSpinDownLearning 0;
BA_ "Confidence" SG_ 296 DI_limitCdp 0;
BA_ "Confidence" SG_ 296 DI_vehicleSpeedLimitType 0;
BA_ "Confidence" SG_ 296 DI_vehicleSpeedLimit 0;
BA_ "GenSigSNA" SG_ 296 DI_vehicleSpeedLimit "511";
BA_ "Confidence" SG_ 296 DI_vehicleSpeedLimitReason 0;
BA_ "Confidence" SG_ 296 DI_proximity 0;
BA_ "Confidence" SG_ 296 DI_limitClosureNotClosed 0;
BA_ "Confidence" SG_ 296 DI_undersideAbuse 0;
BA_ "Confidence" SG_ 296 DI_immobilizerAuthLevel 0;
BA_ "Confidence" SG_ 296 DI_manualRecoveryDistanceRemaini 0;
BA_ "GenSigSNA" SG_ 296 DI_manualRecoveryDistanceRemaini "127";
BA_ "SystemSignalLongSymbol" SG_ 296 DI_manualRecoveryDistanceRemaini "DI_manualRecoveryDistanceRemaining";
BA_ "Confidence" SG_ 296 DI_restrictedDrivingMode 0;
BA_ "Confidence" SG_ 616 DI_sysHeatPowerMax 0;
BA_ "Confidence" SG_ 616 DI_sysHeatPowerActual 0;
BA_ "Confidence" SG_ 616 DI_sysDrivePowerMax 0;
BA_ "GenSigSNA" SG_ 616 DI_sysDrivePowerMax "511";
BA_ "Confidence" SG_ 616 DI_primaryUnitSiliconType 0;
BA_ "Confidence" SG_ 616 DI_sysRegenPowerMax 0;
BA_ "GenSigSNA" SG_ 616 DI_sysRegenPowerMax "255";
BA_ "Confidence" SG_ 280 DI_systemStatusChecksum 0;
BA_ "Confidence" SG_ 280 DI_systemStatusCounter 0;
BA_ "Confidence" SG_ 280 DI_secondaryGearControlStatus 0;
BA_ "Confidence" SG_ 280 DI_immobilizerState 0;
BA_ "GenSigSNA" SG_ 280 DI_immobilizerState "0";
BA_ "Confidence" SG_ 280 DI_systemState 0;
BA_ "Confidence" SG_ 280 DI_brakePedalState 0;
BA_ "Confidence" SG_ 280 DI_gear 0;
BA_ "GenSigSNA" SG_ 280 DI_gear "7";
BA_ "Confidence" SG_ 280 DI_driveBlocked 0;
BA_ "Confidence" SG_ 280 DI_hvilSystemStatus 0;
BA_ "GenSigSNA" SG_ 280 DI_hvilSystemStatus "3";
BA_ "Confidence" SG_ 280 DI_driveModeState 0;
BA_ "Confidence" SG_ 280 DI_shiftRequestType 0;
BA_ "Confidence" SG_ 280 DI_accelPedalPos 0;
BA_ "GenSigSNA" SG_ 280 DI_accelPedalPos "255";
BA_ "Confidence" SG_ 280 DI_tractionControlMode 0;
BA_ "Confidence" SG_ 280 DI_dynoModeAvailable 0;
BA_ "Confidence" SG_ 280 DI_epbRequest 0;
BA_ "Confidence" SG_ 280 DI_brakeSource 0;
BA_ "Confidence" SG_ 280 DI_keepDrivePowerStateRequest 0;
BA_ "Confidence" SG_ 280 DI_trackModeState 0;
BA_ "Confidence" SG_ 280 DI_autonomyControlActive 0;
BA_ "Confidence" SG_ 280 DI_regenLight 0;
BA_ "Confidence" SG_ 280 DI_vehicleAcceleration 0;
BA_ "GenSigSNA" SG_ 280 DI_vehicleAcceleration "2048";
BA_ "Confidence" SG_ 1992 EPBL_infoIndex 1;
BA_ "Confidence" SG_ 1992 EPBL_infoBuildType 0;
BA_ "Confidence" SG_ 1992 EPBL_infoBuildConfigId 0;
BA_ "Confidence" SG_ 1992 EPBL_infoHardwareId 0;
BA_ "Confidence" SG_ 1992 EPBL_infoComponentId 0;
BA_ "Confidence" SG_ 1992 EPBL_infoPcbaId 0;
BA_ "Confidence" SG_ 1992 EPBL_infoAssemblyId 0;
BA_ "GenSigSNA" SG_ 1992 EPBL_infoAssemblyId "255";
BA_ "Confidence" SG_ 1992 EPBL_infoUsageId 0;
BA_ "Confidence" SG_ 1992 EPBL_infoSubUsageId 0;
BA_ "Confidence" SG_ 1992 EPBL_infoAppCrc 0;
BA_ "Confidence" SG_ 1992 EPBL_infoAppGitHash 0;
BA_ "Confidence" SG_ 1992 EPBL_infoBootGitHash 0;
BA_ "Confidence" SG_ 1992 EPBL_infoPlatformType 0;
BA_ "Confidence" SG_ 1992 EPBL_infoBootUdsProtoVersion 0;
BA_ "Confidence" SG_ 1992 EPBL_infoBootCrc 0;
BA_ "Confidence" SG_ 648 EPBL_unitStatus 0;
BA_ "Confidence" SG_ 648 EPBL_unitFaultStatus 0;
BA_ "Confidence" SG_ 648 EPBL_summonState 0;
BA_ "Confidence" SG_ 648 EPBL_disconnected 0;
BA_ "Confidence" SG_ 648 EPBL_pistonTouchingRotor 0;
BA_ "Confidence" SG_ 648 EPBL_csmFaultReason 0;
BA_ "Confidence" SG_ 648 EPBL_esmOperationTrigger 0;
BA_ "Confidence" SG_ 648 EPBL_summonFaultReason 0;
BA_ "Confidence" SG_ 648 EPBL_localServiceModeActive 0;
BA_ "Confidence" SG_ 648 EPBL_localCdpState 0;
BA_ "Confidence" SG_ 648 EPBL_chimeRequestLocal 0;
BA_ "Confidence" SG_ 648 EPBL_telltaleLocal 0;
BA_ "GenSigSNA" SG_ 648 EPBL_telltaleLocal "7";
BA_ "Confidence" SG_ 648 EPBL_driverIsLeavingLocal 0;
BA_ "Confidence" SG_ 648 EPBL_driverIsLeavingAnySpeedLoca 0;
BA_ "SystemSignalLongSymbol" SG_ 648 EPBL_driverIsLeavingAnySpeedLoca "EPBL_driverIsLeavingAnySpeedLocal";
BA_ "Confidence" SG_ 648 EPBL_internalCDPRequest 0;
BA_ "Confidence" SG_ 648 EPBL_esmSpeedClass 0;
BA_ "Confidence" SG_ 648 EPBL_learnedEpbConfig 0;
BA_ "Confidence" SG_ 648 EPBL_internalStatusCounter 0;
BA_ "Confidence" SG_ 648 EPBL_internalStatusChecksum 0;
BA_ "Confidence" SG_ 743 EPBL_frontSeatCushionFanCur 0;
BA_ "Confidence" SG_ 743 EPBL_frontSeatBackrestFanCur 0;
BA_ "Confidence" SG_ 743 EPBL_frontSeatCushionFanDuty 0;
BA_ "Confidence" SG_ 743 EPBL_frontSeatCushionFanEn 0;
BA_ "Confidence" SG_ 743 EPBL_frontSeatBackrestFanEn 0;
BA_ "Confidence" SG_ 743 EPBL_frontSeatBackrestFanDuty 0;
VAL_ 530 BMS_contactorState 6 "BMS_CTRSET_BLOCKED" 5 "BMS_CTRSET_WELDED" 4 "BMS_CTRSET_CLOSED" 3 "BMS_CTRSET_CLOSING" 2 "BMS_CTRSET_OPENING" 1 "BMS_CTRSET_OPEN" 0 "BMS_CTRSET_SNA" ;
VAL_ 530 BMS_userChargeStatus 6 "BMS_CALIBRATING" 5 "BMS_CHARGE_STOPPED" 4 "BMS_CHARGE_COMPLETE" 3 "BMS_CHARGING" 2 "BMS_ABOUT_TO_CHARGE" 1 "BMS_NO_POWER" 0 "BMS_DISCONNECTED" ;
VAL_ 530 BMS_batteryInputPower 65535 "SNA" ;
VAL_ 530 BMS_state 10 "BMS_DIAG" 9 "BMS_SNA" 8 "BMS_TEST" 7 "BMS_WELD" 6 "BMS_FAULT" 5 "BMS_CLEAR_FAULT" 4 "BMS_FEIM" 3 "BMS_CHARGE" 2 "BMS_SUPPORT" 1 "BMS_DRIVE" 0 "BMS_STANDBY" ;
VAL_ 530 BMS_diLimpRequest 1 "LIMP_REQUEST_WELDED" 0 "LIMP_REQUEST_NONE" ;
VAL_ 530 BMS_chgPowerAvailable 4095 "SNA" ;
VAL_ 530 BMS_acManagerState 11 "FAULTED" 10 "OPEN_AC_RELAYS" 9 "DISABLE_PCS" 8 "GRID_FORM_ACTIVE" 7 "GRID_FOLLOW_ACTIVE" 6 "TETHERING_ACTIVE" 5 "CHARGING_ACTIVE" 4 "ENABLE_PCS" 3 "ENABLE_FC_LINK_FOR_AC" 2 "REQUEST_POWER_TRANSFER" 1 "STANDBY" 0 "INACTIVE" ;
VAL_ 530 BMS_smStateRequest 10 "BMS_DIAG" 9 "BMS_SNA" 8 "BMS_TEST" 7 "BMS_WELD" 6 "BMS_FAULT" 5 "BMS_CLEAR_FAULT" 4 "BMS_FEIM" 3 "BMS_CHARGE" 2 "BMS_SUPPORT" 1 "BMS_DRIVE" 0 "BMS_STANDBY" ;
VAL_ 530 BMS_hvState 6 "HV_UP" 5 "HV_UP_FOR_DC_CHARGE" 4 "HV_UP_FOR_CHARGE" 3 "HV_UP_FOR_DRIVE" 2 "HV_GOING_DOWN" 1 "HV_COMING_UP" 0 "HV_DOWN" ;
VAL_ 786 BMS_thermalStatusMultiplexer 1 "Mux1" 0 "Mux0" ;
VAL_ 754 BMS_nmKeepAwakeReason 8 "BMS_KEEPAWAKE_REASON_OTA" 7 "BMS_KEEPAWAKE_REASON_PRECONDITIONING" 6 "BMS_KEEPAWAKE_REASON_CP_ACTIVE" 5 "BMS_KEEPAWAKE_REASON_BMS_ACTIVE" 4 "BMS_KEEPAWAKE_REASON_HVP_ACTIVE" 3 "BMS_KEEPAWAKE_REASON_FC_CTR_CLEANING" 2 "BMS_KEEPAWAKE_REASON_CRITICAL_ALERT" 1 "BMS_KEEPAWAKE_REASON_CTRS_CLOSED" 0 "BMS_KEEPAWAKE_REASON_NONE_SNA" ;
VAL_ 754 BMS_nmWakeUpReason 4 "BMS_WAKEUP_REASON_CRITICALALERT" 3 "BMS_WAKEUP_REASON_WANTTOCHARGE" 2 "BMS_WAKEUP_REASON_CAN_HVS" 1 "BMS_WAKEUP_REASON_CAN_VEH" 0 "BMS_WAKEUP_REASON_NONE" ;
VAL_ 810 BMS_isolationResistance 1023 "SNA" ;
VAL_ 810 BMS_chgTimeToFull 4095 "SNA" ;
VAL_ 796 CC_currentLimit 255 "SNA" ;
VAL_ 796 CC_pilotState 3 "CC_PILOT_STATE_SNA" 2 "CC_PILOT_STATE_FAULTED" 1 "CC_PILOT_STATE_IDLE" 0 "CC_PILOT_STATE_READY" ;
VAL_ 796 CC_numPhases 0 "SNA" ;
VAL_ 796 CC_line1Voltage 511 "SNA" ;
VAL_ 796 CC_gridGrounding 2 "CC_GRID_GROUNDING_SNA" 1 "CC_GRID_GROUNDING_IT_SplitPhase" 0 "CC_GRID_GROUNDING_TN_TT" ;
VAL_ 796 CC_line2Voltage 511 "SNA" ;
VAL_ 796 CC_line3Voltage 511 "SNA" ;
VAL_ 796 CC_groundResistance 4095 "SNA" 4094 "NO_GROUND" ;
VAL_ 797 CC_chgStatus2Index 0 "Mux0" ;
VAL_ 797 CC_buttonState 1 "CC_BUTTON_PRESSED" 0 "CC_BUTTON_RELEASED" ;
VAL_ 797 EVSE_v2xSupport 2 "V2X_OVER_SWCAN" 1 "V2X_OVER_PLC" 0 "V2X_NOT_SUPPORTED" ;
VAL_ 797 EVSE_v2xSessionType 0 "SESSION_TYPE_SNA" ;
VAL_ 812 CC_logIndex 13 "Mux13" 12 "Mux12" 11 "Mux11" 10 "Mux10" 4 "Mux4" 3 "Mux3" 2 "Mux2" 1 "Mux1" 0 "Mux0" ;
VAL_ 812 CC_activeConnectorID 255 "SNA" ;
VAL_ 812 CC_temperature1 127 "SNA" ;
VAL_ 812 CC_temperature2 127 "SNA" ;
VAL_ 812 CC_temperature3 127 "SNA" ;
VAL_ 812 CC_contactor1Closed 3 "CC_CONTACTOR_SNA" 1 "CC_CONTACTOR_CLOSED" 0 "CC_CONTACTOR_OPEN" ;
VAL_ 812 CC_contactor2Closed 3 "CC_CONTACTOR_SNA" 1 "CC_CONTACTOR_CLOSED" 0 "CC_CONTACTOR_OPEN" ;
VAL_ 812 CC_temperature4 127 "SNA" ;
VAL_ 812 CC_conn1Current 255 "SNA" ;
VAL_ 812 CC_conn2Current 255 "SNA" ;
VAL_ 812 CC_conn3Current 255 "SNA" ;
VAL_ 812 CC_conn4Current 255 "SNA" ;
VAL_ 870 CMPD_infoIndex 255 "END" 31 "SUBCOMPONENT_GITHASH" 30 "PACKAGE_SN_8_14" 29 "PACKAGE_SN_1_7" 27 "PACKAGE_PN_15_20" 26 "PACKAGE_PN_8_14" 25 "PACKAGE_PN_1_7" 23 "SUBCOMPONENT2" 22 "VARIANTCRC" 20 "UDS_PROTOCOL_BOOTCRC" 19 "VERSION_DEPRECATED" 18 "BOOTLOADER_GITHASH" 17 "APP_GITHASH" 16 "SUBCOMPONENT" 15 "BOOTLOADER_CRC" 14 "BOOTLOADER_SVN" 13 "APP_CRC" 11 "PCBAID_ASSYID_USAGEID" 10 "BUILD_HWID_COMPONENTID" 9 "DEPRECATED_9" 8 "DEPRECATED_8" 7 "DEPRECATED_7" 6 "DEPRECATED_6" 5 "DEPRECATED_5" 4 "DEPRECATED_4" 3 "DEPRECATED_3" 2 "DEPRECATED_2" 1 "DEPRECATED_1" 0 "DEPRECATED_0" ;
VAL_ 870 CMPD_infoBuildType 4 "INFO_MFG_BUILD" 3 "INFO_TRACEABLE_CI_BUILD" 2 "INFO_LOCAL_BUILD" 1 "INFO_PLATFORM_BUILD" 0 "INFO_UNKNOWN_BUILD" ;
VAL_ 870 CMPD_infoAssemblyId 255 "ASSEMBLY_SNA" 1 "ASSEMBLY1" ;
VAL_ 679 CMPD_state 15 "CMPD_STATE_SNA" 4 "CMPD_STATE_IDLE" 3 "CMPD_STATE_FAULT" 2 "CMPD_STATE_STANDBY" 1 "CMPD_STATE_RUNNING" 0 "CMPD_STATE_INIT" ;
VAL_ 679 CMPD_wasteHeatState 3 "CMPD_WASTE_HEAT_STATE_UNUSED" 2 "CMPD_WASTE_HEAT_STATE_NOT_AVAILABLE" 1 "CMPD_WASTE_HEAT_STATE_ACTIVE" 0 "CMPD_WASTE_HEAT_STATE_OFF" ;
VAL_ 867 CMP_infoIndex 255 "END" 31 "SUBCOMPONENT_GITHASH" 30 "PACKAGE_SN_8_14" 29 "PACKAGE_SN_1_7" 27 "PACKAGE_PN_15_20" 26 "PACKAGE_PN_8_14" 25 "PACKAGE_PN_1_7" 23 "SUBCOMPONENT2" 22 "VARIANTCRC" 20 "UDS_PROTOCOL_BOOTCRC" 19 "VERSION_DEPRECATED" 18 "BOOTLOADER_GITHASH" 17 "APP_GITHASH" 16 "SUBCOMPONENT" 15 "BOOTLOADER_CRC" 14 "BOOTLOADER_SVN" 13 "APP_CRC" 11 "PCBAID_ASSYID_USAGEID" 10 "BUILD_HWID_COMPONENTID" 9 "DEPRECATED_9" 8 "DEPRECATED_8" 7 "DEPRECATED_7" 6 "DEPRECATED_6" 5 "DEPRECATED_5" 4 "DEPRECATED_4" 3 "DEPRECATED_3" 2 "DEPRECATED_2" 1 "DEPRECATED_1" 0 "DEPRECATED_0" ;
VAL_ 867 CMP_infoBuildType 4 "INFO_MFG_BUILD" 3 "INFO_TRACEABLE_CI_BUILD" 2 "INFO_LOCAL_BUILD" 1 "INFO_PLATFORM_BUILD" 0 "INFO_UNKNOWN_BUILD" ;
VAL_ 867 CMP_infoAssemblyId 255 "ASSEMBLY_SNA" 1 "ASSEMBLY1" ;
VAL_ 317 CP_powerTransferStatus 6 "CP_POWER_TRANSFER_FAULTED" 5 "CP_POWER_TRANSFER_ENABLED" 4 "CP_EVSE_TEST_PASSED" 3 "CP_EXT_EVSE_TEST_ACTIVE" 2 "CP_POWER_TRANSFER_STANDBY" 1 "CP_POWER_TRANSFER_CONNECTED" 0 "CP_POWER_TRANSFER_INACTIVE" ;
VAL_ 317 CP_powerTransferShutdownRequest 3 "EMERGENCY_SHUTDOWN_REQUESTED" 2 "ESCALATED_SHUTDOWN_REQUESTED" 1 "GRACEFUL_SHUTDOWN_REQUESTED" 0 "NO_SHUTDOWN_REQUESTED" ;
VAL_ 317 CP_evseAcControlMode 3 "AC_CTRL_MODE_GRID_FOLLOW" 2 "AC_CTRL_MODE_GRID_FORM" 1 "AC_CTRL_MODE_CHARGE_ONLY" 0 "AC_CTRL_MODE_NONE" ;
VAL_ 317 CP_evseChargeType 2 "AC_CHARGER_PRESENT" 1 "DC_CHARGER_PRESENT" 0 "NO_CHARGER_PRESENT" ;
VAL_ 317 CP_chgLimitMode 6 "CP_CHG_LIMIT_NUM" 5 "CP_CHG_LIMIT_ADAPTER_HW" 4 "CP_CHG_LIMIT_DEBUG_OVERRIDE" 3 "CP_CHG_LIMIT_ADAPTER_FOLDBACK" 2 "CP_CHG_LIMIT_THERMAL_FOLDBACK" 1 "CP_CHG_LIMIT_CABLE_UNSECURED" 0 "CP_CHG_LIMIT_HW" ;
VAL_ 669 CP_evseDeratingReason 31 "EVSE_DERATING_INVALID" 2 "EVSE_DERATING_POST_SYSTEM_FAULT" 1 "EVSE_DERATING_CABLE_TEMP_FOLDBACK" 0 "EVSE_DERATING_NONE" ;
VAL_ 541 CP_proximity 3 "CHG_PROXIMITY_LATCHED" 2 "CHG_PROXIMITY_UNLATCHED" 1 "CHG_PROXIMITY_DISCONNECTED" 0 "CHG_PROXIMITY_SNA" ;
VAL_ 541 CP_pilot 7 "CHG_PILOT_SNA" 6 "CHG_PILOT_UNUSED_6" 5 "CHG_PILOT_INVALID" 4 "CHG_PILOT_IDLE" 3 "CHG_PILOT_FAST_CHARGE" 2 "CHG_PILOT_LINE_CHARGE" 1 "CHG_PILOT_FAULTED" 0 "CHG_PILOT_NONE" ;
VAL_ 541 CP_cableType 5 "CHG_CABLE_TYPE_SNA" 4 "CHG_CABLE_TYPE_MCS" 3 "CHG_CABLE_TYPE_GB_DC" 2 "CHG_CABLE_TYPE_GB_AC" 1 "CHG_CABLE_TYPE_SAE" 0 "CHG_CABLE_TYPE_IEC" ;
VAL_ 541 CP_iecPilotState 9 "IEC_PILOT_SNA" 8 "IEC_PILOT_NUM" 7 "IEC_PILOT_F" 6 "IEC_PILOT_E" 5 "IEC_PILOT_C3" 4 "IEC_PILOT_C2" 3 "IEC_PILOT_C1" 2 "IEC_PILOT_B3" 1 "IEC_PILOT_B2" 0 "IEC_PILOT_B1" ;
VAL_ 541 CP_teslaSwcanState 8 "TESLA_SWCAN_V2L_ESTABLISHED" 7 "TESLA_SWCAN_V2L_RECEIVE" 6 "TESLA_SWCAN_OFFBOARD_UPDATE_IN_PROGRESS" 5 "TESLA_SWCAN_GO_TO_SLEEP" 4 "TESLA_SWCAN_FAULT" 3 "TESLA_SWCAN_ESTABLISHED" 2 "TESLA_SWCAN_RECEIVE" 1 "TESLA_SWCAN_ACCEPT" 0 "TESLA_SWCAN_INACTIVE" ;
VAL_ 541 CP_evseChargeType_UI 2 "AC_CHARGER_PRESENT" 1 "DC_CHARGER_PRESENT" 0 "NO_CHARGER_PRESENT" ;
VAL_ 541 CP_gbState 15 "GBDC_TESTER_PRESENT" 14 "GBDC_FAULTED" 13 "GBDC_RETRY_CHARGE" 12 "GBDC_ERROR_HANDLING" 11 "GBDC_END_OF_CHARGE" 10 "GBDC_CHARGE_DISABLING" 9 "GBDC_STOP_CHARGE_REQUESTED" 8 "GBDC_CHARGING" 7 "GBDC_READY_TO_CHARGE" 6 "GBDC_VEH_PACK_PRECHARGE" 5 "GBDC_CHARGE_PARAM_CONFIG" 4 "GBDC_RECOGNITION" 3 "GBDC_HANDSHAKING_EXT_ISO" 2 "GBDC_COMMS_RECEIVED" 1 "GBDC_WAIT_FOR_COMMS" 0 "GBDC_INACTIVE" ;
VAL_ 541 CP_gbdcStopChargeReason 8 "GBDC_PARAM_MISMATCH" 7 "GBDC_SUPERCHARGER_COMMS_TIMEOUT" 6 "GBDC_LIVE_DISCONNECT" 5 "GBDC_EVSE_CRITICAL_FAULT" 4 "GBDC_EVSE_FAULT" 3 "GBDC_COMMS_TIMEOUT" 2 "GBDC_EVSE_REQUESTED" 1 "GBDC_VEH_REQUESTED" 0 "GBDC_STOP_REASON_NONE" ;
VAL_ 541 CP_gbdcFailureReason 3 "GBDC_CRITICAL_FAILURE" 2 "GBDC_SHUTDOWN_FAILURE" 1 "GBDC_ATTEMPTS_EXPIRED" 0 "GBDC_FAILURE_NONE" ;
VAL_ 541 CP_acChargeState 6 "AC_CHARGE_FAULT" 5 "AC_CHARGE_VEH_SHUTDOWN" 4 "AC_CHARGE_ONBOARD_CHARGER_SHUTDOWN" 3 "AC_CHARGE_ENABLED" 2 "AC_CHARGE_STANDBY" 1 "AC_CHARGE_CONNECTED_CHARGE_BLOCKED" 0 "AC_CHARGE_INACTIVE" ;
VAL_ 541 CP_acChargeType 3 "AC_CHARGE_TYPE_COUNT" 2 "AC_CHARGE_CCS" 1 "AC_CHARGE_SWCAN" 0 "AC_CHARGE_LEGACY" ;
VAL_ 541 CP_teslaDcState 10 "TESLA_DC_FAULT" 9 "TESLA_DC_EMERGENCY_SHUTDOWN" 8 "TESLA_DC_VEH_SHUTDOWN" 7 "TESLA_DC_EVSE_SHUTDOWN" 6 "TESLA_DC_ENABLED" 5 "TESLA_DC_EXT_PRECHARGE_ACTIVE" 4 "TESLA_DC_EXT_TEST_ACTIVE" 3 "TESLA_DC_EXT_TESTS_ENABLED" 2 "TESLA_DC_STANDBY" 1 "TESLA_DC_CONNECTED_CHARGE_BLOCKED" 0 "TESLA_DC_INACTIVE" ;
VAL_ 733 CP_gridFormFrequencyRequest 4095 "SNA" ;
VAL_ 733 CP_gridFormL1NVoltageRequest 255 "SNA" ;
VAL_ 733 CP_gridFormGroundType 4 "CP_L1_L2_L3_MIDPOINT_GROUNDED_VEH_SIDE" 3 "CP_N_GROUNDED_EVSE_SIDE" 2 "CP_N_L1_MIDPOINT_GROUNDED_EVSE_SIDE" 1 "CP_NO_GROUNDING_EVSE_SIDE" 0 "GROUND_TYPE_SNA" ;
VAL_ 733 CP_gridFormGridType 4 "CP_P_L1L2_N_L3N_DC" 3 "CP_L1_L2_L3_THREE_PHASE" 2 "CP_N_L1_SPLIT_PHASE" 1 "CP_N_L1_SINGLE_PHASE" 0 "GRID_TYPE_SNA" ;
VAL_ 733 CP_powershareType 4 "POWERSHARE_TYPE_EPTO" 3 "POWERSHARE_TYPE_GRID" 2 "POWERSHARE_TYPE_HOME" 1 "POWERSHARE_TYPE_LOAD" 0 "POWERSHARE_TYPE_NONE" ;
VAL_ 733 CP_userPowershareStatus 5 "POWERSHARE_STOPPED" 4 "POWERSHARE_ENABLED_RECONNECTING_SOON" 3 "POWERSHARE_ENABLED" 2 "POWERSHARE_INITIALIZING" 1 "POWERSHARE_HANDSHAKING" 0 "POWERSHARE_INACTIVE" ;
VAL_ 733 CP_powershareStoppedReason 8 "POWERSHARE_STOP_REASON_AUTHENTICATION_FAILED" 7 "POWERSHARE_STOP_REASON_OFFBOARD_UPDATE" 6 "POWERSHARE_STOP_REASON_NOT_AUTHORIZED" 5 "POWERSHARE_STOP_REASON_GRID_RECONNECTING" 4 "POWERSHARE_STOP_REASON_USER" 3 "POWERSHARE_STOP_REASON_SOC_TOO_LOW" 2 "POWERSHARE_STOP_REASON_RETRY" 1 "POWERSHARE_STOP_REASON_FAULT" 0 "POWERSHARE_STOP_REASON_NONE" ;
VAL_ 1342 CP_infoIndex 255 "END" 31 "SUBCOMPONENT_GITHASH" 30 "PACKAGE_SN_8_14" 29 "PACKAGE_SN_1_7" 27 "PACKAGE_PN_15_20" 26 "PACKAGE_PN_8_14" 25 "PACKAGE_PN_1_7" 23 "SUBCOMPONENT2" 22 "VARIANTCRC" 20 "UDS_PROTOCOL_BOOTCRC" 19 "VERSION_DEPRECATED" 18 "BOOTLOADER_GITHASH" 17 "APP_GITHASH" 16 "SUBCOMPONENT" 15 "BOOTLOADER_CRC" 14 "BOOTLOADER_SVN" 13 "APP_CRC" 11 "PCBAID_ASSYID_USAGEID" 10 "BUILD_HWID_COMPONENTID" 9 "DEPRECATED_9" 8 "DEPRECATED_8" 7 "DEPRECATED_7" 6 "DEPRECATED_6" 5 "DEPRECATED_5" 4 "DEPRECATED_4" 3 "DEPRECATED_3" 2 "DEPRECATED_2" 1 "DEPRECATED_1" 0 "DEPRECATED_0" ;
VAL_ 1342 CP_buildType 4 "INFO_MFG_BUILD" 3 "INFO_TRACEABLE_CI_BUILD" 2 "INFO_LOCAL_BUILD" 1 "INFO_PLATFORM_BUILD" 0 "INFO_UNKNOWN_BUILD" ;
VAL_ 1885 CP_loggingFastSelect 6 "6" 5 "5" 4 "4" 3 "3" 2 "2" 1 "1" 0 "0" ;
VAL_ 1885 CP_chargeCablePresent 1 "CABLE_PRESENT" 0 "CABLE_NOT_PRESENT" ;
VAL_ 1885 CP_UHF_controlState 10 "CP_UHF_FAULT" 9 "CP_UHF_SLEEP" 8 "CP_UHF_HANDLE_FOUND" 7 "CP_UHF_READ_RXFIFO" 6 "CP_UHF_CHECK_RX" 5 "CP_UHF_RX" 4 "CP_UHF_PREPARE_RX" 3 "CP_UHF_CALIBRATE" 2 "CP_UHF_IDLE" 1 "CP_UHF_CONFIG" 0 "CP_UHF_INIT" ;
VAL_ 1885 CP_doorOpenRequest 8 "CPD_OPEN_REQ_NUM" 7 "CPD_OPEN_REQ_CABLE_RECONNECTED" 6 "CPD_OPEN_REQ_VCFRONT" 5 "CPD_OPEN_REQ_CLOSING_FAILED" 4 "CPD_OPEN_REQ_PUSH_TO_OPEN" 3 "CPD_OPEN_REQ_UHF" 2 "CPD_OPEN_REQ_SEC" 1 "CPD_OPEN_REQ_UI" 0 "CPD_OPEN_REQ_NONE" ;
VAL_ 1885 CP_doorOpenEndOfDriveReason 7 "CP_STOP_DRIVE_REASON_OVERCURRENT" 6 "CP_STOP_DRIVE_REASON_REQ_OVERRIDE" 5 "CP_STOP_DRIVE_REASON_ABSOLUTE_TIMEOUT" 4 "CP_STOP_DRIVE_REASON_MAX_TARGET_V" 3 "CP_STOP_DRIVE_REASON_REACHED_STOP" 2 "CP_STOP_DRIVE_REASON_STOPPED_MOVING_TIMEOUT" 1 "CP_STOP_DRIVE_REASON_STALLED" 0 "CP_STOP_DRIVE_REASON_NONE" ;
VAL_ 1885 CP_doorCloseEndOfDriveReason 7 "CP_STOP_DRIVE_REASON_OVERCURRENT" 6 "CP_STOP_DRIVE_REASON_REQ_OVERRIDE" 5 "CP_STOP_DRIVE_REASON_ABSOLUTE_TIMEOUT" 4 "CP_STOP_DRIVE_REASON_MAX_TARGET_V" 3 "CP_STOP_DRIVE_REASON_REACHED_STOP" 2 "CP_STOP_DRIVE_REASON_STOPPED_MOVING_TIMEOUT" 1 "CP_STOP_DRIVE_REASON_STALLED" 0 "CP_STOP_DRIVE_REASON_NONE" ;
VAL_ 1885 CP_doorCloseRequest 16 "CPD_CLOSE_REQ_NUM" 15 "CPD_CLOSE_REQ_COVER_OPEN" 14 "CPD_CLOSE_REQ_VCFRONT" 13 "CPD_CLOSE_REQ_OPEN_ON_WAKE" 12 "CPD_CLOSE_REQ_SENSOR_COMMS_RECOVERED" 11 "CPD_CLOSE_REQ_SENSOR_MISMATCH" 10 "CPD_CLOSE_REQ_INITIAL_CINCH" 9 "CPD_CLOSE_REQ_OPENED_IN_DRIVE_STATE" 8 "CPD_CLOSE_REQ_ENTER_DRIVE" 7 "CPD_CLOSE_REQ_FAULT_LINE" 6 "CPD_CLOSE_REQ_CAR_WASH" 5 "CPD_CLOSE_REQ_PUSH_TO_CLOSE" 4 "CPD_CLOSE_REQ_SEC" 3 "CPD_CLOSE_REQ_UI" 2 "CPD_CLOSE_REQ_DOOR_OPEN_TIMEOUT" 1 "CPD_CLOSE_REQ_CABLE_UNPLUGGED" 0 "CPD_CLOSE_REQ_NONE" ;
VAL_ 1885 CP_latchDisengagingStopReason 7 "CP_STOP_DRIVE_REASON_OVERCURRENT" 6 "CP_STOP_DRIVE_REASON_REQ_OVERRIDE" 5 "CP_STOP_DRIVE_REASON_ABSOLUTE_TIMEOUT" 4 "CP_STOP_DRIVE_REASON_MAX_TARGET_V" 3 "CP_STOP_DRIVE_REASON_REACHED_STOP" 2 "CP_STOP_DRIVE_REASON_STOPPED_MOVING_TIMEOUT" 1 "CP_STOP_DRIVE_REASON_STALLED" 0 "CP_STOP_DRIVE_REASON_NONE" ;
VAL_ 1885 CP_latchEngagingStopReason 7 "CP_STOP_DRIVE_REASON_OVERCURRENT" 6 "CP_STOP_DRIVE_REASON_REQ_OVERRIDE" 5 "CP_STOP_DRIVE_REASON_ABSOLUTE_TIMEOUT" 4 "CP_STOP_DRIVE_REASON_MAX_TARGET_V" 3 "CP_STOP_DRIVE_REASON_REACHED_STOP" 2 "CP_STOP_DRIVE_REASON_STOPPED_MOVING_TIMEOUT" 1 "CP_STOP_DRIVE_REASON_STALLED" 0 "CP_STOP_DRIVE_REASON_NONE" ;
VAL_ 1885 CP_doorIdDetectionState 2 "DOOR_ID_VALID" 1 "DOOR_ID_INVALID" 0 "DOOR_ID_UNKNOWN_SNA" ;
VAL_ 1885 CP_doorIdDetectedBin 3 "DOOR_ID_BIN_OPAL" 2 "DOOR_ID_BIN_HMC" 1 "DOOR_ID_BIN_NMB" 0 "DOOR_ID_BIN_UNKNOWN" ;
VAL_ 989 CP_loggingSlowSelect 8 "8" 7 "7" 6 "6" 5 "5" 4 "4" 3 "3" 2 "2" 1 "1" 0 "0" ;
VAL_ 989 CP_inlet1HarnessIdState 2 "HARNESS_PEDIGREE_VALID" 1 "HARNESS_PEDIGREE_INVALID" 0 "HARNESS_PEDIGREE_UNKNOWN_SNA" ;
VAL_ 989 CP_inlet2HarnessIdState 2 "HARNESS_PEDIGREE_VALID" 1 "HARNESS_PEDIGREE_INVALID" 0 "HARNESS_PEDIGREE_UNKNOWN_SNA" ;
VAL_ 989 CP_inletHeaterState 3 "INLET_HEATER_FAULTED" 2 "INLET_HEATER_ENABLED_LOWTEMP" 1 "INLET_HEATER_ENABLED_HIGHTEMP" 0 "INLET_HEATER_DISABLED" ;
VAL_ 989 CP_doorOpenLimiterMaxRequestType 8 "CPD_OPEN_REQ_NUM" 7 "CPD_OPEN_REQ_CABLE_RECONNECTED" 6 "CPD_OPEN_REQ_VCFRONT" 5 "CPD_OPEN_REQ_CLOSING_FAILED" 4 "CPD_OPEN_REQ_PUSH_TO_OPEN" 3 "CPD_OPEN_REQ_UHF" 2 "CPD_OPEN_REQ_SEC" 1 "CPD_OPEN_REQ_UI" 0 "CPD_OPEN_REQ_NONE" ;
VAL_ 989 CP_doorCloseLimiterMaxRequestTyp 16 "CPD_CLOSE_REQ_NUM" 15 "CPD_CLOSE_REQ_COVER_OPEN" 14 "CPD_CLOSE_REQ_VCFRONT" 13 "CPD_CLOSE_REQ_OPEN_ON_WAKE" 12 "CPD_CLOSE_REQ_SENSOR_COMMS_RECOVERED" 11 "CPD_CLOSE_REQ_SENSOR_MISMATCH" 10 "CPD_CLOSE_REQ_INITIAL_CINCH" 9 "CPD_CLOSE_REQ_OPENED_IN_DRIVE_STATE" 8 "CPD_CLOSE_REQ_ENTER_DRIVE" 7 "CPD_CLOSE_REQ_FAULT_LINE" 6 "CPD_CLOSE_REQ_CAR_WASH" 5 "CPD_CLOSE_REQ_PUSH_TO_CLOSE" 4 "CPD_CLOSE_REQ_SEC" 3 "CPD_CLOSE_REQ_UI" 2 "CPD_CLOSE_REQ_DOOR_OPEN_TIMEOUT" 1 "CPD_CLOSE_REQ_CABLE_UNPLUGGED" 0 "CPD_CLOSE_REQ_NONE" ;
VAL_ 605 CP_type 3 "CP_TYPE_IEC_CCS" 2 "CP_TYPE_GB" 1 "CP_TYPE_EURO_IEC" 0 "CP_TYPE_US_TESLA" ;
VAL_ 605 CP_latchState 3 "CP_LATCH_BLOCKING" 2 "CP_LATCH_ENGAGED" 1 "CP_LATCH_DISENGAGED" 0 "CP_LATCH_SNA" ;
VAL_ 605 CP_doorControlState 6 "CP_doorSenseClosed" 5 "CP_doorClosing" 4 "CP_doorSenseOpen" 3 "CP_doorOpening" 2 "CP_doorOpenRequested" 1 "CP_doorIdle" 0 "CP_doorInit" ;
VAL_ 605 CP_chargeCableState 2 "CHARGE_CABLE_CONNECTED" 1 "CHARGE_CABLE_NOT_CONNECTED" 0 "CHARGE_CABLE_UNKNOWN_SNA" ;
VAL_ 605 CP_latchControlState 5 "CP_latchEngaging" 4 "CP_latchDisengaged" 3 "CP_latchDisengaging" 2 "CP_latchDisengageRequested" 1 "CP_latchIdle" 0 "CP_latchInit" ;
VAL_ 605 CP_ledColor 13 "CP_LEDS_FLASHING_WHITE" 12 "CP_LEDS_FADING_OUT" 11 "CP_LEDS_FLASHING_PURPLE" 10 "CP_LEDS_FLASHING_BLUE" 9 "CP_LEDS_DEBUG" 8 "CP_LEDS_RAVE" 7 "CP_LEDS_AMBER" 6 "CP_LEDS_FLASHING_AMBER" 5 "CP_LEDS_FLASHING_GREEN" 4 "CP_LEDS_WHITE" 3 "CP_LEDS_BLUE" 2 "CP_LEDS_GREEN" 1 "CP_LEDS_RED" 0 "CP_LEDS_OFF" ;
VAL_ 605 CP_faultLineSensed 1 "FAULT_LINE_SET" 0 "FAULT_LINE_CLEARED" ;
VAL_ 605 CP_doorPresenceState 7 "CP_DOOR_PRESENCE_STATE_FAULT" 6 "CP_DOOR_PRESENCE_STATE_OFF_CHARGE" 5 "CP_DOOR_PRESENCE_STATE_OFF_DRIVE" 4 "CP_DOOR_PRESENCE_STATE_NOT_PRESENT" 3 "CP_DOOR_PRESENCE_STATE_PRESENT" 2 "CP_DOOR_PRESENCE_STATE_INIT_FROM_DRIVE" 1 "CP_DOOR_PRESENCE_STATE_INIT_FROM_CHARGE" 0 "CP_DOOR_PRESENCE_STATE_INIT" ;
VAL_ 605 CP_inductiveSensorState 7 "CP_INDUCTIVE_SENSOR_CONFIG" 6 "CP_INDUCTIVE_SENSOR_RESET" 5 "CP_INDUCTIVE_SENSOR_FAULT" 4 "CP_INDUCTIVE_SENSOR_WAIT_FOR_INIT" 3 "CP_INDUCTIVE_SENSOR_PAUSE" 2 "CP_INDUCTIVE_SENSOR_SHUTDOWN" 1 "CP_INDUCTIVE_SENSOR_POLL" 0 "CP_INDUCTIVE_SENSOR_INIT" ;
VAL_ 605 CP_coldWeatherMode 1 "CP_COLD_WEATHER_LATCH_MITIGATION" 0 "CP_COLD_WEATHER_NONE" ;
VAL_ 605 CP_inletHeaterUiState 4 "CP_HEATER_FAULTED" 3 "CP_HEATER_ENABLED" 2 "CP_HEATER_AVAILABLE" 1 "CP_HEATER_NOT_AVAILABLE" 0 "CP_HEATER_NOT_SUPPORTED" ;
VAL_ 605 CP_userEvseModelType 10 "EVSE_MODEL_V2L_ADAPTER" 9 "EVSE_MODEL_URBAN_CHARGER_V2" 8 "EVSE_MODEL_V2H_UWC" 7 "EVSE_MODEL_V2L_UMC3" 6 "EVSE_MODEL_TESLA_WC" 5 "EVSE_MODEL_TESLA_UMC" 4 "EVSE_MODEL_SUPERCHARGER_V4" 3 "EVSE_MODEL_SUPERCHARGER" 2 "EVSE_MODEL_GENERIC_FAST_CHARGER" 1 "EVSE_MODEL_GENERIC_CHARGER" 0 "EVSE_MODEL_NO_CHARGER" ;
VAL_ 605 CP_evseGridFormHardwareType 15 "EVSE_GRID_FORM_HARDWARE_SNA" 1 "EVSE_GRID_FORM_HARDWARE_V2LA" 0 "EVSE_GRID_FORM_HARDWARE_UMC3" ;
VAL_ 605 CP_AuthManagerState 8 "CP_AUTH_MANAGER_STATUS_ERROR" 7 "CP_AUTH_MANAGER_STATUS_SUCCESS" 6 "CP_AUTH_MANAGER_STATUS_VERIFYING_SIGNATURE" 5 "CP_AUTH_MANAGER_STATUS_WAITING_FOR_SIGNATURE" 4 "CP_AUTH_MANAGER_STATUS_WAITING_FOR_CHALLENGE" 3 "CP_AUTH_MANAGER_STATUS_VERIFYING_CERTIFICATE" 2 "CP_AUTH_MANAGER_STATUS_WAITING_FOR_CERTIFICATE" 1 "CP_AUTH_MANAGER_STATUS_IDLE" 0 "CP_AUTH_MANAGER_STATUS_INIT" ;
VAL_ 893 CP_thermalStatusSelect 1 "1" 0 "0" ;
VAL_ 893 CP_pinTemp4Velocity 511 "SNA" ;
VAL_ 1001 DAS_headlightRequest 3 "DAS_HEADLIGHT_REQUEST_INVALID" 2 "DAS_HEADLIGHT_REQUEST_TAIL_LIGHTS_ONLY" 1 "DAS_HEADLIGHT_REQUEST_ON" 0 "DAS_HEADLIGHT_REQUEST_OFF" ;
VAL_ 1001 DAS_hazardLightRequest 3 "DAS_REQUEST_HAZARDS_SNA" 2 "DAS_REQUEST_HAZARDS_ON_FAST" 1 "DAS_REQUEST_HAZARDS_ON" 0 "DAS_REQUEST_HAZARDS_OFF" ;
VAL_ 1001 DAS_wiperSpeed 15 "DAS_WIPER_SPEED_INVALID" 14 "DAS_WIPER_SPEED_14" 13 "DAS_WIPER_SPEED_13" 12 "DAS_WIPER_SPEED_12" 11 "DAS_WIPER_SPEED_11" 10 "DAS_WIPER_SPEED_10" 9 "DAS_WIPER_SPEED_9" 8 "DAS_WIPER_SPEED_8" 7 "DAS_WIPER_SPEED_7" 6 "DAS_WIPER_SPEED_6" 5 "DAS_WIPER_SPEED_5" 4 "DAS_WIPER_SPEED_4" 3 "DAS_WIPER_SPEED_3" 2 "DAS_WIPER_SPEED_2" 1 "DAS_WIPER_SPEED_1" 0 "DAS_WIPER_SPEED_OFF" ;
VAL_ 1001 DAS_turnIndicatorRequest 4 "DAS_TURN_INDICATOR_DEFER" 3 "DAS_TURN_INDICATOR_CANCEL" 2 "DAS_TURN_INDICATOR_RIGHT" 1 "DAS_TURN_INDICATOR_LEFT" 0 "DAS_TURN_INDICATOR_NONE" ;
VAL_ 1001 DAS_highLowBeamDecision 3 "DAS_HIGH_BEAM_SNA" 2 "DAS_HIGH_BEAM_ON" 1 "DAS_HIGH_BEAM_OFF" 0 "DAS_HIGH_BEAM_UNDECIDED" ;
VAL_ 1001 DAS_heaterRequest 2 "DAS_HEATER_ON" 1 "DAS_HEATER_OFF" 0 "DAS_HEATER_SNA" ;
VAL_ 1001 DAS_highLowBeamOffReason 5 "HIGH_BEAM_OFF_REASON_SNA" 4 "HIGH_BEAM_OFF_REASON_HEAD_LIGHT" 3 "HIGH_BEAM_OFF_REASON_AMBIENT_LIGHT" 2 "HIGH_BEAM_OFF_REASON_MOVING_RADAR_TARGET" 1 "HIGH_BEAM_OFF_REASON_MOVING_VISION_TARGET" 0 "HIGH_BEAM_ON" ;
VAL_ 1001 DAS_mirrorFoldRequest 3 "DAS_MIRROR_REQUEST_SNA" 2 "DAS_MIRROR_REQUEST_UNFOLD" 1 "DAS_MIRROR_REQUEST_FOLD" 0 "DAS_MIRROR_REQUEST_NONE" ;
VAL_ 1001 DAS_autoWiperState 5 "DAS_AUTO_WIPER_STATE_SNA" 4 "DAS_AUTO_WIPER_STATE_FAST_CONTINUOUS" 3 "DAS_AUTO_WIPER_STATE_SLOW_CONTINUOUS" 2 "DAS_AUTO_WIPER_STATE_FAST_INTERMITTENT" 1 "DAS_AUTO_WIPER_STATE_SLOW_INTERMITTENT" 0 "DAS_AUTO_WIPER_STATE_OFF" ;
VAL_ 1001 DAS_turnIndicatorRequestReason 24 "DAS_ACTIVE_SIMULTANEOUS_LANE_CHANGE_AVOIDANCE" 23 "DAS_ACTIVE_INFEASIBLE_KINEMATICS_LANE_CHANGE" 22 "DAS_ACTIVE_STAY_OUT_OF_RIGHTMOST_LANE_LANE_CHANGE" 21 "DAS_ACTIVE_AWAY_FROM_MERGE_LANE_CHANGE" 20 "DAS_ACTIVE_EXIT_RIGHT_LANE_LANE_CHANGE" 19 "DAS_ACTIVE_EXIT_PASSING_LANE_LANE_CHANGE" 18 "DAS_ACTIVE_INCORRECT_ROAD_SIDE_LANE_CHANGE" 17 "DAS_ACTIVE_STATIC_OBJECT_LANE_CHANGE" 15 "DAS_CANCEL_MANUAL_BLINKER" 14 "DAS_CANCEL_AUTO_PARK" 13 "DAS_ACTIVE_AUTO_PARK" 12 "DAS_CANCEL_SUMMMON" 11 "DAS_ACTIVE_SUMMMON" 10 "DAS_CANCEL_INTERSECTION" 9 "DAS_ACTIVE_INTERSECTION" 8 "DAS_ACTIVE_COMMANDED_LANE_CHANGE" 7 "DAS_CANCEL_MERGE" 6 "DAS_ACTIVE_MERGE" 5 "DAS_CANCEL_FORK" 4 "DAS_CANCEL_LANE_CHANGE" 3 "DAS_ACTIVE_FORK" 2 "DAS_ACTIVE_SPEED_LANE_CHANGE" 1 "DAS_ACTIVE_NAV_LANE_CHANGE" 0 "DAS_NONE" ;
VAL_ 1001 DAS_restrictDoorReleaseLeft 1 "RESTRICT_DOOR_RELEASE_ACTIVE" 0 "RESTRICT_DOOR_RELEASE_INACTIVE" ;
VAL_ 1001 DAS_restrictDoorReleaseRight 1 "RESTRICT_DOOR_RELEASE_ACTIVE" 0 "RESTRICT_DOOR_RELEASE_INACTIVE" ;
VAL_ 634 DIF_hvilStatus 3 "SNA" 2 "CLOSED" 1 "OPEN" 0 "DISABLED" ;
VAL_ 634 DIF_hvilSupplyState 2 "ACTIVE" 1 "INACTIVE" 0 "NOT_AVAILABLE" ;
VAL_ 634 DIF_vBatQF 1 "QUALIFIED" 0 "NOT_QUALIFIED" ;
VAL_ 634 DIF_powerStageSafeState 3 "PSTG_SAFESTATE_3PS_LOW" 2 "PSTG_SAFESTATE_3PS_HIGH" 1 "PSTG_SAFESTATE_ALL_OFF" 0 "PSTG_SAFESTATE_NONE" ;
VAL_ 634 DIF_fluxState 12 "DI_FLUXSTATE_DISABLED" 11 "DI_FLUXSTATE_MAGNET_FLUX_DETECT" 10 "DI_FLUXSTATE_STATIONARY_WASTE" 9 "DI_FLUXSTATE_FAULT" 7 "DI_FLUXSTATE_VCONTROL" 6 "DI_FLUXSTATE_ICONTROL" 5 "DI_FLUXSTATE_ENABLED" 4 "DI_FLUXSTATE_FLUX_DOWN" 3 "DI_FLUXSTATE_FLUX_UP" 2 "DI_FLUXSTATE_STANDBY" 1 "DI_FLUXSTATE_TEST" 0 "DI_FLUXSTATE_START" ;
VAL_ 634 DIF_gateDriveState 4 "PSTG_GD_STATE_NOT_CONFIGURED" 3 "PSTG_GD_STATE_CONFIGURED" 2 "PSTG_GD_STATE_CONFIGURING" 1 "PSTG_GD_STATE_SELFTEST" 0 "PSTG_GD_STATE_INIT" ;
VAL_ 634 DIF_gateDriveSupplyState 3 "PSTG_GD_SUPPLY_FALLING" 2 "PSTG_GD_SUPPLY_UP" 1 "PSTG_GD_SUPPLY_RISING" 0 "PSTG_GD_SUPPLY_DOWN" ;
VAL_ 741 DIF_elecPower -1024 "SNA" ;
VAL_ 741 DIF_drivePowerMax 511 "SNA" ;
VAL_ 886 DIF_tempIndex 4 "Mux4" 3 "Mux3" 2 "Mux2" 1 "Mux1" 0 "Mux0" ;
VAL_ 886 DIF_inverterTQF 3 "INVERTERT_UNKNOWN" 2 "INVERTERT_RATIONAL" 1 "INVERTERT_IRRATIONAL" 0 "INVERTERT_INIT" ;
VAL_ 886 DIF_pcbT 0 "SNA" ;
VAL_ 886 DIF_statorT 0 "SNA" ;
VAL_ 886 DIF_dcCapT 0 "SNA" ;
VAL_ 886 DIF_heatsinkT 0 "SNA" ;
VAL_ 886 DIF_fluidInTemp 0 "SNA" ;
VAL_ 886 DIF_normalFetBurnIn 65535 "SNA" ;
VAL_ 886 DIF_additionalFetBurnIn 65535 "SNA" ;
VAL_ 886 DIF_currentWeibullMiles 32767 "SNA" ;
VAL_ 886 DIF_endOfServiceWeibullMiles 32767 "SNA" ;
VAL_ 886 DIF_burnInDamageRatio 511 "SNA" 510 "DEFAULT_1" ;
VAL_ 886 DIF_initialBurnInVehicleOdometer 4294967295 "SNA" ;
VAL_ 886 DIF_statorHousingTemp 0 "SNA" ;
VAL_ 1367 DIF_oilFlowReq 255 "SNA" ;
VAL_ 1367 DIF_criticalFlowReq 1 "ACTIVE" 0 "NOT_ACTIVE" ;
VAL_ 1367 DIF_burnInStatus 5 "COMPLETE" 4 "ACTIVE" 3 "INCOMPLETE" 2 "UNAVAILABLE" 1 "NOT_REQUIRED" 0 "INIT" ;
VAL_ 2005 DIR_debugSelector 132 "Mux132" 131 "Mux131" 128 "Mux128" 73 "Mux73" 72 "Mux72" 70 "Mux70" 69 "Mux69" 68 "Mux68" 67 "Mux67" 66 "Mux66" 64 "Mux64" 63 "Mux63" 52 "Mux52" 50 "Mux50" 49 "Mux49" 48 "Mux48" 47 "Mux47" 46 "Mux46" 44 "Mux44" 43 "Mux43" 42 "Mux42" 41 "Mux41" 40 "Mux40" 39 "Mux39" 38 "Mux38" 37 "Mux37" 36 "Mux36" 35 "Mux35" 34 "Mux34" 33 "Mux33" 32 "Mux32" ;
VAL_ 2005 DIR_phaseOutBusbarTemp 0 "SNA" ;
VAL_ 2005 DIR_phaseOutBusbarWeldTemp 0 "SNA" ;
VAL_ 2005 DIR_phaseOutLugTemp 0 "SNA" ;
VAL_ 2005 DIR_dcLinkCapTemp 0 "SNA" ;
VAL_ 2005 DIR_hvDcCableTemp 0 "SNA" ;
VAL_ 2005 DIR_negDcBusbarTemp 0 "SNA" ;
VAL_ 2005 DIR_posDcBusbarTemp 0 "SNA" ;
VAL_ 2005 DIR_statorEndWindingTemp 0 "SNA" ;
VAL_ 2005 DIR_rotorMaxMagnetTemp 0 "SNA" ;
VAL_ 2005 DIR_statorSlotWindingTemp 0 "SNA" ;
VAL_ 633 DIR_hvilStatus 3 "SNA" 2 "CLOSED" 1 "OPEN" 0 "DISABLED" ;
VAL_ 633 DIR_hvilSupplyState 2 "ACTIVE" 1 "INACTIVE" 0 "NOT_AVAILABLE" ;
VAL_ 633 DIR_vBatQF 1 "QUALIFIED" 0 "NOT_QUALIFIED" ;
VAL_ 633 DIR_powerStageSafeState 3 "PSTG_SAFESTATE_3PS_LOW" 2 "PSTG_SAFESTATE_3PS_HIGH" 1 "PSTG_SAFESTATE_ALL_OFF" 0 "PSTG_SAFESTATE_NONE" ;
VAL_ 633 DIR_fluxState 12 "DI_FLUXSTATE_DISABLED" 11 "DI_FLUXSTATE_MAGNET_FLUX_DETECT" 10 "DI_FLUXSTATE_STATIONARY_WASTE" 9 "DI_FLUXSTATE_FAULT" 7 "DI_FLUXSTATE_VCONTROL" 6 "DI_FLUXSTATE_ICONTROL" 5 "DI_FLUXSTATE_ENABLED" 4 "DI_FLUXSTATE_FLUX_DOWN" 3 "DI_FLUXSTATE_FLUX_UP" 2 "DI_FLUXSTATE_STANDBY" 1 "DI_FLUXSTATE_TEST" 0 "DI_FLUXSTATE_START" ;
VAL_ 633 DIR_gateDriveState 4 "PSTG_GD_STATE_NOT_CONFIGURED" 3 "PSTG_GD_STATE_CONFIGURED" 2 "PSTG_GD_STATE_CONFIGURING" 1 "PSTG_GD_STATE_SELFTEST" 0 "PSTG_GD_STATE_INIT" ;
VAL_ 633 DIR_gateDriveSupplyState 3 "PSTG_GD_SUPPLY_FALLING" 2 "PSTG_GD_SUPPLY_UP" 1 "PSTG_GD_SUPPLY_RISING" 0 "PSTG_GD_SUPPLY_DOWN" ;
VAL_ 821 DIR_infoIndex 255 "INFO_END" 44 "TRACKING_DATA_5" 43 "TRACKING_DATA_4" 42 "TRACKING_DATA_3" 41 "TRACKING_DATA_2" 40 "TRACKING_DATA_1" 34 "INFO_SUBCOMPONENT2_HWID" 33 "INFO_SUBCOMPONENT_HWID" 32 "INFO_SUBCOMPONENT2_GITHASH" 31 "INFO_SUBCOMPONENT_GITHASH" 23 "INFO_SUBCOMPONENT2" 20 "INFO_UDS_PROTOCOL_BOOTCRC" 19 "INFO_VERSION_DEPRECATED" 18 "INFO_BOOTLOADER_GITHASH" 17 "INFO_APP_GITHASH" 16 "INFO_SUBCOMPONENT" 15 "INFO_BOOTLOADER_CRC" 14 "INFO_BOOTLOADER_SVN" 13 "INFO_APP_CRC" 11 "INFO_PCBAID_ASSYID_USAGEID" 10 "INFO_BUILD_HWID_COMPONENTID" 9 "INFO_DEPRECATED_9" 8 "INFO_DEPRECATED_8" 7 "INFO_DEPRECATED_7" 6 "INFO_DEPRECATED_6" 5 "INFO_DEPRECATED_5" 4 "INFO_DEPRECATED_4" 3 "INFO_DEPRECATED_3" 2 "INFO_DEPRECATED_2" 1 "INFO_DEPRECATED_1" 0 "INFO_DEPRECATED_0" ;
VAL_ 821 DIR_buildType 4 "INFO_MFG_BUILD" 3 "INFO_TRACEABLE_CI_BUILD" 2 "INFO_LOCAL_BUILD" 1 "INFO_PLATFORM_BUILD" 0 "INFO_UNKNOWN_BUILD" ;
VAL_ 821 DIR_hardwareId 252 "CONFIGURABLE_HWID_PLACEHOLDER" ;
VAL_ 821 DIR_motorType 36 "DI_MOTOR_PM240C" 35 "DI_MOTOR_IM188A" 34 "DI_MOTOR_IM130E_AL" 32 "DI_MOTOR_PM261D" 31 "DI_MOTOR_PM216E" 20 "DI_MOTOR_PM215D_1KV" 18 "DI_MOTOR_IM260E_1KV" 17 "DI_MOTOR_IM260D_1KV" 16 "DI_MOTOR_PM261C" 15 "DI_MOTOR_PM215C_1KV" 14 "DI_MOTOR_IM260C_1KV" 13 "DI_MOTOR_PM215A_1KV" 12 "DI_MOTOR_IM260A_1KV" 11 "DI_MOTOR_IM228HEA" 10 "DI_MOTOR_PM228HEA" 9 "DI_MOTOR_PM275C" 8 "DI_MOTOR_PM291D" 7 "DI_MOTOR_PM291C" 6 "DI_MOTOR_PM228C" 5 "DI_MOTOR_PM350B" 4 "DI_MOTOR_PM275B" 3 "DI_MOTOR_IM130D_AL" 2 "DI_MOTOR_IM130D" 1 "DI_MOTOR_PM216D" 0 "DI_MOTOR_SNA" ;
VAL_ 821 DIR_siliconType 1 "IGBT" 0 "MOSFET" ;
VAL_ 821 DIR_mechSafeStateType 2 "DI_MECH_SAFE_STATE_TYPE_PRESENT" 1 "DI_MECH_SAFE_STATE_TYPE_NONE" 0 "DI_MECH_SAFE_STATE_TYPE_SNA" ;
VAL_ 821 DIR_oilPumpBuildType 4 "INFO_MFG_BUILD" 3 "INFO_TRACEABLE_CI_BUILD" 2 "INFO_LOCAL_BUILD" 1 "INFO_PLATFORM_BUILD" 0 "INFO_UNKNOWN_BUILD" ;
VAL_ 821 DIR_FPGA_version 255 "SNA" 254 "LOCAL_BUILD" ;
VAL_ 821 DIR_refRotorOffset -2048 "SNA" ;
VAL_ 821 DIR_speedWearTotal 255 "SNA" ;
VAL_ 821 DIR_torqueWearTotal 255 "SNA" ;
VAL_ 917 DIR_oilPumpState 7 "OIL_PUMP_SNA" 6 "OIL_PUMP_FAULTED" 2 "OIL_PUMP_COLD_STARTUP" 1 "OIL_PUMP_ENABLE" 0 "OIL_PUMP_STANDBY" ;
VAL_ 917 DIR_oilPumpFluidTQF 1 "OIL_PUMP_FLUIDT_HIGH_CONFIDENCE" 0 "OIL_PUMP_FLUIDT_LOW_CONFIDENCE" ;
VAL_ 917 DIR_oilPumpFlowTarget 255 "SNA" ;
VAL_ 917 DIR_oilPumpFlowActual 255 "SNA" ;
VAL_ 917 DIR_oilPumpFluidT 255 "SNA" ;
VAL_ 917 DIR_oilPumpPhaseCurrent 255 "SNA" ;
VAL_ 917 DIR_oilPumpPressureEstimate 255 "SNA" ;
VAL_ 917 DIR_oilPumpPressureExpected 255 "SNA" ;
VAL_ 917 DIR_oilPumpPressureResidual 255 "SNA" ;
VAL_ 614 DIR_elecPower -1024 "SNA" ;
VAL_ 614 DIR_drivePowerMax 511 "SNA" ;
VAL_ 789 DIR_tempIndex 4 "Mux4" 3 "Mux3" 2 "Mux2" 1 "Mux1" 0 "Mux0" ;
VAL_ 789 DIR_inverterTQF 3 "INVERTERT_UNKNOWN" 2 "INVERTERT_RATIONAL" 1 "INVERTERT_IRRATIONAL" 0 "INVERTERT_INIT" ;
VAL_ 789 DIR_pcbT 0 "SNA" ;
VAL_ 789 DIR_statorT 0 "SNA" ;
VAL_ 789 DIR_dcCapT 0 "SNA" ;
VAL_ 789 DIR_heatsinkT 0 "SNA" ;
VAL_ 789 DIR_fluidInTemp 0 "SNA" ;
VAL_ 789 DIR_normalFetBurnIn 65535 "SNA" ;
VAL_ 789 DIR_additionalFetBurnIn 65535 "SNA" ;
VAL_ 789 DIR_currentWeibullMiles 32767 "SNA" ;
VAL_ 789 DIR_endOfServiceWeibullMiles 32767 "SNA" ;
VAL_ 789 DIR_burnInDamageRatio 511 "SNA" 510 "DEFAULT_1" ;
VAL_ 789 DIR_initialBurnInVehicleOdometer 4294967295 "SNA" ;
VAL_ 789 DIR_statorHousingTemp 0 "SNA" ;
VAL_ 1495 DIR_oilFlowReq 255 "SNA" ;
VAL_ 1495 DIR_criticalFlowReq 1 "ACTIVE" 0 "NOT_ACTIVE" ;
VAL_ 1495 DIR_burnInStatus 5 "COMPLETE" 4 "ACTIVE" 3 "INCOMPLETE" 2 "UNAVAILABLE" 1 "NOT_REQUIRED" 0 "INIT" ;
VAL_ 694 DI_vdcTelltaleFlash 1 "TELLTALE_ON" 0 "TELLTALE_OFF" ;
VAL_ 694 DI_vdcTelltaleOn 1 "TELLTALE_ON" 0 "TELLTALE_OFF" ;
VAL_ 694 DI_tcTelltaleFlash 1 "TELLTALE_ON" 0 "TELLTALE_OFF" ;
VAL_ 694 DI_tcTelltaleOn 1 "TELLTALE_ON" 0 "TELLTALE_OFF" ;
VAL_ 694 DI_tractionControlModeUI 7 "TC_SLIPPERY_SURFACE" 6 "TC_OFFROAD_ASSIST" 5 "TC_DYNO_MODE" 4 "TC_ROLLS_MODE" 3 "TC_DEV_MODE_2" 2 "TC_DEV_MODE_1" 1 "TC_SLIP_START" 0 "TC_NORMAL" ;
VAL_ 694 DI_ptcStateGlobalUI 3 "GLOBAL_PTC_STATE_SNA" 2 "GLOBAL_PTC_STATE_ON" 1 "GLOBAL_PTC_STATE_BACKUP" 0 "GLOBAL_PTC_STATE_FAULTED" ;
VAL_ 694 DI_btcStateUI 1 "ON" 0 "OFF" ;
VAL_ 694 DI_vehicleHoldTelltaleOn 1 "TELLTALE_ON" 0 "TELLTALE_OFF" ;
VAL_ 694 DI_slipperySurfaceOnUI 1 "SLIPPERY_SURFACE_ON" 0 "SLIPPERY_SURFACE_OFF" ;
VAL_ 694 DI_yellowBrakeTelltaleOn 1 "TELLTALE_ON" 0 "TELLTALE_OFF" ;
VAL_ 694 DI_greenABSTelltaleOn 1 "TELLTALE_ON" 0 "TELLTALE_OFF" ;
VAL_ 694 DI_stabilityModeState 2 "REDUCED" 1 "NORMAL" 0 "UNAVAILABLE" ;
VAL_ 2007 DI_debugSelector 75 "longControl" 69 "Mux69" 68 "Mux68" 67 "Mux67" 66 "Mux66" 65 "Mux65" 53 "Mux53" 50 "sysHeat" 45 "aeb" 39 "regenBackfill" 38 "pedalTorque1" 37 "onePedalDriving3" 36 "onePedalDriving2" 35 "onePedalDriving1" 34 "sysPedal" 33 "Mux33" 32 "pwrSat" 2 "Mux2" ;
VAL_ 2007 DI_regenBackfillUnavailableReaso 18 "DI_LATENT_FAULT_TRIP" 17 "EBR_FULL_FAULT" 16 "PM_DISABLE_REQUEST_BPED" 15 "PM_DISABLE_REQUEST_BLEND" 14 "CARBON_CERAMIC_BRAKES" 13 "BRAKE_TEMP" 12 "EBR_FAULT" 11 "PM_DISABLE_REQUEST" 10 "TRACK_MODE_ACTIVE" 9 "VELOCITY_ESTIMATOR_UNAVAILABLE" 8 "TRACTION_CONTROL_UNAVAILABLE" 7 "ACTIVE_DAMPING_UNAVAILABLE" 6 "UI_COASTDOWN_MODE" 5 "SYSTEM_STATE" 4 "NON_DRIVE_GEAR" 3 "EBR_UNAVAILABLE" 2 "UI_DISABLE" 1 "GTW_DISABLE" 0 "NONE" ;
VAL_ 2007 DI_regenBackfillAbsSatState 2 "RAMP_IN" 1 "RAMP_OUT" 0 "IDLE" ;
VAL_ 1022 DI_brakeFLTemp 1023 "SNA" ;
VAL_ 1022 DI_brakeFRTemp 1023 "SNA" ;
VAL_ 1022 DI_brakeRLTemp 1023 "SNA" ;
VAL_ 1022 DI_brakeRRTemp 1023 "SNA" ;
VAL_ 1623 DI_infoIndex 255 "INFO_END" 44 "TRACKING_DATA_5" 43 "TRACKING_DATA_4" 42 "TRACKING_DATA_3" 41 "TRACKING_DATA_2" 40 "TRACKING_DATA_1" 34 "INFO_SUBCOMPONENT2_HWID" 33 "INFO_SUBCOMPONENT_HWID" 32 "INFO_SUBCOMPONENT2_GITHASH" 31 "INFO_SUBCOMPONENT_GITHASH" 23 "INFO_SUBCOMPONENT2" 20 "INFO_UDS_PROTOCOL_BOOTCRC" 19 "INFO_VERSION_DEPRECATED" 18 "INFO_BOOTLOADER_GITHASH" 17 "INFO_APP_GITHASH" 16 "INFO_SUBCOMPONENT" 15 "INFO_BOOTLOADER_CRC" 14 "INFO_BOOTLOADER_SVN" 13 "INFO_APP_CRC" 11 "INFO_PCBAID_ASSYID_USAGEID" 10 "INFO_BUILD_HWID_COMPONENTID" 9 "INFO_DEPRECATED_9" 8 "INFO_DEPRECATED_8" 7 "INFO_DEPRECATED_7" 6 "INFO_DEPRECATED_6" 5 "INFO_DEPRECATED_5" 4 "INFO_DEPRECATED_4" 3 "INFO_DEPRECATED_3" 2 "INFO_DEPRECATED_2" 1 "INFO_DEPRECATED_1" 0 "INFO_DEPRECATED_0" ;
VAL_ 1623 DI_buildType 4 "INFO_MFG_BUILD" 3 "INFO_TRACEABLE_CI_BUILD" 2 "INFO_LOCAL_BUILD" 1 "INFO_PLATFORM_BUILD" 0 "INFO_UNKNOWN_BUILD" ;
VAL_ 1623 DI_hardwareId 252 "CONFIGURABLE_HWID_PLACEHOLDER" ;
VAL_ 950 DI_odometer 4294967295 "SNA" ;
VAL_ 296 DI_vehicleSpeedLimitType 2 "POWERTRAIN" 1 "USER" 0 "NONE" ;
VAL_ 296 DI_vehicleSpeedLimit 511 "SNA" ;
VAL_ 296 DI_vehicleSpeedLimitReason 16 "MANUAL_RECOVERY_MODE" 15 "FACTORY_BRAKE_BURNISHING" 14 "TAS_OFFROAD" 13 "SLIP_START_LIMIT" 12 "LV_DEGRADED" 11 "MAX_TIRE_TYPE" 10 "USER" 9 "FRUNK_OPEN" 8 "DAS_PEDAL_CONTROL" 7 "TAS" 6 "TRAILER_MODE" 5 "MAX_CAR_CONFIG" 4 "SERVICE_MODE" 3 "FACTORY_MODE" 2 "FACTORY_LOW_BRAKE_FLUID" 1 "DRIVE_UNIT_LIMIT" 0 "NONE" ;
VAL_ 296 DI_immobilizerAuthLevel 3 "IMMOBILIZER_AUTH_LEVEL_MANUAL_RECOVERY" 2 "IMMOBILIZER_AUTH_LEVEL_AUTONOMY" 1 "IMMOBILIZER_AUTH_LEVEL_USER_DRIVE" 0 "IMMOBILIZER_AUTH_LEVEL_NONE" ;
VAL_ 296 DI_manualRecoveryDistanceRemaini 127 "SNA" ;
VAL_ 296 DI_restrictedDrivingMode 1 "RESTRICTED_DRIVING_MANUAL_RECOVERY" 0 "RESTRICTED_DRIVING_MODE_NONE" ;
VAL_ 616 DI_sysDrivePowerMax 511 "SNA" ;
VAL_ 616 DI_primaryUnitSiliconType 1 "IGBT" 0 "MOSFET" ;
VAL_ 616 DI_sysRegenPowerMax 255 "SNA" ;
VAL_ 280 DI_secondaryGearControlStatus 1 "ACTIVE" 0 "NOT_ACTIVE" ;
VAL_ 280 DI_immobilizerState 6 "DI_IMM_STATE_FAULT" 5 "DI_IMM_STATE_RESET" 4 "DI_IMM_STATE_IDLE" 3 "DI_IMM_STATE_DISARMED" 2 "DI_IMM_STATE_AUTHENTICATING" 1 "DI_IMM_STATE_REQUEST" 0 "DI_IMM_STATE_INIT_SNA" ;
VAL_ 280 DI_systemState 5 "DI_SYS_ENABLE" 4 "DI_SYS_ABORT" 3 "DI_SYS_FAULT" 2 "DI_SYS_STANDBY" 1 "DI_SYS_IDLE" 0 "DI_SYS_UNAVAILABLE" ;
VAL_ 280 DI_brakePedalState 2 "INVALID" 1 "ON" 0 "OFF" ;
VAL_ 280 DI_gear 7 "DI_GEAR_SNA" 4 "DI_GEAR_D" 3 "DI_GEAR_N" 2 "DI_GEAR_R" 1 "DI_GEAR_P" 0 "DI_GEAR_INVALID" ;
VAL_ 280 DI_driveBlocked 4 "DRIVE_BLOCKED_TRUNK" 3 "DRIVE_BLOCKED_FALCON" 2 "DRIVE_BLOCKED_PROX" 1 "DRIVE_BLOCKED_FRUNK" 0 "DRIVE_BLOCKED_NONE" ;
VAL_ 280 DI_hvilSystemStatus 3 "SNA" 2 "CLOSED" 1 "OPEN" 0 "DISABLED" ;
VAL_ 280 DI_driveModeState 1 "DM_STATE_DRIVE" 0 "DM_STATE_NONDRIVE" ;
VAL_ 280 DI_shiftRequestType 3 "SMART_SHIFT" 2 "CCCM_SHIFT" 1 "GTW_SHIFT" 0 "NONE" ;
VAL_ 280 DI_accelPedalPos 255 "SNA" ;
VAL_ 280 DI_tractionControlMode 7 "TC_SLIPPERY_SURFACE" 6 "TC_OFFROAD_ASSIST" 5 "TC_DYNO_MODE" 4 "TC_ROLLS_MODE" 3 "TC_DEV_MODE_2" 2 "TC_DEV_MODE_1" 1 "TC_SLIP_START" 0 "TC_NORMAL" ;
VAL_ 280 DI_epbRequest 2 "DI_EPBREQUEST_UNPARK" 1 "DI_EPBREQUEST_PARK" 0 "DI_EPBREQUEST_NO_REQUEST" ;
VAL_ 280 DI_brakeSource 1 "DI" 0 "DAS" ;
VAL_ 280 DI_keepDrivePowerStateRequest 1 "KEEP_ALIVE" 0 "NO_REQUEST" ;
VAL_ 280 DI_trackModeState 2 "TRACK_MODE_ON" 1 "TRACK_MODE_AVAILABLE" 0 "TRACK_MODE_UNAVAILABLE" ;
VAL_ 280 DI_vehicleAcceleration -2048 "SNA" ;
VAL_ 1992 EPBL_infoIndex 255 "END" 41 "SUBCOMPONENT14" 40 "SUBCOMPONENT13" 39 "SUBCOMPONENT12" 38 "SUBCOMPONENT11" 37 "SUBCOMPONENT10" 36 "SUBCOMPONENT9" 35 "SUBCOMPONENT8" 34 "SUBCOMPONENT7" 33 "SUBCOMPONENT6" 32 "SUBCOMPONENT5" 31 "SUBCOMPONENT4" 24 "SUBCOMPONENT3" 23 "SUBCOMPONENT2" 20 "UDS_PROTOCOL_BOOTCRC" 19 "VERSION_DEPRECATED" 18 "BOOTLOADER_GITHASH" 17 "APP_GITHASH" 16 "SUBCOMPONENT1" 15 "BOOTLOADER_CRC" 14 "BOOTLOADER_SVN" 13 "APP_CRC" 11 "PCBAID_ASSYID_USAGEID" 10 "BUILD_HWID_COMPONENTID" 9 "DEPRECATED_9" 8 "DEPRECATED_8" 7 "DEPRECATED_7" 6 "DEPRECATED_6" 5 "DEPRECATED_5" 4 "DEPRECATED_4" 3 "DEPRECATED_3" 2 "DEPRECATED_2" 1 "DEPRECATED_1" 0 "DEPRECATED_0" ;
VAL_ 1992 EPBL_infoBuildType 4 "INFO_MFG_BUILD" 3 "INFO_TRACEABLE_CI_BUILD" 2 "INFO_LOCAL_BUILD" 1 "INFO_PLATFORM_BUILD" 0 "INFO_UNKNOWN_BUILD" ;
VAL_ 1992 EPBL_infoAssemblyId 255 "ASSEMBLY_SNA" 1 "ASSEMBLY1" ;
VAL_ 648 EPBL_unitStatus 23 "EPB_STATUS_COUNT" 22 "EPB_STATUS_AUTONOMY_OPEN" 21 "EPB_STATUS_FREE_ROLL_MODE" 20 "EPB_STATUS_DYNAMIC_PARKING" 19 "EPB_STATUS_EXTERNAL_PARKING" 18 "EPB_STATUS_RELEASING_FOR_EXTERNAL_PARK" 17 "EPB_STATUS_EXTERNAL_DYNAMIC" 16 "EPB_STATUS_SUMMON_PARKING" 15 "EPB_STATUS_SUMMON_RELEASING" 14 "EPB_STATUS_SUMMON" 13 "EPB_STATUS_WINCHMODE_PENDING" 12 "EPB_STATUS_PARK_PENDING" 11 "EPB_STATUS_SERVICE_RELEASING" 10 "EPB_STATUS_RELEASING" 9 "EPB_STATUS_DYNAMIC_APPLYING" 8 "EPB_STATUS_PARKING" 7 "EPB_STATUS_WINCHMODE_RELEASING" 6 "EPB_STATUS_WINCHMODE" 5 "EPB_STATUS_SERVICE" 4 "EPB_STATUS_START" 3 "EPB_STATUS_PARK" 2 "EPB_STATUS_DYNAMIC" 1 "EPB_STATUS_OPEN" 0 "EPB_STATUS_UNKNOWN" ;
VAL_ 648 EPBL_unitFaultStatus 3 "EPB_STATUS_FAULT_IDLE" 2 "EPB_STATUS_FAULT" 1 "EPB_STATUS_RETRY" 0 "EPB_STATUS_NOMINAL" ;
VAL_ 648 EPBL_summonState 6 "EPB_SUMMON_UNAVAILABLE" 5 "EPB_SUMMON_FAULT" 4 "EPB_SUMMON_COMPLETE" 3 "EPB_SUMMON_ACTIVE" 2 "EPB_SUMMON_ARMED" 1 "EPB_SUMMON_IDLE" 0 "EPB_SUMMON_INIT" ;
VAL_ 648 EPBL_csmFaultReason 23 "CSM_FAULT_REMOTE_MIA" 22 "CSM_FAULT_NVM_MISMATCH" 21 "CSM_FAULT_EPBM_MIA" 20 "CSM_FAULT_MOTOR_NOT_READY" 19 "CSM_FAULT_MOTOR_ACTIVE_FAULT" 18 "CSM_FAULT_MOTOR_IDLE_FAULT" 17 "CSM_FAULT_TIMEOUT_EPBM_START" 16 "CSM_FAULT_TIMEOUT_NO_RAMP" 15 "CSM_FAULT_TIMEOUT_EPBM_CUTOFF" 14 "CSM_FAULT_TIMEOUT_RELEASE_COMPLETE" 13 "CSM_FAULT_TIMEOUT_RELEASE_NO_LOAD" 12 "CSM_FAULT_TIMEOUT_RELEASE_WAIT_FOR_ENDSTOP" 11 "CSM_FAULT_TIMEOUT_RELEASE_INRUSH" 10 "CSM_FAULT_TIMEOUT_EPBM_WAIT_FOR_CLAMP" 9 "CSM_FAULT_TIMEOUT_EPB_WAIT_FOR_CLAMP" 8 "CSM_FAULT_TIMEOUT_APPLY_INRUSH" 7 "CSM_FAULT_TIMEOUT_APPLY_COMPLETE" 6 "CSM_FAULT_RELEASE_BLOCKED" 5 "CSM_FAULT_APPLY_BLOCKED" 4 "CSM_FAULT_TIMEOUT_CALIBRATE" 3 "CSM_FAULT_STATE_MISMATCH" 2 "CSM_FAULT_EPBM_FAULTED" 1 "CSM_FAULT_EPBM_DISABLED" 0 "CSM_FAULT_NONE" ;
VAL_ 648 EPBL_esmOperationTrigger 50 "EPB_TRIGGER_ACTIVE_DECEL_DAS_STATIC" 49 "EPB_TRIGGER_ACTIVE_DECEL_CDP_DOWN" 48 "EPB_TRIGGER_AP_IS_LEAVING" 47 "EPB_TRIGGER_RECOVERY_PARK" 46 "EPB_TRIGGER_SPEED_SOURCES_LOST" 45 "EPB_TRIGGER_ACTIVE_DECEL_OKTOPARK" 44 "EPB_TRIGGER_ACTIVE_DECEL_FAST" 43 "EPB_TRIGGER_STEERING_ACTIVE_DECEL" 42 "EPB_TRIGGER_LV_ACTIVE_DECEL" 41 "EPB_TRIGGER_CDP_PANIC_MODE_READY" 40 "EPB_TRIGGER_CDP_PANIC_MODE_TIMEOUT" 39 "EPB_TRIGGER_DI_PARK" 38 "EPB_TRIGGER_FREE_ROLL_PARK_FOR_HANDLE_PULLED" 37 "EPB_TRIGGER_LOW_BRAKE_FLUID_MODE_DYNAMIC" 36 "EPB_TRIGGER_LOW_BRAKE_FLUID_MODE_DYNAMIC_PARK" 35 "EPB_TRIGGER_LOW_BRAKE_FLUID_MODE_PARK" 34 "EPB_TRIGGER_STATIONARY_DETECT" 33 "EPB_TRIGGER_TOUCHSCREEN_INVALID" 32 "EPB_TRIGGER_UI_DOOR_OPEN_REQUEST" 31 "EPB_TRIGGER_AUTOPARK_END" 30 "EPB_TRIGGER_DRIVER_IS_LEAVING" 29 "EPB_TRIGGER_SYSTEM_APPLY" 28 "EPB_TRIGGER_ACCELERATION" 27 "EPB_TRIGGER_EPBM_DISQUALIFIED" 26 "EPB_TRIGGER_DISQUALIFIED" 25 "EPB_TRIGGER_SUMMON_FAULT" 24 "EPB_TRIGGER_FAULT" 23 "EPB_TRIGGER_SUMMON_COMPLETE" 22 "EPB_TRIGGER_REAPPLY" 21 "EPB_TRIGGER_SAVESTATE_ON_BOOT" 20 "EPB_TRIGGER_TIMEOUT" 19 "EPB_TRIGGER_SPEED_FAST" 18 "EPB_TRIGGER_SPEED_OKAYTOPARK" 17 "EPB_TRIGGER_SPEED_STOPPED" 16 "EPB_TRIGGER_USER_CANCEL" 15 "EPB_TRIGGER_USER_CONFIRMED" 14 "EPB_TRIGGER_DIAG_EXIT" 13 "EPB_TRIGGER_DIAG_OPEN" 12 "EPB_TRIGGER_DIAG_CLOSE" 11 "EPB_TRIGGER_SERVICE" 10 "EPB_TRIGGER_WINCHMODE_UNAVAILABLE" 9 "EPB_TRIGGER_WINCHMODE_ENTER" 8 "EPB_TRIGGER_WINCHMODE_EXIT" 7 "EPB_TRIGGER_TOUCHSCREEN" 6 "EPB_TRIGGER_DI_UNPARK" 5 "EPB_TRIGGER_ACTIVE_PARK_REQUEST" 4 "EPB_TRIGGER_PBUTTON_RELEASED" 3 "EPB_TRIGGER_PBUTTON_PRESSED_UNKNOWN" 2 "EPB_TRIGGER_PBUTTON_PRESSED_FAST" 1 "EPB_TRIGGER_PBUTTON_PRESSED_OKTOPARK" 0 "EPB_TRIGGER_PBUTTON_PRESSED_STOPPED" ;
VAL_ 648 EPBL_summonFaultReason 30 "EPB_SUMMONFAULT_MONITOR_TYPE_UNKNOWN" 29 "EPB_SUMMONFAULT_AP_MONITOR" 28 "EPB_SUMMONFAULT_REMOTE_DID_NOT_START" 27 "EPB_SUMMONFAULT_INVALID_REMOTE_STATE" 26 "EPB_SUMMONFAULT_START_IN_UNAVAILABLE" 25 "EPB_SUMMONFAULT_REMOTE_UNIT_FAULTED" 24 "EPB_SUMMONFAULT_LOCAL_UNIT_FAULTED" 23 "EPB_SUMMONFAULT_REMOTE_SUMMON_FAULTED" 22 "EPB_SUMMONFAULT_EPBREMOTE_MIA" 21 "EPB_SUMMONFAULT_PASSIVE_REQUEST" 20 "EPB_SUMMONFAULT_DI_STATE_INVALID" 19 "EPB_SUMMONFAULT_EPB_FAULT" 18 "EPB_SUMMONFAULT_MISMATCH" 17 "EPB_SUMMONFAULT_OOC" 16 "EPB_SUMMONFAULT_PM_REQUEST" 15 "EPB_SUMMONFAULT_PM_MIA" 14 "EPB_SUMMONFAULT_PARK_MIA" 13 "EPB_SUMMONFAULT_EXTERNAL" 12 "EPB_SUMMONFAULT_SPEED" 11 "EPB_SUMMONFAULT_EPBM_REQUEST" 10 "EPB_SUMMONFAULT_EAC_NOT_ALLOWED" 9 "EPB_SUMMONFAULT_VEH_CAN_FAULT" 8 "EPB_SUMMONFAULT_ESP_FAULT" 7 "EPB_SUMMONFAULT_DAS_FAULT" 6 "EPB_SUMMONFAULT_DI_APC_FAULT" 5 "EPB_SUMMONFAULT_DI_FAULT" 4 "EPB_SUMMONFAULT_EPBM_MIA" 3 "EPB_SUMMONFAULT_ESP_MIA" 2 "EPB_SUMMONFAULT_DAS_MIA" 1 "EPB_SUMMONFAULT_DI_MIA" 0 "EPB_SUMMONFAULT_NONE" ;
VAL_ 648 EPBL_localCdpState 2 "EPB_CDP_STATE_FAULT" 1 "EPB_CDP_STATE_VALID" 0 "EPB_CDP_STATE_UNKNOWN" ;
VAL_ 648 EPBL_chimeRequestLocal 4 "EPB_CHIME_REQUEST_ACTIVE_DECEL" 3 "EPB_CHIME_REQUEST_ABOUT_TO_ACTIVE_DECEL" 2 "EPB_CHIME_REQUEST_GPO" 1 "EPB_CHIME_REQUEST_GENERAL" 0 "EPB_CHIME_REQUEST_NONE" ;
VAL_ 648 EPBL_telltaleLocal 7 "EPB_TELLTALE_SNA" 4 "EPB_TELLTALE_LAMP_RED_FLASH" 3 "EPB_TELLTALE_LAMP_AMBER_ON" 2 "EPB_TELLTALE_LAMP_RED_ON" 1 "EPB_TELLTALE_LAMP_RED_PARKED" 0 "EPB_TELLTALE_LAMP_OFF" ;
VAL_ 648 EPBL_internalCDPRequest 1 "EPB_CDP_REQUESTED" 0 "EPB_CDP_NOT_REQUESTED" ;
VAL_ 648 EPBL_esmSpeedClass 4 "ESM_SPEED_CLASS_UNKNOWN" 3 "ESM_SPEED_CLASS_FAST" 2 "ESM_SPEED_CLASS_USER_APPLY_OK" 1 "ESM_SPEED_CLASS_SYSTEM_APPLY_OK" 0 "ESM_SPEED_CLASS_STOPPED" ;
VAL_ 648 EPBL_learnedEpbConfig 11 "EPB_CONFIG_CT_MANDO" 10 "EPB_CONFIG_MODEL3_ZF" 9 "EPB_CONFIG_MODELS_CERAMIC" 8 "EPB_CONFIG_MODELY_PERFORMANCE_V2" 7 "EPB_CONFIG_MODEL3_PERFORMANCE_V2" 6 "EPB_CONFIG_MODELX_BASE" 5 "EPB_CONFIG_MODELY_PERFORMANCE" 4 "EPB_CONFIG_MODELY_BASE" 3 "EPB_CONFIG_MODELS_BASE" 2 "EPB_CONFIG_MODEL3_PERFORMANCE" 1 "EPB_CONFIG_MODEL3_BASE" 0 "EPB_CONFIG_UNKNOWN" ;
